VERSION ""

NS_ :

BS_:

BU_: PPIM HCP VDCM APM2 SGW IDCM EVCU2 BPCM

BO_ 1835 HVBATTERY_RM_CELLS1: 64 BPCM
 SG_ HVBatCellVoltage_Cell027 : 420|13@0+ (0.001,0) [0|5] "V"  SGW
 SG_ HVBatCellVoltage_Cell026 : 404|13@0+ (0.001,0) [0|5] "V"  SGW
 SG_ HVBatCellVoltage_Cell025 : 388|13@0+ (0.001,0) [0|5] "V"  SGW
 SG_ HVBatCellVoltage_Cell024 : 372|13@0+ (0.001,0) [0|5] "V"  SGW
 SG_ HVBatCellVoltage_Cell023 : 356|13@0+ (0.001,0) [0|5] "V"  SGW
 SG_ HVBatCellVoltage_Cell022 : 340|13@0+ (0.001,0) [0|5] "V"  SGW
 SG_ HVBatCellVoltage_Cell021 : 324|13@0+ (0.001,0) [0|5] "V"  SGW
 SG_ HVBatCellVoltage_Cell020 : 308|13@0+ (0.001,0) [0|5] "V"  SGW
 SG_ HVBatCellVoltage_Cell019 : 292|13@0+ (0.001,0) [0|5] "V"  SGW
 SG_ HVBatCellVoltage_Cell018 : 276|13@0+ (0.001,0) [0|5] "V"  SGW
 SG_ HVBatCellVoltage_Cell017 : 260|13@0+ (0.001,0) [0|5] "V"  SGW
 SG_ HVBatCellVoltage_Cell016 : 244|13@0+ (0.001,0) [0|5] "V"  SGW
 SG_ HVBatCellVoltage_Cell015 : 228|13@0+ (0.001,0) [0|5] "V"  SGW
 SG_ HVBatCellVoltage_Cell014 : 212|13@0+ (0.001,0) [0|5] "V"  SGW
 SG_ HVBatCellVoltage_Cell013 : 196|13@0+ (0.001,0) [0|5] "V"  SGW
 SG_ HVBatCellVoltage_Cell012 : 180|13@0+ (0.001,0) [0|5] "V"  SGW
 SG_ HVBatCellVoltage_Cell011 : 164|13@0+ (0.001,0) [0|5] "V"  SGW
 SG_ HVBatCellVoltage_Cell010 : 148|13@0+ (0.001,0) [0|5] "V"  SGW
 SG_ HVBatCellVoltage_Cell009 : 132|13@0+ (0.001,0) [0|5] "V"  SGW
 SG_ HVBatCellVoltage_Cell008 : 116|13@0+ (0.001,0) [0|5] "V"  SGW
 SG_ HVBatCellVoltage_Cell007 : 100|13@0+ (0.001,0) [0|5] "V"  SGW
 SG_ HVBatCellVoltage_Cell006 : 84|13@0+ (0.001,0) [0|5] "V"  SGW
 SG_ HVBatCellVoltage_Cell005 : 68|13@0+ (0.001,0) [0|5] "V"  SGW
 SG_ HVBatCellVoltage_Cell004 : 52|13@0+ (0.001,0) [0|5] "V"  SGW
 SG_ HVBatCellVoltage_Cell003 : 36|13@0+ (0.001,0) [0|5] "V"  SGW
 SG_ HVBatCellVoltage_Cell002 : 20|13@0+ (0.001,0) [0|5] "V"  SGW
 SG_ HVBatCellVoltage_Cell001 : 4|13@0+ (0.001,0) [0|5] "V"  SGW

BO_ 1035 ENGINE_HYBD_FD_3: 32 HCP
 SG_ RadFanReq : 158|7@0+ (1,0) [0|100] "%"  BPCM
 SG_ EngSpd : 7|16@0+ (0.125,0) [0|8160] "rpm"  BPCM
 SG_ EngCltTmpV : 69|1@0+ (1,0) [0|1] "" BPCM
 SG_ EngCltTmp : 167|8@0+ (1,-40) [-40|214] "°C"  BPCM

BO_ 750 BCM_FD_3: 32 EVCU2
 SG_ Battery_Volt_1 : 56|9@0+ (0.025,5) [5|17.75] "Volt"  PPIM,APM2,IDCM,BPCM

BO_ 1436 BCM_FD_27: 32 HCP
 SG_ Blower_Speed : 136|9@0+ (1,0) [0|350] "Hz"  BPCM

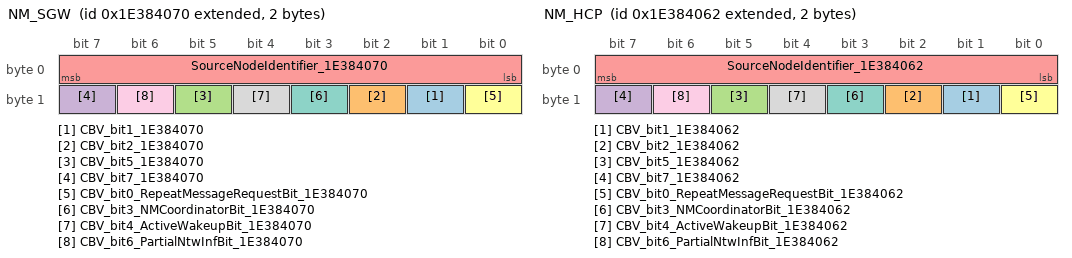
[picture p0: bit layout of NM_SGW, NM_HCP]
BO_ 2654486640 NM_SGW: 2 SGW
 SG_ CBV_bit1_1E384070 : 9|1@0+ (1,0) [0|1] "" EVCU2,APM2,IDCM,BPCM,HCP
 SG_ CBV_bit2_1E384070 : 10|1@0+ (1,0) [0|1] "" EVCU2,APM2,IDCM,BPCM,HCP
 SG_ CBV_bit5_1E384070 : 13|1@0+ (1,0) [0|1] "" EVCU2,APM2,IDCM,BPCM,HCP
 SG_ CBV_bit7_1E384070 : 15|1@0+ (1,0) [0|1] "" EVCU2,APM2,IDCM,BPCM,HCP
 SG_ SourceNodeIdentifier_1E384070 : 7|8@0+ (1,0) [0|255] "-"  EVCU2,APM2,IDCM,BPCM,HCP
 SG_ CBV_bit0_RepeatMessageRequestBit_1E384070 : 8|1@0+ (1,0) [0|1] "" EVCU2,APM2,IDCM,BPCM,HCP
 SG_ CBV_bit3_NMCoordinatorBit_1E384070 : 11|1@0+ (1,0) [0|1] "" EVCU2,APM2,IDCM,BPCM,HCP
 SG_ CBV_bit4_ActiveWakeupBit_1E384070 : 12|1@0+ (1,0) [0|1] "" EVCU2,APM2,IDCM,BPCM,HCP
 SG_ CBV_bit6_PartialNtwInfBit_1E384070 : 14|1@0+ (1,0) [0|1] "" EVCU2,APM2,IDCM,BPCM,HCP

BO_ 2654486626 NM_HCP: 2 HCP
 SG_ CBV_bit1_1E384062 : 9|1@0+ (1,0) [0|1] "" PPIM,EVCU2,IDCM,SGW,BPCM
 SG_ CBV_bit2_1E384062 : 10|1@0+ (1,0) [0|1] "" PPIM,EVCU2,IDCM,SGW,BPCM
 SG_ CBV_bit5_1E384062 : 13|1@0+ (1,0) [0|1] "" PPIM,EVCU2,IDCM,SGW,BPCM
 SG_ CBV_bit7_1E384062 : 15|1@0+ (1,0) [0|1] "" PPIM,EVCU2,IDCM,SGW,BPCM
 SG_ SourceNodeIdentifier_1E384062 : 7|8@0+ (1,0) [0|255] "-"  PPIM,EVCU2,IDCM,SGW,BPCM
 SG_ CBV_bit0_RepeatMessageRequestBit_1E384062 : 8|1@0+ (1,0) [0|1] "" PPIM,EVCU2,IDCM,SGW,BPCM
 SG_ CBV_bit3_NMCoordinatorBit_1E384062 : 11|1@0+ (1,0) [0|1] "" PPIM,EVCU2,IDCM,SGW,BPCM
 SG_ CBV_bit4_ActiveWakeupBit_1E384062 : 12|1@0+ (1,0) [0|1] "" PPIM,EVCU2,IDCM,SGW,BPCM
 SG_ CBV_bit6_PartialNtwInfBit_1E384062 : 14|1@0+ (1,0) [0|1] "" PPIM,EVCU2,IDCM,SGW,BPCM

BO_ 276 HYBRID_POWERTRAIN1: 64 EVCU2
 SG_ HEV_ESS_Mode : 271|4@0+ (1,0) [0|0] "-"  BPCM
 SG_ PropulsionSystemActive_114 : 408|1@0+ (1,0) [0|1] "-"  BPCM

BO_ 262 ENGINE_FD_2: 64 EVCU2
 SG_ PowertrainPrplsnActv : 181|1@0+ (1,0) [0|1] "" IDCM,BPCM
 SG_ EngineSpeed_W : 21|14@0+ (1,0) [0|16382] "1/min"  PPIM,IDCM,BPCM

BO_ 258 BRAKE_FD_2: 64 EVCU2
 SG_ VehicleSpeedVSOSig : 4|13@0+ (0.0625,0) [0|511.875] "Km/h"  PPIM,APM2,IDCM,BPCM

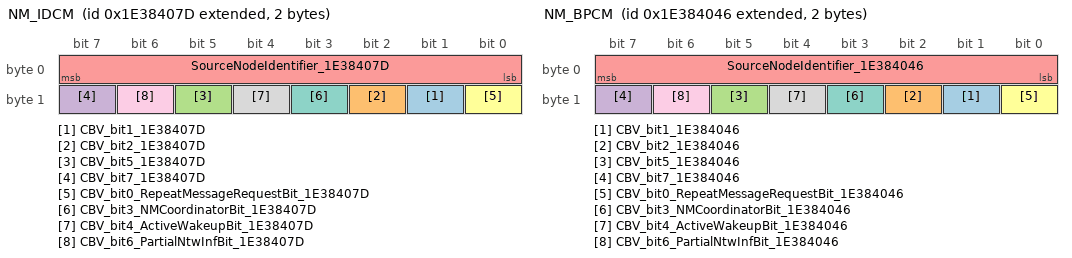
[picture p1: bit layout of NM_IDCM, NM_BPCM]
BO_ 2654486653 NM_IDCM: 2 IDCM
 SG_ CBV_bit1_1E38407D : 9|1@0+ (1,0) [0|1] "" PPIM,EVCU2,APM2,SGW,BPCM,HCP
 SG_ CBV_bit2_1E38407D : 10|1@0+ (1,0) [0|1] "" PPIM,EVCU2,APM2,SGW,BPCM,HCP
 SG_ CBV_bit5_1E38407D : 13|1@0+ (1,0) [0|1] "" PPIM,EVCU2,APM2,SGW,BPCM,HCP
 SG_ CBV_bit7_1E38407D : 15|1@0+ (1,0) [0|1] "" PPIM,EVCU2,APM2,SGW,BPCM,HCP
 SG_ SourceNodeIdentifier_1E38407D : 7|8@0+ (1,0) [0|255] "-"  PPIM,EVCU2,APM2,SGW,BPCM,HCP
 SG_ CBV_bit0_RepeatMessageRequestBit_1E38407D : 8|1@0+ (1,0) [0|1] "" PPIM,EVCU2,APM2,SGW,BPCM,HCP
 SG_ CBV_bit3_NMCoordinatorBit_1E38407D : 11|1@0+ (1,0) [0|1] "" PPIM,EVCU2,APM2,SGW,BPCM,HCP
 SG_ CBV_bit4_ActiveWakeupBit_1E38407D : 12|1@0+ (1,0) [0|1] "" PPIM,EVCU2,APM2,SGW,BPCM,HCP
 SG_ CBV_bit6_PartialNtwInfBit_1E38407D : 14|1@0+ (1,0) [0|1] "" PPIM,EVCU2,APM2,SGW,BPCM,HCP

BO_ 2654486598 NM_BPCM: 2 BPCM
 SG_ CBV_bit1_1E384046 : 9|1@0+ (1,0) [0|1] "" EVCU2,APM2,IDCM,SGW,HCP
 SG_ CBV_bit2_1E384046 : 10|1@0+ (1,0) [0|1] "" EVCU2,APM2,IDCM,SGW,HCP
 SG_ CBV_bit5_1E384046 : 13|1@0+ (1,0) [0|1] "" EVCU2,APM2,IDCM,SGW,HCP
 SG_ CBV_bit7_1E384046 : 15|1@0+ (1,0) [0|1] "" EVCU2,APM2,IDCM,SGW,HCP
 SG_ SourceNodeIdentifier_1E384046 : 7|8@0+ (1,0) [0|255] "-"  EVCU2,APM2,IDCM,SGW,HCP
 SG_ CBV_bit0_RepeatMessageRequestBit_1E384046 : 8|1@0+ (1,0) [0|1] "" EVCU2,APM2,IDCM,SGW,HCP
 SG_ CBV_bit3_NMCoordinatorBit_1E384046 : 11|1@0+ (1,0) [0|1] "" EVCU2,APM2,IDCM,SGW,HCP
 SG_ CBV_bit4_ActiveWakeupBit_1E384046 : 12|1@0+ (1,0) [0|1] "" EVCU2,APM2,IDCM,SGW,HCP
 SG_ CBV_bit6_PartialNtwInfBit_1E384046 : 14|1@0+ (1,0) [0|1] "" EVCU2,APM2,IDCM,SGW,HCP

BO_ 1579 HYBRID_CHARGING_STATUS: 32 EVCU2
 SG_ HVBatteryVoltage_MinCal : 32|9@0+ (1,0) [0|510] "V"  IDCM,BPCM
 SG_ HVBatteryVoltage_MaxCal : 16|9@0+ (1,0) [0|510] "V"  IDCM,BPCM
 SG_ HVBatteryCurrent_MaxCal : 63|8@0+ (0.25,-32) [-32|31.5] "Amp"  IDCM,BPCM
 SG_ ChargeSystemFaultReason : 55|8@0+ (1,0) [0|254] "-"  IDCM
 SG_ ACCurrent_MaxCal : 0|9@0+ (0.25,-31.5) [-31.5|50] "Amp"  IDCM,BPCM
 SG_ ChargingLevel : 4|4@0+ (1,0) [0|14] "-"  IDCM,SGW,BPCM
 SG_ OBCM_PLUG_STS : 23|2@0+ (1,0) [0|3] "" IDCM
 SG_ VDCM_UDCChrgr : 71|16@0+ (0.1,0) [0|6553.5] "V"  IDCM
 SG_ VDCM_IDCChrgr : 87|16@0+ (0.1,0) [0|6553.5] "A"  IDCM
 SG_ ChargeSystemSts : 7|3@0+ (1,0) [0|6] "-"  IDCM,BPCM
 SG_ ChargeSystemFault : 17|1@0+ (1,0) [0|1] "-"  IDCM
 SG_ CRC_HYBRID_CHARGING_STATUS : 191|8@0+ (1,0) [0|255] "-"  IDCM
 SG_ MessageCounter_HYBRID_CHARGING__62B : 179|4@0+ (1,0) [0|15] "-"  IDCM

BO_ 478 HYBRID_CHARGING_COMMAND: 32 EVCU2
 SG_ LVDC_VoltageSetpoint : 111|8@0+ (0.0625,0) [0|15.875] "V"  BPCM
 SG_ LVDC_SystemVoltageAct : 64|9@0+ (0.04,0) [0|20.04] "V"  BPCM
 SG_ LVDC_CurrentSetpoint : 32|9@0+ (1,-255) [-255|255] "Amp"  BPCM
 SG_ HVInverterVoltage_Rational : 16|9@0+ (1,0) [0|510] "V"  BPCM
 SG_ HVDC_VoltageSetpoint : 48|9@0+ (1,0) [0|510] "V"  BPCM
 SG_ HVDC_CurrentSetpoint : 103|8@0+ (1,-125) [-125|129] "Amp"  BPCM
 SG_ EchargeSOCRange_ePT : 118|7@0+ (1,0) [0|100] "%"  Vector__XXX
 SG_ CRC_HYBRID_CHARGING_COMMAND : 191|8@0+ (1,0) [0|255] "-"  IDCM,BPCM
 SG_ VoltageRequest : 4|13@0+ (0.1,0) [0|819.1] "Volts"  IDCM
 SG_ OBC_ModeRequest : 23|3@0+ (1,0) [0|6] "-"  IDCM
 SG_ OBC_ControlMethod : 38|2@0+ (1,0) [0|2] "-"  IDCM
 SG_ MainHV_ContactorCommand : 7|3@0+ (1,0) [0|7] "-"  BPCM
 SG_ J1772_CloseS2 : 51|1@0+ (1,0) [0|1] "-"  IDCM
 SG_ HVInverterVoltage_RationalV : 39|1@0+ (1,0) [0|1] "-"  BPCM
 SG_ HVBatCoolantLevelLow : 50|2@0+ (1,0) [0|2] "-"  BPCM
 SG_ DCDC_OperationModeEnable : 20|4@0+ (1,0) [0|14] "-"  BPCM
 SG_ ClearLegislatedDiagInfo : 52|1@0+ (1,0) [0|1] "-"  BPCM
 SG_ OBC_OperativeModeReq : 87|4@0+ (1,0) [0|14] "-"  IDCM
 SG_ HV_Volt_Min_Thrsh : 138|11@0+ (1,0) [0|2047] "V"  IDCM
 SG_ HV_Volt_Max_Thrsh : 133|11@0+ (1,0) [0|2047] "V"  IDCM
 SG_ DC_Curr_Max_Thrsh : 127|10@0+ (1,-511) [-511|512] "A"  IDCM
 SG_ ChargeEnable : 171|2@0+ (1,0) [0|2] "-"  IDCM
 SG_ AC_Curr_Min_Thrsh : 165|10@0+ (1,-511) [-511|512] "A"  IDCM
 SG_ AC_Curr_Max_Thrsh : 159|10@0+ (1,-511) [-511|512] "A"  IDCM
 SG_ CurrentRequest : 81|10@0+ (0.1,-32) [-32|70.3] "A"  IDCM
 SG_ VDCM_StsWldgReq : 83|1@0+ (1,0) [0|1] "-"  IDCM
 SG_ VDCM_SessnStopReq : 82|1@0+ (1,0) [0|1] "-"  IDCM
 SG_ VDCM_StsSWWldgReq : 55|2@0+ (1,0) [0|3] "-"  APM2
 SG_ MessageCounter_HYBRID_CHARGING__1DE : 179|4@0+ (1,0) [0|15] "-"  IDCM,BPCM
 SG_ MaxCurrentAllwd : 71|6@0+ (1,0) [0|63] "A"  IDCM

BO_ 1578 HV_CHARGER2: 32 IDCM
 SG_ OBC_IdleTimeSec : 71|16@0+ (3,0) [0|196602] "sec"  EVCU2
 SG_ OBC_IdleTimeMin : 87|16@0+ (1,0) [0|65534] "min"  EVCU2
 SG_ OBC_ChargeTimeSec : 39|16@0+ (3,0) [0|196602] "sec"  EVCU2
 SG_ OBC_ChargeTimeMin : 55|16@0+ (1,0) [0|65534] "min"  EVCU2
 SG_ Charging_WHr : 23|16@0+ (1,0) [0|65534] "WHr"  EVCU2
 SG_ OnboardChargerReady : 116|2@0+ (1,0) [0|2] "-"  EVCU2
 SG_ OnboardChargerMode : 114|4@0+ (1,0) [0|15] "-"  EVCU2
 SG_ OBC_WakeReason : 107|4@0+ (1,0) [0|7] "-"  EVCU2
 SG_ OBC_GenericFailSts : 125|1@0+ (1,0) [0|1] "-"  EVCU2
 SG_ OBC_FaultReason : 102|7@0+ (1,0) [0|126] "-"  EVCU2
 SG_ OBC_EVServiceLampOn : 124|1@0+ (1,0) [0|1] "-"  EVCU2
 SG_ OBC_EVServiceLampFlash : 123|1@0+ (1,0) [0|1] "-"  EVCU2
 SG_ OBC_CurrentFailureSts : 121|1@0+ (1,0) [0|1] "-"  EVCU2
 SG_ OBC_ChargingFaultSts : 110|3@0+ (1,0) [0|7] "-"  EVCU2
 SG_ OBC_ChargeFailure : 120|1@0+ (1,0) [0|1] "-"  EVCU2
 SG_ OBC_CaptureEnvironmentData : 119|1@0+ (1,0) [0|1] "-"  EVCU2
 SG_ ACplug_PwrMax : 7|16@0+ (1,-32767) [-32767|32767] "W"  EVCU2
 SG_ OBC_Prox : 159|8@0+ (0.05,0) [0|12.75] "V"  EVCU2
 SG_ OBC_Pilot : 151|8@0+ (0.05,0) [0|12.75] "V"  EVCU2
 SG_ OBCM_PrechargeSts : 167|2@0+ (1,0) [0|3] "-"  EVCU2
 SG_ ChrgFailSts : 165|3@0+ (1,0) [0|7] "" EVCU2
 SG_ CRC_HV_CHARGER2 : 191|8@0+ (1,0) [0|255] "-"  EVCU2
 SG_ MessageCounter_HV_CHARGER2 : 179|4@0+ (1,0) [0|15] "-"  EVCU2

BO_ 1372 DUALCHARGER_THERMAL: 32 IDCM
 SG_ OBC_Temp4 : 63|8@0+ (1,-40) [-40|214] "°C"  EVCU2
 SG_ OBC_Temp3 : 55|8@0+ (1,-40) [-40|214] "°C"  EVCU2
 SG_ OBC_Temp2 : 47|8@0+ (1,-40) [-40|214] "°C"  EVCU2
 SG_ OBC_Temp1 : 39|8@0+ (1,-40) [-40|214] "°C"  EVCU2

BO_ 2564682064 DIAGNOSTIC_ROE_IDCM: 8 IDCM
 SG_ N_PDU_18DDF150 : 7|64@0+ (1,0) [0|0] "" SGW

BO_ 2564682059 DIAGNOSTIC_ROE_HCP: 8 HCP
 SG_ N_PDU_18DDF14B : 7|64@0+ (1,0) [0|0] "" SGW

BO_ 2564682320 DIAGNOSTIC_ROE_FD_IDCM: 64 IDCM
 SG_ N_PDU_18DDF250 : 7|64@0+ (1,0) [0|0] "" SGW

BO_ 2564682315 DIAGNOSTIC_ROE_FD_HCP: 64 HCP
 SG_ N_PDU_18DDF24B : 7|64@0+ (1,0) [0|0] "" SGW

BO_ 2564682308 DIAGNOSTIC_ROE_FD_BPCM: 64 BPCM
 SG_ N_PDU_18DDF244 : 7|64@0+ (1,0) [0|0] "" SGW,HCP

BO_ 2564682052 DIAGNOSTIC_ROE_BPCM: 8 BPCM
 SG_ N_PDU_18DDF144 : 7|64@0+ (1,0) [0|0] "" SGW

BO_ 2564485712 DIAGNOSTIC_RESPONSE_FD_IDCM: 64 IDCM
 SG_ N_PDU_18DAF250 : 7|64@0+ (1,0) [0|0] "" SGW

BO_ 2564485707 DIAGNOSTIC_RESPONSE_FD_HCP: 64 HCP
 SG_ N_PDU_18DAF24B : 7|64@0+ (1,0) [0|0] "" SGW

BO_ 2564485700 DIAGNOSTIC_RESPONSE_FD_BPCM: 64 BPCM
 SG_ N_PDU_18DAF244 : 7|64@0+ (1,0) [0|0] "" SGW,HCP

BO_ 2564444402 DIAGNOSTIC_REQUEST_FD_IDCM: 64 SGW
 SG_ N_PDU_18DA50F2 : 7|64@0+ (1,0) [0|0] "" IDCM

BO_ 2564443122 DIAGNOSTIC_REQUEST_FD_HCP: 64 SGW
 SG_ N_PDU_18DA4BF2 : 7|64@0+ (1,0) [0|0] "" HCP

BO_ 2564441330 DIAGNOSTIC_REQUEST_FD_BPCM: 64 SGW
 SG_ N_PDU_18DA44F2 : 7|64@0+ (1,0) [0|0] "" BPCM

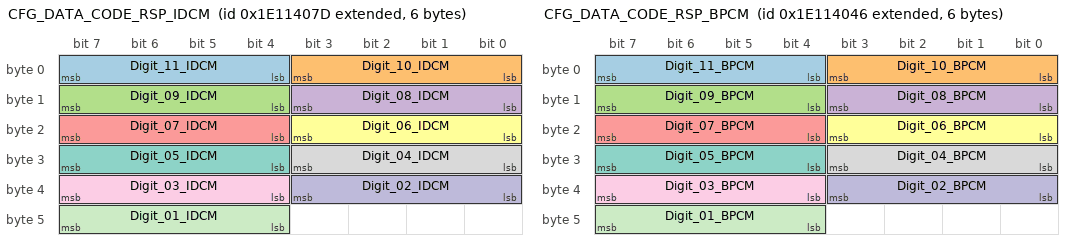
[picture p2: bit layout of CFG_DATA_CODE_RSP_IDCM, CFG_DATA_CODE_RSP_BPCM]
BO_ 2651930749 CFG_DATA_CODE_RSP_IDCM: 6 IDCM
 SG_ Digit_11_IDCM : 7|4@0+ (1,0) [0|15] "-"  EVCU2
 SG_ Digit_10_IDCM : 3|4@0+ (1,0) [0|15] "-"  EVCU2
 SG_ Digit_09_IDCM : 15|4@0+ (1,0) [0|15] "-"  EVCU2
 SG_ Digit_08_IDCM : 11|4@0+ (1,0) [0|15] "-"  EVCU2
 SG_ Digit_07_IDCM : 23|4@0+ (1,0) [0|15] "-"  EVCU2
 SG_ Digit_06_IDCM : 19|4@0+ (1,0) [0|15] "-"  EVCU2
 SG_ Digit_05_IDCM : 31|4@0+ (1,0) [0|15] "-"  EVCU2
 SG_ Digit_04_IDCM : 27|4@0+ (1,0) [0|15] "-"  EVCU2
 SG_ Digit_03_IDCM : 39|4@0+ (1,0) [0|15] "-"  EVCU2
 SG_ Digit_02_IDCM : 35|4@0+ (1,0) [0|15] "-"  EVCU2
 SG_ Digit_01_IDCM : 47|4@0+ (1,0) [0|15] "-"  EVCU2

BO_ 2651930694 CFG_DATA_CODE_RSP_BPCM: 6 BPCM
 SG_ Digit_11_BPCM : 7|4@0+ (1,0) [0|15] "-"  EVCU2,HCP
 SG_ Digit_10_BPCM : 3|4@0+ (1,0) [0|15] "-"  EVCU2,HCP
 SG_ Digit_09_BPCM : 15|4@0+ (1,0) [0|15] "-"  EVCU2,HCP
 SG_ Digit_08_BPCM : 11|4@0+ (1,0) [0|15] "-"  EVCU2,HCP
 SG_ Digit_07_BPCM : 23|4@0+ (1,0) [0|15] "-"  EVCU2,HCP
 SG_ Digit_06_BPCM : 19|4@0+ (1,0) [0|15] "-"  EVCU2,HCP
 SG_ Digit_05_BPCM : 31|4@0+ (1,0) [0|15] "-"  EVCU2,HCP
 SG_ Digit_04_BPCM : 27|4@0+ (1,0) [0|15] "-"  EVCU2,HCP
 SG_ Digit_03_BPCM : 39|4@0+ (1,0) [0|15] "-"  EVCU2,HCP
 SG_ Digit_02_BPCM : 35|4@0+ (1,0) [0|15] "-"  EVCU2,HCP
 SG_ Digit_01_BPCM : 47|4@0+ (1,0) [0|15] "-"  EVCU2,HCP

BO_ 2654339170 PDC_INFO_FD_HCP: 12 HCP
 SG_ GenericFailSts_FD03_HCP : 5|1@0+ (1,0) [0|1] "" SGW
 SG_ EOL_FD03_HCP : 7|1@0+ (1,0) [0|1] "-"  SGW
 SG_ CurrentFailSts_FD03_HCP : 6|1@0+ (1,0) [0|1] "" SGW
 SG_ WakeupSource_FD03_HCP : 23|8@0+ (1,0) [0|255] "" SGW
 SG_ PreviousCanNMState_FD03_HCP : 11|4@0+ (1,0) [0|15] "" SGW
 SG_ DES_FD03_HCP : 4|2@0+ (1,0) [0|3] "" SGW
 SG_ CurrentCanNMState_FD03_HCP : 15|4@0+ (1,0) [0|15] "" SGW
 SG_ StayActiveSource_FD03_HCP : 31|64@0+ (1,0) [0|18446744073709600000] "" SGW

BO_ 1845 HVBATTERY_RM_BATTERYID: 64 BPCM
 SG_ HVBatSerialLength : 199|8@0+ (1,0) [0|254] "" SGW
 SG_ HVBatSerialNumber : 7|192@0+ (1,0) [0|0] "" SGW

BO_ 1460 FOTA_MASTER: 32 SGW
 SG_ FOTA_Status : 7|4@0+ (1,0) [0|15] "" EVCU2,IDCM,BPCM
 SG_ MessageCounter_FOTA_MASTER : 179|4@0+ (1,0) [0|15] "-"  EVCU2
 SG_ CRC_FOTA_MASTER : 191|8@0+ (1,0) [0|255] "-"  EVCU2

BO_ 1374 HVBATTERY4: 48 BPCM
 SG_ HVBatPackVoltage_MaxAllowedV : 6|1@0+ (1,0) [0|0] "-"  HCP
 SG_ HVBatCellVoltage_MinAllowedV : 5|1@0+ (1,0) [0|0] "-"  HCP
 SG_ HVBatCellVoltage_MinAllowed : 19|12@0+ (0.001,1.5) [1.5|4.5] "Volts"  HCP
 SG_ HVBatCellVoltage_MaxAllowedV : 4|1@0+ (1,0) [0|0] "-"  HCP
 SG_ HVBatCellVoltage_MaxAllowed : 3|12@0+ (0.001,1.5) [1.5|4.5] "Volts"  HCP
 SG_ HVBatCellVoltage_LowThreshold : 84|13@0+ (0.001,0) [0|5] "Volts"  HCP
 SG_ HVBatCellVoltage_HighThreshold : 68|13@0+ (0.001,0) [0|5] "Volts"  HCP
 SG_ HVBatCapacity_AmpHrV : 22|1@0+ (1,0) [0|0] "-"  Vector__XXX
 SG_ HVBatCapacity_AmpHr : 114|11@0+ (0.1,0) [0|200] "Ah"  Vector__XXX
 SG_ MessageCounter_HVBATTERY4 : 307|4@0+ (1,0) [0|15] "-"  HCP
 SG_ CRC_HVBATTERY4 : 319|8@0+ (1,0) [0|255] "-"  HCP
 SG_ HVBatRemainingAhCapacity : 186|11@0+ (0.1,0) [0|200] "Ah"  HCP
 SG_ HVBatDischargeAmpHrs : 167|24@0+ (0.1,0) [0|300000] "Ah"  HCP
 SG_ HVBatChargeAmpHrs : 143|24@0+ (0.1,0) [0|300000] "Ah"  HCP
 SG_ BSGPackVoltage_MaxAllowed : 39|7@0+ (1,0) [20|70] "V"  HCP

BO_ 1038 HVBATTERY_STATUS: 32 BPCM
 SG_ Precharge_Closed : 121|1@0+ (1,0) [0|1] "" HCP
 SG_ Positive_Main_Closed : 122|1@0+ (1,0) [0|1] "" HCP
 SG_ Negative_Main_Closed : 123|1@0+ (1,0) [0|1] "" HCP
 SG_ HBCO_TempSensorRationality : 125|1@0+ (1,0) [0|1] "" HCP
 SG_ HBCO_Sensor_Fault : 126|1@0+ (1,0) [0|1] "" HCP
 SG_ HBCO_PackUndertemp : 105|1@0+ (1,0) [0|1] "" HCP
 SG_ HBCO_PackOvertemp : 106|1@0+ (1,0) [0|1] "" HCP
 SG_ HBCO_OverCurrent : 127|1@0+ (1,0) [0|1] "" HCP
 SG_ HBCO_Micro_Failure : 112|1@0+ (1,0) [0|1] "" HCP
 SG_ HBCO_Main_Fuse_Failure : 113|1@0+ (1,0) [0|1] "" HCP
 SG_ HBCO_Isolation_Fault : 114|1@0+ (1,0) [0|1] "" HCP
 SG_ HBCO_Internal_CommFault : 117|1@0+ (1,0) [0|1] "" HCP
 SG_ HBCO_Impact_Detected : 115|1@0+ (1,0) [0|1] "" HCP
 SG_ HBCO_HVIL_Failure : 116|1@0+ (1,0) [0|1] "" HCP
 SG_ HBCO_External_CommFault : 118|1@0+ (1,0) [0|1] "" HCP
 SG_ HBCO_CellUndervoltage : 119|1@0+ (1,0) [0|1] "" HCP
 SG_ HBCO_CellOvervoltage : 104|1@0+ (1,0) [0|1] "" HCP
 SG_ HBCO_12V_Low : 107|1@0+ (1,0) [0|1] "" HCP
 SG_ HBCO_12V_High : 108|1@0+ (1,0) [0|1] "" HCP
 SG_ HBCNC_TempSensorRationality : 110|1@0+ (1,0) [0|1] "" HCP
 SG_ HBCNC_SOH_Failure : 111|1@0+ (1,0) [0|1] "" HCP
 SG_ HBCNC_Sensor_Failure : 96|1@0+ (1,0) [0|1] "" HCP
 SG_ HBCNC_Precharge_Failure : 97|1@0+ (1,0) [0|1] "" HCP
 SG_ HBCNC_PackUndervoltage : 98|1@0+ (1,0) [0|1] "" HCP
 SG_ HBCNC_PackUndertemp : 93|1@0+ (1,0) [0|1] "" HCP
 SG_ HBCNC_PackOvervoltage : 99|1@0+ (1,0) [0|1] "" HCP
 SG_ HBCNC_PackOvertemp : 94|1@0+ (1,0) [0|1] "" HCP
 SG_ HBCNC_Micro_Failure : 100|1@0+ (1,0) [0|1] "" HCP
 SG_ HBCNC_Main_Fuse_Failure : 101|1@0+ (1,0) [0|1] "" HCP
 SG_ HBCNC_Isolation_Fault : 102|1@0+ (1,0) [0|1] "" HCP
 SG_ HBCNC_Internal_CommFault : 89|1@0+ (1,0) [0|1] "" HCP
 SG_ HBCNC_Impact_Detected : 103|1@0+ (1,0) [0|1] "" HCP
 SG_ HBCNC_External_CommFault : 90|1@0+ (1,0) [0|1] "" HCP
 SG_ HBCNC_EEPROM_Fault : 88|1@0+ (1,0) [0|1] "" HCP
 SG_ HBCNC_Contactors_Welded : 109|1@0+ (1,0) [0|1] "" HCP
 SG_ HBCNC_CellUndervoltage : 91|1@0+ (1,0) [0|1] "" HCP
 SG_ HBCNC_CellOvervoltage : 92|1@0+ (1,0) [0|1] "" HCP
 SG_ HBCNC_12V_Low : 95|1@0+ (1,0) [0|1] "" HCP
 SG_ HBCNC_12V_High : 38|1@0+ (1,0) [0|1] "" HCP
 SG_ BPCM_DTC_Status6 : 87|3@0+ (1,0) [0|6] "" HCP
 SG_ BPCM_DTC_Status5 : 79|3@0+ (1,0) [0|6] "" HCP
 SG_ BPCM_DTC_Status4 : 71|3@0+ (1,0) [0|6] "" HCP
 SG_ BPCM_DTC_Status3 : 63|3@0+ (1,0) [0|6] "" HCP
 SG_ BPCM_DTC_Status2 : 55|3@0+ (1,0) [0|6] "" HCP
 SG_ BPCM_DTC_Status1 : 47|3@0+ (1,0) [0|6] "" HCP
 SG_ BPCM_DTC_Index6 : 84|5@0+ (1,0) [0|31] "" HCP
 SG_ BPCM_DTC_Index5 : 76|5@0+ (1,0) [0|31] "" HCP
 SG_ BPCM_DTC_Index4 : 68|5@0+ (1,0) [0|31] "" HCP
 SG_ BPCM_DTC_Index3 : 60|5@0+ (1,0) [0|31] "" HCP
 SG_ BPCM_DTC_Index2 : 52|5@0+ (1,0) [0|31] "" HCP
 SG_ BPCM_DTC_Index1 : 44|5@0+ (1,0) [0|31] "" HCP
 SG_ BPCM_CalibrationVN : 31|8@0+ (1,0) [0|255] "" HCP
 SG_ BPCM_CalibrationID : 37|6@0+ (1,0) [0|62] "" HCP
 SG_ BPCM_Odometer : 7|24@0+ (0.1,0) [0|1677720] "km"  HCP

BO_ 2654339223 PDC_INFO_FD_APM2: 12 APM2
 SG_ WakeupSource_FD11_APM2 : 23|8@0+ (1,0) [0|255] "" EVCU2,SGW
 SG_ PreviousCanNMState_FD11_APM2 : 11|4@0+ (1,0) [0|15] "" EVCU2,SGW
 SG_ GenericFailSts_FD11_APM2 : 5|1@0+ (1,0) [0|1] "" EVCU2,SGW
 SG_ EOL_FD11_APM2 : 7|1@0+ (1,0) [0|1] "-"  EVCU2,SGW
 SG_ DES_FD11_APM2 : 4|2@0+ (1,0) [0|3] "" EVCU2,SGW
 SG_ CurrentFailSts_FD11_APM2 : 6|1@0+ (1,0) [0|1] "" EVCU2,SGW
 SG_ CurrentCanNMState_FD11_APM2 : 15|4@0+ (1,0) [0|15] "" EVCU2,SGW
 SG_ StayActiveSource_FD11_APM2 : 31|64@0+ (1,0) [0|18446744073709551615] "" EVCU2,SGW

BO_TX_BU_ 750 : EVCU2,HCP;
BO_TX_BU_ 276 : EVCU2,HCP;
BO_TX_BU_ 262 : EVCU2,HCP;
BO_TX_BU_ 258 : EVCU2,HCP;
BO_TX_BU_ 478 : EVCU2,HCP;
CM_ SG_ 2654339170 GenericFailSts_FD03_HCP "Indicates the presence/absent of at least one DTC in the System Memory";
CM_ SG_ 2654339170 EOL_FD03_HCP "Indicates if the ECU requires configuration data at the assembly plant End Of Line";
CM_ SG_ 2654339170 CurrentFailSts_FD03_HCP "Indicates the presence/absence of at least one DTC with DTCStatus = present in the System Memory";
CM_ SG_ 1835 HVBatCellVoltage_Cell027 "High voltage battery cell voltage for Cell 27";
CM_ SG_ 1835 HVBatCellVoltage_Cell026 "High voltage battery cell voltage for Cell 26";
CM_ SG_ 1835 HVBatCellVoltage_Cell025 "High voltage battery cell voltage for Cell 25";
CM_ SG_ 1835 HVBatCellVoltage_Cell024 "High voltage battery cell voltage for Cell 24";
CM_ SG_ 1835 HVBatCellVoltage_Cell023 "High voltage battery cell voltage for Cell 23";
CM_ SG_ 1835 HVBatCellVoltage_Cell022 "High voltage battery cell voltage for Cell 22";
CM_ SG_ 1835 HVBatCellVoltage_Cell021 "High voltage battery cell voltage for Cell 21";
CM_ SG_ 1835 HVBatCellVoltage_Cell020 "High voltage battery cell voltage for Cell 20";
CM_ SG_ 1835 HVBatCellVoltage_Cell019 "High voltage battery cell voltage for Cell 19";
CM_ SG_ 1835 HVBatCellVoltage_Cell018 "High voltage battery cell voltage for Cell 18";
CM_ SG_ 1835 HVBatCellVoltage_Cell017 "High voltage battery cell voltage for Cell 17";
CM_ SG_ 1835 HVBatCellVoltage_Cell016 "High voltage battery cell voltage for Cell 16";
CM_ SG_ 1835 HVBatCellVoltage_Cell015 "High voltage battery cell voltage for Cell 15";
CM_ SG_ 1835 HVBatCellVoltage_Cell014 "High voltage battery cell voltage for Cell 14";
CM_ SG_ 1835 HVBatCellVoltage_Cell013 "High voltage battery cell voltage for Cell 13";
CM_ SG_ 1835 HVBatCellVoltage_Cell012 "High voltage battery cell voltage for Cell 12";
CM_ SG_ 1835 HVBatCellVoltage_Cell011 "High voltage battery cell voltage for Cell 11";
CM_ SG_ 1835 HVBatCellVoltage_Cell010 "High voltage battery cell voltage for Cell 10";
CM_ SG_ 1835 HVBatCellVoltage_Cell009 "High voltage battery cell voltage for Cell 09";
CM_ SG_ 1835 HVBatCellVoltage_Cell008 "High voltage battery cell voltage for Cell 08";
CM_ SG_ 1835 HVBatCellVoltage_Cell007 "High voltage battery cell voltage for Cell 07";
CM_ SG_ 1835 HVBatCellVoltage_Cell006 "High voltage battery cell voltage for Cell 06";
CM_ SG_ 1835 HVBatCellVoltage_Cell005 "High voltage battery cell voltage for Cell 05";
CM_ SG_ 1835 HVBatCellVoltage_Cell004 "High voltage battery cell voltage for Cell 04";
CM_ SG_ 1835 HVBatCellVoltage_Cell003 "High voltage battery cell voltage for Cell 03";
CM_ SG_ 1835 HVBatCellVoltage_Cell002 "High voltage battery cell voltage for Cell 02";
CM_ SG_ 1835 HVBatCellVoltage_Cell001 "High voltage battery cell voltage for Cell 01";
CM_ SG_ 1035 RadFanReq "Radiator Fan request";
CM_ SG_ 1035 EngSpd "Engine speed";
CM_ SG_ 1035 EngCltTmpV "Engine Coolant Temperature Validity";
CM_ SG_ 1035 EngCltTmp "Engine Coolant Temp";
CM_ SG_ 750 Battery_Volt_1 "Battery Volt 1 signal";
CM_ SG_ 1436 Blower_Speed "Frequency Feedback received from the Blower";
CM_ SG_ 276 HEV_ESS_Mode "Engine start stop information:  engine start stop mode";
CM_ SG_ 262 PowertrainPrplsnActv "Powertrain Propulsion Status.";
CM_ SG_ 262 EngineSpeed_W "It gives information on C-CAN network about  engine speed";
CM_ SG_ 258 VehicleSpeedVSOSig "It is the average vehicle speed calculated.";
CM_ SG_ 1579 HVBatteryVoltage_MinCal "Minimum allowable HV battery voltage";
CM_ SG_ 1579 HVBatteryVoltage_MaxCal "Maximum allowable HV battery voltage";
CM_ SG_ 1579 HVBatteryCurrent_MaxCal "Maximum allowable HV battery current";
CM_ SG_ 1579 ChargeSystemFaultReason "Charge System Fault Reason";
CM_ SG_ 1579 ACCurrent_MaxCal "Maximum allowable AC current";
CM_ SG_ 478 LVDC_VoltageSetpoint "Low side voltage Setpoint";
CM_ SG_ 478 LVDC_SystemVoltageAct "System actual voltage";
CM_ SG_ 478 LVDC_CurrentSetpoint "Low side current Setpoint";
CM_ SG_ 478 HVInverterVoltage_Rational "??";
CM_ SG_ 478 HVDC_VoltageSetpoint "High side voltage set point";
CM_ SG_ 478 HVDC_CurrentSetpoint "High  side current Setpoint";
CM_ SG_ 478 EchargeSOCRange_ePT "Target SOC for ECharge";
CM_ SG_ 478 CRC_HYBRID_CHARGING_COMMAND "CRC according to SAE J1850 standard at each frame transmission.";
CM_ SG_ 1374 HVBatPackVoltage_MaxAllowedV "Maximum pack voltage allowed valid; Invalid = [1]";
CM_ SG_ 1374 HVBatCellVoltage_MinAllowedV "Minimum cell voltage allowed valid; Invalid = [1]";
CM_ SG_ 1374 HVBatCellVoltage_MinAllowed "Minimum cell voltage allowed";
CM_ SG_ 1374 HVBatCellVoltage_MaxAllowedV "Maximum cell voltage allowed valid; Invalid = [1]";
CM_ SG_ 1374 HVBatCellVoltage_MaxAllowed "Maximum cell voltage allowed";
CM_ SG_ 1374 HVBatCellVoltage_LowThreshold "Cell voltage low threshold";
CM_ SG_ 1374 HVBatCellVoltage_HighThreshold "Cell voltage high threshold";
CM_ SG_ 1374 HVBatCapacity_AmpHrV "Total HV battery amp hour capacity validity; Invalid = [1]";
CM_ SG_ 1374 HVBatCapacity_AmpHr "Total HV Battery Amp Hour Capacity";
CM_ SG_ 1578 OBC_IdleTimeSec "On board charger idle time";
CM_ SG_ 1578 OBC_IdleTimeMin "On board charger idle time - long";
CM_ SG_ 1578 OBC_ChargeTimeSec "On board charge time";
CM_ SG_ 1578 OBC_ChargeTimeMin "On board charge time - long";
CM_ SG_ 1578 Charging_WHr "Watt-hours of charge";
CM_ SG_ 1372 OBC_Temp4 "OBCM temperature sensor 3";
CM_ SG_ 1372 OBC_Temp3 "OBCM temperature sensor 4";
CM_ SG_ 1372 OBC_Temp2 "OBCM temperature sensor 2";
CM_ SG_ 1372 OBC_Temp1 "OBCM temperature sensor 1";
CM_ SG_ 1845 HVBatSerialLength "Length of the High Voltage Battery pack's serial number (number of ASCII characters)";
CM_ SG_ 1460 FOTA_Status "FOTA_Status";
CM_ SG_ 478 VoltageRequest "High Voltage Battery Voltage";
CM_ SG_ 1374 MessageCounter_HVBATTERY4 "This signal is a counter used for safety checks strategies. This counter is incremented of 1 (one) unit at each frame transmission.";
CM_ SG_ 1374 CRC_HVBATTERY4 "CRC according to SAE J1850 standard at each frame transmission.";
CM_ SG_ 276 PropulsionSystemActive_114 "Propulsion system active, [1] = active";
CM_ SG_ 2564682064 N_PDU_18DDF150 "This signal is used for diagnostic purposes";
CM_ SG_ 2564682059 N_PDU_18DDF14B "This signal is used for diagnostic purposes";
CM_ SG_ 2564682320 N_PDU_18DDF250 "This signal is used for diagnostic purposes";
CM_ SG_ 2564682315 N_PDU_18DDF24B "This signal is used for diagnostic purposes";
CM_ SG_ 2564682308 N_PDU_18DDF244 "This signal is used for diagnostic purposes";
CM_ SG_ 2564682052 N_PDU_18DDF144 "This signal is used for diagnostic purposes";
CM_ SG_ 2564485712 N_PDU_18DAF250 "This signal is used for diagnostic purposes";
CM_ SG_ 2564485707 N_PDU_18DAF24B "This signal is used for diagnostic purposes";
CM_ SG_ 2564485700 N_PDU_18DAF244 "This signal is used for diagnostic purposes";
CM_ SG_ 2564444402 N_PDU_18DA50F2 "This signal is used for diagnostic purposes";
CM_ SG_ 2564443122 N_PDU_18DA4BF2 "This signal is used for diagnostic purposes";
CM_ SG_ 2564441330 N_PDU_18DA44F2 "This signal is used for diagnostic purposes";
CM_ SG_ 2654339170 WakeupSource_FD03_HCP "Indicates the reason the ECU was most recently awakened";
CM_ SG_ 2654339170 PreviousCanNMState_FD03_HCP "Indicates the last CanNM state that the ECU existed in";
CM_ SG_ 2654339170 DES_FD03_HCP "Indicates whether the ECU?s CAN cell is in either ErrorActive, or ErrorPassive state OR has just now recovered from a BusOff condition";
CM_ SG_ 2654339170 CurrentCanNMState_FD03_HCP "Indicates that CanNM state the ECU is currently executing";
CM_ SG_ 1579 ChargingLevel "Charging level and type.";
CM_ SG_ 478 OBC_ModeRequest "Onboard charger mode request";
CM_ SG_ 478 OBC_ControlMethod "Onboard charger commanded control method";
CM_ SG_ 478 MainHV_ContactorCommand "High voltage battery contactor command";
CM_ SG_ 478 J1772_CloseS2 "J 1772 Close command";
CM_ SG_ 478 HVInverterVoltage_RationalV ".";
CM_ SG_ 478 HVBatCoolantLevelLow "Battery coolant level low";
CM_ SG_ 478 DCDC_OperationModeEnable "APM Operation Mode  Enable";
CM_ SG_ 478 ClearLegislatedDiagInfo "Clear Legislated Diagnostic Information";
CM_ SG_ 1374 HVBatRemainingAhCapacity "High voltage battery pack remaining amp hour capacity.";
CM_ SG_ 1374 HVBatDischargeAmpHrs "High voltage battery pack Amp Hours of discharge.";
CM_ SG_ 1374 HVBatChargeAmpHrs "High voltage battery pack Amp Hours of charge.";
CM_ SG_ 1374 BSGPackVoltage_MaxAllowed "Maximum pack voltage allowed";
CM_ SG_ 1038 Precharge_Closed "Precharge contactor is closed.";
CM_ SG_ 1038 Positive_Main_Closed "Positive main contactor is closed.";
CM_ SG_ 1038 Negative_Main_Closed "Negative main contactor is closed.";
CM_ SG_ 1038 HBCO_TempSensorRationality "Temperature sensor rationality.";
CM_ SG_ 1038 HBCO_Sensor_Fault "Sensor failure detected.";
CM_ SG_ 1038 HBCO_PackUndertemp "Battery undertemperature.";
CM_ SG_ 1038 HBCO_PackOvertemp "Battery overtemperature.";
CM_ SG_ 1038 HBCO_OverCurrent "Overcurrent condition detected.";
CM_ SG_ 1038 HBCO_Micro_Failure "Internal micro failures detected.";
CM_ SG_ 1038 HBCO_Main_Fuse_Failure "Main fuse (SD) is blown.";
CM_ SG_ 1038 HBCO_Isolation_Fault "Loss of isolation detected.";
CM_ SG_ 1038 HBCO_Internal_CommFault "Loss of Comm on the BPCM internal CAN bus.";
CM_ SG_ 1038 HBCO_Impact_Detected "Crash detection.";
CM_ SG_ 1038 HBCO_HVIL_Failure "HVIL Failure.";
CM_ SG_ 1038 HBCO_External_CommFault "Loss of Comm on the vehicle CAN bus.";
CM_ SG_ 1038 HBCO_CellUndervoltage "Cell voltage too low.";
CM_ SG_ 1038 HBCO_CellOvervoltage "Cell voltage too high.";
CM_ SG_ 1038 HBCO_12V_Low "12V too low.";
CM_ SG_ 1038 HBCO_12V_High "12V too high.";
CM_ SG_ 1038 HBCNC_TempSensorRationality "Temperature sensor rationality.";
CM_ SG_ 1038 HBCNC_SOH_Failure "State of Health failure.";
CM_ SG_ 1038 HBCNC_Sensor_Failure "Sensor failure detected.";
CM_ SG_ 1038 HBCNC_Precharge_Failure "Precharge failed.";
CM_ SG_ 1038 HBCNC_PackUndervoltage "Pack voltage too low.";
CM_ SG_ 1038 HBCNC_PackUndertemp "Battery undertemperature.";
CM_ SG_ 1038 HBCNC_PackOvervoltage "Pack voltage too high.";
CM_ SG_ 1038 HBCNC_PackOvertemp "Battery overtemperature.";
CM_ SG_ 1038 HBCNC_Micro_Failure "Internal micro failures detected.";
CM_ SG_ 1038 HBCNC_Main_Fuse_Failure "Main fuse (SD) is blown.";
CM_ SG_ 1038 HBCNC_Isolation_Fault "Loss of isolation detected.";
CM_ SG_ 1038 HBCNC_Internal_CommFault "Loss of Comm on the BPCM internal CAN bus.";
CM_ SG_ 1038 HBCNC_Impact_Detected "Crash detection.";
CM_ SG_ 1038 HBCNC_External_CommFault "Loss of Comm on the vehicle CAN bus.";
CM_ SG_ 1038 HBCNC_EEPROM_Fault "EEPROM fault or invalid signals detected.";
CM_ SG_ 1038 HBCNC_Contactors_Welded "Contactors welded.";
CM_ SG_ 1038 HBCNC_CellUndervoltage "Cell voltage too low.";
CM_ SG_ 1038 HBCNC_CellOvervoltage "Cell voltage too high.";
CM_ SG_ 1038 HBCNC_12V_Low "12V too low.";
CM_ SG_ 1038 HBCNC_12V_High "12V too high.";
CM_ SG_ 1038 BPCM_DTC_Status6 "Diagnostic Trouble Code status 6";
CM_ SG_ 1038 BPCM_DTC_Status5 "Diagnostic Trouble Code status 5";
CM_ SG_ 1038 BPCM_DTC_Status4 "Diagnostic Trouble Code status 4";
CM_ SG_ 1038 BPCM_DTC_Status3 "Diagnostic Trouble Code status 3";
CM_ SG_ 1038 BPCM_DTC_Status2 "Diagnostic Trouble Code status 2";
CM_ SG_ 1038 BPCM_DTC_Status1 "Diagnostic Trouble Code status 1";
CM_ SG_ 1038 BPCM_DTC_Index6 "Battery Pack DTC Index 6";
CM_ SG_ 1038 BPCM_DTC_Index5 "Battery Pack DTC Index 5";
CM_ SG_ 1038 BPCM_DTC_Index4 "Battery Pack DTC Index 4";
CM_ SG_ 1038 BPCM_DTC_Index3 "Battery Pack DTC Index 3";
CM_ SG_ 1038 BPCM_DTC_Index2 "Battery Pack DTC Index 2";
CM_ SG_ 1038 BPCM_DTC_Index1 "Battery Pack DTC Index 1";
CM_ SG_ 1038 BPCM_CalibrationVN "Battery Pack calibration verification number.";
CM_ SG_ 1038 BPCM_CalibrationID "Battery Pack calibration ID index.";
CM_ SG_ 2654339223 WakeupSource_FD11_APM2 "Indicates the reason the ECU was most recently awakened";
CM_ SG_ 2654339223 PreviousCanNMState_FD11_APM2 "Indicates the last CanNM state that the ECU existed in";
CM_ SG_ 2654339223 GenericFailSts_FD11_APM2 "Indicates the presence/absent of at least one DTC in the System Memory";
CM_ SG_ 2654339223 EOL_FD11_APM2 "Indicates if the ECU requires configuration data at the assembly plant End Of Line";
CM_ SG_ 2654339223 DES_FD11_APM2 "Indicates whether the ECU?s CAN cell is in either ErrorActive, or ErrorPassive state OR has just now recovered from a BusOff condition";
CM_ SG_ 2654339223 CurrentFailSts_FD11_APM2 "Indicates the presence/absence of at least one DTC with DTCStatus = present in the System Memory";
CM_ SG_ 2654339223 CurrentCanNMState_FD11_APM2 "Indicates that CanNM state the ECU is currently executing";
CM_ SG_ 1579 OBCM_PLUG_STS "Plug Status retrieved by the VDCM according to the proximity Sts and pilot Sts and current input available sent by the OBCM";
CM_ SG_ 478 OBC_OperativeModeReq "This signal indicates the Onboard charger mode request";
CM_ SG_ 478 HV_Volt_Min_Thrsh "This signal indicates the Commanded minimum Traction Battery Voltage to On Board Charger.";
CM_ SG_ 478 HV_Volt_Max_Thrsh "This signal indicates the Commanded maximum Traction Battery Voltage to On Board Charger.";
CM_ SG_ 478 DC_Curr_Max_Thrsh "Maximum Threshold for charging DC current.";
CM_ SG_ 478 ChargeEnable "Charge Enable";
CM_ SG_ 478 AC_Curr_Min_Thrsh "Commanded AC current min threshold to On Board Charge";
CM_ SG_ 478 AC_Curr_Max_Thrsh "Commanded AC current max threshold to On Board Charge";
CM_ SG_ 1578 OnboardChargerReady "OBCM Ready status";
CM_ SG_ 1578 OnboardChargerMode "OBCM operative mode";
CM_ SG_ 1578 OBC_WakeReason "OBCM wakeup status";
CM_ SG_ 1578 OBC_GenericFailSts ".";
CM_ SG_ 1578 OBC_FaultReason "OBCM Fault Reason";
CM_ SG_ 1578 OBC_EVServiceLampOn "Ev service On request from OBCM";
CM_ SG_ 1578 OBC_EVServiceLampFlash "Ev service LIGHT flash from OBCM";
CM_ SG_ 1578 OBC_CurrentFailureSts ".";
CM_ SG_ 1578 OBC_ChargingFaultSts "OBCM charging fault status";
CM_ SG_ 1578 OBC_ChargeFailure "0 = Open, 1 = Off/SNA";
CM_ SG_ 1578 OBC_CaptureEnvironmentData "Capture Environmental Data";
CM_ SG_ 1578 ACplug_PwrMax "Maximum  AC power limit";
CM_ SG_ 2654486640 SourceNodeIdentifier_1E384070 "Source Node Identifier";
CM_ SG_ 2654486653 SourceNodeIdentifier_1E38407D "Source Node Identifier";
CM_ SG_ 2654486626 SourceNodeIdentifier_1E384062 "Source Node Identifier";
CM_ SG_ 2654486598 SourceNodeIdentifier_1E384046 "Source Node Identifier";
CM_ SG_ 478 CurrentRequest "HCP current request to the on board charger";
CM_ SG_ 1038 BPCM_Odometer "Battery Pack odometer (kilometers driven).";
CM_ SG_ 1579 VDCM_UDCChrgr "For comm with charging station type B";
CM_ SG_ 1579 VDCM_IDCChrgr "For comm with charging station type B";
CM_ SG_ 1579 ChargeSystemSts "Charging System status";
CM_ SG_ 1579 ChargeSystemFault "Charging System Fault status";
CM_ SG_ 478 VDCM_StsWldgReq "This signal indicates the welding check request from VDCM";
CM_ SG_ 478 VDCM_SessnStopReq "This signal indicates the session stop request from VDCM";
CM_ SG_ 2654486640 CBV_bit0_RepeatMessageRequestBit_1E384070 "Repeat Message Request Bit";
CM_ SG_ 2654486640 CBV_bit3_NMCoordinatorBit_1E384070 "NM Coordinator Sleep Bit";
CM_ SG_ 2654486640 CBV_bit4_ActiveWakeupBit_1E384070 "Active Wakeup Bit";
CM_ SG_ 2654486640 CBV_bit6_PartialNtwInfBit_1E384070 "Partial Network Information Bit (PNI)";
CM_ SG_ 2654486653 CBV_bit0_RepeatMessageRequestBit_1E38407D "Repeat Message Request Bit";
CM_ SG_ 2654486653 CBV_bit3_NMCoordinatorBit_1E38407D "NM Coordinator Sleep Bit";
CM_ SG_ 2654486653 CBV_bit4_ActiveWakeupBit_1E38407D "Active Wakeup Bit";
CM_ SG_ 2654486653 CBV_bit6_PartialNtwInfBit_1E38407D "Partial Network Information Bit (PNI)";
CM_ SG_ 2654486626 CBV_bit0_RepeatMessageRequestBit_1E384062 "Repeat Message Request Bit";
CM_ SG_ 2654486626 CBV_bit3_NMCoordinatorBit_1E384062 "NM Coordinator Sleep Bit";
CM_ SG_ 2654486626 CBV_bit4_ActiveWakeupBit_1E384062 "Active Wakeup Bit";
CM_ SG_ 2654486626 CBV_bit6_PartialNtwInfBit_1E384062 "Partial Network Information Bit (PNI)";
CM_ SG_ 2654486598 CBV_bit0_RepeatMessageRequestBit_1E384046 "Repeat Message Request Bit";
CM_ SG_ 2654486598 CBV_bit3_NMCoordinatorBit_1E384046 "NM Coordinator Sleep Bit";
CM_ SG_ 2654486598 CBV_bit4_ActiveWakeupBit_1E384046 "Active Wakeup Bit";
CM_ SG_ 2654486598 CBV_bit6_PartialNtwInfBit_1E384046 "Partial Network Information Bit (PNI)";
CM_ SG_ 1579 CRC_HYBRID_CHARGING_STATUS "CRC according to SAE J1850 standard at each frame transmission.";
CM_ SG_ 478 VDCM_StsSWWldgReq "Software welding check request from VDCM";
CM_ SG_ 1578 OBCM_PrechargeSts "OBCM precharge status feedback";
CM_ SG_ 1578 ChrgFailSts "TxMessageResponse from EVSE.";
CM_ SG_ 1845 HVBatSerialNumber "High Voltage Battery pack serial number, ASCII 8-bit encoded.";
CM_ SG_ 2654339170 StayActiveSource_FD03_HCP "Indicates the source that requests the ECU to stay active";
CM_ SG_ 1579 MessageCounter_HYBRID_CHARGING__62B "This signal is a counter used for safety checks strategies. This counter is incremented of 1 (one) unit at each frame transmission.";
CM_ SG_ 478 MessageCounter_HYBRID_CHARGING__1DE "This signal is a counter used for safety checks strategies. This counter is incremented of 1 (one) unit at each frame transmission.";
CM_ SG_ 478 MaxCurrentAllwd "Charge Enable";
CM_ SG_ 1460 MessageCounter_FOTA_MASTER "This signal is a counter used for safety checks strategies. This counter is incremented of 1 (one) unit at each frame transmission.";
CM_ SG_ 1460 CRC_FOTA_MASTER "CRC according to SAE J1850 standard at each frame transmission.";
CM_ SG_ 1578 CRC_HV_CHARGER2 "CRC according to SAE J1850 standard at each frame transmission.";
CM_ SG_ 1578 MessageCounter_HV_CHARGER2 "This signal is a counter used for safety checks strategies. This counter is incremented of 1 (one) unit at each frame transmission.";
CM_ SG_ 2654339223 StayActiveSource_FD11_APM2 "Indicates the source that requests the ECU to stay active";
BA_DEF_ SG_ "GenSigTimeoutTime_HCP" INT 0 65535;
BA_DEF_ SG_ "GenSigTimeoutTime_PPIM" INT 0 65535;
BA_DEF_ SG_ "GenSigTimeoutTime_APM2" INT 0 65535;
BA_DEF_ SG_ "GenSigTimeoutTime_VDCM" INT 0 65535;
BA_DEF_ SG_ "GenSigStartValue" INT 0 2147483647;
BA_DEF_ SG_ "GenSigInactiveValue" INT 0 2147483647;
BA_DEF_ SG_ "GenSigSendType" ENUM "NotUsed","OnWrite","OnWriteWithRepetition","OnChange","OnChangeWithRepetition","IfActive","IfActiveWithRepetition","NoSigSendType";
BA_DEF_ SG_ "SystemSignalLongSymbol" STRING ;
BA_DEF_ SG_ "GenSigTimeoutTime_BPCM" INT 0 65535;
BA_DEF_ SG_ "GenSigTimeoutTime_EVCU2" INT 0 65535;
BA_DEF_ SG_ "GenSigTimeoutTime_IDCM" INT 0 65535;
BA_DEF_ SG_ "GenSigTimeoutTime_SGW" INT 0 65535;
BA_DEF_ BO_ "DiagRequest" ENUM "No","Yes";
BA_DEF_ BO_ "Type" ENUM "P","C","PE","COC","PE_Cntrl","E","E_Cntrl","OC","S","BAF","DC","EM","MM","ISO-TP","-";
BA_DEF_ BO_ "DiagResponse" ENUM "No","Yes";
BA_DEF_ BO_ "NmMessage" ENUM "No","Yes";
BA_DEF_ BO_ "GenMsgSendType" ENUM "Cyclic","NotUsed","NotUsed","NotUsed","NotUsed","NotUsed","NotUsed","NotUsed","NoMsgSendType";
BA_DEF_ BO_ "GenMsgNrOfRepetition" INT 0 255;
BA_DEF_ BO_ "GenMsgILSupport" ENUM "No","Yes";
BA_DEF_ BO_ "GenMsgStartDelayTime" INT 0 65535;
BA_DEF_ BO_ "GenMsgCycleTimeFast" INT 0 65535;
BA_DEF_ BO_ "GenMsgCycleTime" INT 0 65535;
BA_DEF_ BO_ "GenMsgDelayTime" INT 0 65535;
BA_DEF_ BO_ "NmAsrMessage" ENUM "No","Yes";
BA_DEF_ BO_ "DiagState" ENUM "No","Yes";
BA_DEF_ BO_ "DiagConnection" HEX 0 65535;
BA_DEF_ BO_ "CanTpFcFrameId" HEX 0 2147483647;
BA_DEF_ BO_ "VFrameFormat" ENUM "StandardCAN","ExtendedCAN","reserved","reserved","reserved","reserved","reserved","reserved","reserved","reserved","reserved","reserved","reserved","reserved","StandardCAN_FD","ExtendedCAN_FD";
BA_DEF_ BO_ "CANFD_BRS" ENUM "0","1";
BA_DEF_DEF_ "GenSigTimeoutTime_HCP" 2500;
BA_DEF_DEF_ "GenSigTimeoutTime_PPIM" 2500;
BA_DEF_DEF_ "GenSigTimeoutTime_APM2" 2500;
BA_DEF_DEF_ "GenSigTimeoutTime_VDCM" 2500;
BA_DEF_DEF_ "GenSigStartValue" 0;
BA_DEF_DEF_ "GenSigInactiveValue" 0;
BA_DEF_DEF_ "GenSigSendType" "NoSigSendType";
BA_DEF_DEF_ "SystemSignalLongSymbol" "";
BA_DEF_DEF_ "GenSigTimeoutTime_BPCM" 2500;
BA_DEF_DEF_ "GenSigTimeoutTime_EVCU2" 2500;
BA_DEF_DEF_ "GenSigTimeoutTime_IDCM" 2500;
BA_DEF_DEF_ "GenSigTimeoutTime_SGW" 2500;
BA_DEF_DEF_ "DiagRequest" "No";
BA_DEF_DEF_ "Type" "-";
BA_DEF_DEF_ "DiagResponse" "No";
BA_DEF_DEF_ "NmMessage" "No";
BA_DEF_DEF_ "GenMsgSendType" "NoMsgSendType";
BA_DEF_DEF_ "GenMsgNrOfRepetition" 0;
BA_DEF_DEF_ "GenMsgILSupport" "No";
BA_DEF_DEF_ "GenMsgStartDelayTime" 0;
BA_DEF_DEF_ "GenMsgCycleTimeFast" 0;
BA_DEF_DEF_ "GenMsgCycleTime" 0;
BA_DEF_DEF_ "GenMsgDelayTime" 0;
BA_DEF_DEF_ "NmAsrMessage" "No";
BA_DEF_DEF_ "DiagState" "No";
BA_DEF_DEF_ "DiagConnection" 0;
BA_DEF_DEF_ "CanTpFcFrameId" 2147483647;
BA_DEF_DEF_ "VFrameFormat" "StandardCAN_FD";
BA_DEF_DEF_ "CANFD_BRS" "0";
BA_ "Type" BO_ 1835 1;
BA_ "GenMsgSendType" BO_ 1835 0;
BA_ "GenMsgILSupport" BO_ 1835 1;
BA_ "GenMsgCycleTime" BO_ 1835 1000;
BA_ "CANFD_BRS" BO_ 1835 1;
BA_ "Type" BO_ 1035 1;
BA_ "GenMsgSendType" BO_ 1035 0;
BA_ "GenMsgILSupport" BO_ 1035 1;
BA_ "GenMsgCycleTime" BO_ 1035 100;
BA_ "CANFD_BRS" BO_ 1035 1;
BA_ "Type" BO_ 750 1;
BA_ "GenMsgSendType" BO_ 750 0;
BA_ "GenMsgILSupport" BO_ 750 1;
BA_ "GenMsgCycleTime" BO_ 750 50;
BA_ "CANFD_BRS" BO_ 750 1;
BA_ "Type" BO_ 1436 3;
BA_ "GenMsgSendType" BO_ 1436 0;
BA_ "GenMsgNrOfRepetition" BO_ 1436 2;
BA_ "GenMsgILSupport" BO_ 1436 1;
BA_ "GenMsgCycleTimeFast" BO_ 1436 20;
BA_ "GenMsgCycleTime" BO_ 1436 1000;
BA_ "GenMsgDelayTime" BO_ 1436 20;
BA_ "CANFD_BRS" BO_ 1436 1;
BA_ "Type" BO_ 2654486640 8;
BA_ "NmMessage" BO_ 2654486640 1;
BA_ "NmAsrMessage" BO_ 2654486640 1;
BA_ "VFrameFormat" BO_ 2654486640 15;
BA_ "CANFD_BRS" BO_ 2654486640 1;
BA_ "Type" BO_ 2654486626 8;
BA_ "NmMessage" BO_ 2654486626 1;
BA_ "NmAsrMessage" BO_ 2654486626 1;
BA_ "VFrameFormat" BO_ 2654486626 15;
BA_ "CANFD_BRS" BO_ 2654486626 1;
BA_ "Type" BO_ 276 1;
BA_ "GenMsgSendType" BO_ 276 0;
BA_ "GenMsgILSupport" BO_ 276 1;
BA_ "GenMsgCycleTime" BO_ 276 10;
BA_ "CANFD_BRS" BO_ 276 1;
BA_ "Type" BO_ 262 1;
BA_ "GenMsgSendType" BO_ 262 0;
BA_ "GenMsgILSupport" BO_ 262 1;
BA_ "GenMsgCycleTime" BO_ 262 10;
BA_ "CANFD_BRS" BO_ 262 1;
BA_ "Type" BO_ 258 1;
BA_ "GenMsgSendType" BO_ 258 0;
BA_ "GenMsgILSupport" BO_ 258 1;
BA_ "GenMsgCycleTime" BO_ 258 10;
BA_ "CANFD_BRS" BO_ 258 1;
BA_ "Type" BO_ 2654486653 8;
BA_ "NmMessage" BO_ 2654486653 1;
BA_ "NmAsrMessage" BO_ 2654486653 1;
BA_ "VFrameFormat" BO_ 2654486653 15;
BA_ "CANFD_BRS" BO_ 2654486653 1;
BA_ "Type" BO_ 2654486598 8;
BA_ "NmMessage" BO_ 2654486598 1;
BA_ "NmAsrMessage" BO_ 2654486598 1;
BA_ "VFrameFormat" BO_ 2654486598 15;
BA_ "CANFD_BRS" BO_ 2654486598 1;
BA_ "Type" BO_ 1579 1;
BA_ "GenMsgSendType" BO_ 1579 0;
BA_ "GenMsgILSupport" BO_ 1579 1;
BA_ "GenMsgCycleTime" BO_ 1579 500;
BA_ "CANFD_BRS" BO_ 1579 1;
BA_ "Type" BO_ 478 1;
BA_ "GenMsgSendType" BO_ 478 0;
BA_ "GenMsgILSupport" BO_ 478 1;
BA_ "GenMsgCycleTime" BO_ 478 20;
BA_ "CANFD_BRS" BO_ 478 1;
BA_ "Type" BO_ 1578 3;
BA_ "GenMsgSendType" BO_ 1578 0;
BA_ "GenMsgNrOfRepetition" BO_ 1578 3;
BA_ "GenMsgILSupport" BO_ 1578 1;
BA_ "GenMsgCycleTimeFast" BO_ 1578 10;
BA_ "GenMsgCycleTime" BO_ 1578 500;
BA_ "CANFD_BRS" BO_ 1578 1;
BA_ "Type" BO_ 1372 1;
BA_ "GenMsgSendType" BO_ 1372 0;
BA_ "GenMsgILSupport" BO_ 1372 1;
BA_ "GenMsgCycleTime" BO_ 1372 250;
BA_ "CANFD_BRS" BO_ 1372 1;
BA_ "Type" BO_ 2564682064 8;
BA_ "DiagResponse" BO_ 2564682064 1;
BA_ "DiagConnection" BO_ 2564682064 61776;
BA_ "VFrameFormat" BO_ 2564682064 1;
BA_ "Type" BO_ 2564682059 8;
BA_ "DiagResponse" BO_ 2564682059 1;
BA_ "DiagConnection" BO_ 2564682059 61771;
BA_ "VFrameFormat" BO_ 2564682059 1;
BA_ "Type" BO_ 2564682320 8;
BA_ "DiagResponse" BO_ 2564682320 1;
BA_ "DiagConnection" BO_ 2564682320 62032;
BA_ "VFrameFormat" BO_ 2564682320 15;
BA_ "CANFD_BRS" BO_ 2564682320 1;
BA_ "Type" BO_ 2564682315 8;
BA_ "DiagResponse" BO_ 2564682315 1;
BA_ "DiagConnection" BO_ 2564682315 62027;
BA_ "VFrameFormat" BO_ 2564682315 15;
BA_ "CANFD_BRS" BO_ 2564682315 1;
BA_ "Type" BO_ 2564682308 8;
BA_ "DiagResponse" BO_ 2564682308 1;
BA_ "DiagConnection" BO_ 2564682308 62020;
BA_ "VFrameFormat" BO_ 2564682308 15;
BA_ "CANFD_BRS" BO_ 2564682308 1;
BA_ "Type" BO_ 2564682052 8;
BA_ "DiagResponse" BO_ 2564682052 1;
BA_ "DiagConnection" BO_ 2564682052 61764;
BA_ "VFrameFormat" BO_ 2564682052 1;
BA_ "Type" BO_ 2564485712 8;
BA_ "DiagResponse" BO_ 2564485712 1;
BA_ "DiagConnection" BO_ 2564485712 62032;
BA_ "VFrameFormat" BO_ 2564485712 15;
BA_ "CANFD_BRS" BO_ 2564485712 1;
BA_ "Type" BO_ 2564485707 8;
BA_ "DiagResponse" BO_ 2564485707 1;
BA_ "DiagConnection" BO_ 2564485707 62027;
BA_ "VFrameFormat" BO_ 2564485707 15;
BA_ "CANFD_BRS" BO_ 2564485707 1;
BA_ "Type" BO_ 2564485700 8;
BA_ "DiagResponse" BO_ 2564485700 1;
BA_ "DiagConnection" BO_ 2564485700 62020;
BA_ "VFrameFormat" BO_ 2564485700 15;
BA_ "CANFD_BRS" BO_ 2564485700 1;
BA_ "DiagRequest" BO_ 2564444402 1;
BA_ "Type" BO_ 2564444402 8;
BA_ "DiagConnection" BO_ 2564444402 62032;
BA_ "VFrameFormat" BO_ 2564444402 15;
BA_ "CANFD_BRS" BO_ 2564444402 1;
BA_ "DiagRequest" BO_ 2564443122 1;
BA_ "Type" BO_ 2564443122 8;
BA_ "DiagConnection" BO_ 2564443122 62027;
BA_ "VFrameFormat" BO_ 2564443122 15;
BA_ "CANFD_BRS" BO_ 2564443122 1;
BA_ "DiagRequest" BO_ 2564441330 1;
BA_ "Type" BO_ 2564441330 8;
BA_ "DiagConnection" BO_ 2564441330 62020;
BA_ "VFrameFormat" BO_ 2564441330 15;
BA_ "CANFD_BRS" BO_ 2564441330 1;
BA_ "Type" BO_ 2651930749 11;
BA_ "GenMsgILSupport" BO_ 2651930749 1;
BA_ "VFrameFormat" BO_ 2651930749 15;
BA_ "CANFD_BRS" BO_ 2651930749 1;
BA_ "GenMsgILSupport" BO_ 2651930694 1;
BA_ "VFrameFormat" BO_ 2651930694 15;
BA_ "CANFD_BRS" BO_ 2651930694 1;
BA_ "Type" BO_ 2651930694 11;
BA_ "Type" BO_ 2654339170 1;
BA_ "GenMsgSendType" BO_ 2654339170 0;
BA_ "GenMsgILSupport" BO_ 2654339170 1;
BA_ "GenMsgCycleTime" BO_ 2654339170 1000;
BA_ "VFrameFormat" BO_ 2654339170 15;
BA_ "CANFD_BRS" BO_ 2654339170 1;
BA_ "Type" BO_ 1845 1;
BA_ "GenMsgSendType" BO_ 1845 0;
BA_ "GenMsgILSupport" BO_ 1845 1;
BA_ "GenMsgCycleTime" BO_ 1845 1000;
BA_ "CANFD_BRS" BO_ 1845 1;
BA_ "Type" BO_ 1460 3;
BA_ "GenMsgSendType" BO_ 1460 0;
BA_ "GenMsgILSupport" BO_ 1460 1;
BA_ "GenMsgCycleTime" BO_ 1460 1000;
BA_ "GenMsgDelayTime" BO_ 1460 20;
BA_ "CANFD_BRS" BO_ 1460 1;
BA_ "Type" BO_ 1374 1;
BA_ "GenMsgSendType" BO_ 1374 0;
BA_ "GenMsgILSupport" BO_ 1374 1;
BA_ "GenMsgCycleTime" BO_ 1374 250;
BA_ "CANFD_BRS" BO_ 1374 1;
BA_ "Type" BO_ 1038 1;
BA_ "GenMsgSendType" BO_ 1038 0;
BA_ "GenMsgILSupport" BO_ 1038 1;
BA_ "GenMsgCycleTime" BO_ 1038 100;
BA_ "CANFD_BRS" BO_ 1038 1;
BA_ "Type" BO_ 2654339223 1;
BA_ "GenMsgSendType" BO_ 2654339223 0;
BA_ "GenMsgILSupport" BO_ 2654339223 1;
BA_ "GenMsgCycleTime" BO_ 2654339223 1000;
BA_ "VFrameFormat" BO_ 2654339223 15;
BA_ "CANFD_BRS" BO_ 2654339223 1;
BA_ "GenSigTimeoutTime_PPIM" SG_ 1038 HBCNC_Main_Fuse_Failure 0;
BA_ "GenSigTimeoutTime_BPCM" SG_ 1038 HBCNC_Main_Fuse_Failure 0;
BA_ "GenSigTimeoutTime_EVCU2" SG_ 1038 HBCNC_Main_Fuse_Failure 0;
BA_ "GenSigTimeoutTime_IDCM" SG_ 1038 HBCNC_Main_Fuse_Failure 0;
BA_ "GenSigTimeoutTime_SGW" SG_ 1038 HBCNC_Main_Fuse_Failure 0;
BA_ "GenSigTimeoutTime_PPIM" SG_ 1038 HBCO_Internal_CommFault 0;
BA_ "GenSigTimeoutTime_BPCM" SG_ 1038 HBCO_Internal_CommFault 0;
BA_ "GenSigTimeoutTime_EVCU2" SG_ 1038 HBCO_Internal_CommFault 0;
BA_ "GenSigTimeoutTime_IDCM" SG_ 1038 HBCO_Internal_CommFault 0;
BA_ "GenSigTimeoutTime_SGW" SG_ 1038 HBCO_Internal_CommFault 0;
BA_ "GenSigTimeoutTime_PPIM" SG_ 1038 HBCO_Isolation_Fault 0;
BA_ "GenSigTimeoutTime_BPCM" SG_ 1038 HBCO_Isolation_Fault 0;
BA_ "GenSigTimeoutTime_EVCU2" SG_ 1038 HBCO_Isolation_Fault 0;
BA_ "GenSigTimeoutTime_IDCM" SG_ 1038 HBCO_Isolation_Fault 0;
BA_ "GenSigTimeoutTime_SGW" SG_ 1038 HBCO_Isolation_Fault 0;
BA_ "GenSigTimeoutTime_PPIM" SG_ 1038 HBCO_Main_Fuse_Failure 0;
BA_ "GenSigTimeoutTime_BPCM" SG_ 1038 HBCO_Main_Fuse_Failure 0;
BA_ "GenSigTimeoutTime_EVCU2" SG_ 1038 HBCO_Main_Fuse_Failure 0;
BA_ "GenSigTimeoutTime_IDCM" SG_ 1038 HBCO_Main_Fuse_Failure 0;
BA_ "GenSigTimeoutTime_SGW" SG_ 1038 HBCO_Main_Fuse_Failure 0;
BA_ "GenSigTimeoutTime_PPIM" SG_ 1038 HBCO_Micro_Failure 0;
BA_ "GenSigTimeoutTime_BPCM" SG_ 1038 HBCO_Micro_Failure 0;
BA_ "GenSigTimeoutTime_EVCU2" SG_ 1038 HBCO_Micro_Failure 0;
BA_ "GenSigTimeoutTime_IDCM" SG_ 1038 HBCO_Micro_Failure 0;
BA_ "GenSigTimeoutTime_SGW" SG_ 1038 HBCO_Micro_Failure 0;
BA_ "GenSigTimeoutTime_PPIM" SG_ 1038 HBCO_OverCurrent 0;
BA_ "GenSigTimeoutTime_BPCM" SG_ 1038 HBCO_OverCurrent 0;
BA_ "GenSigTimeoutTime_EVCU2" SG_ 1038 HBCO_OverCurrent 0;
BA_ "GenSigTimeoutTime_IDCM" SG_ 1038 HBCO_OverCurrent 0;
BA_ "GenSigTimeoutTime_SGW" SG_ 1038 HBCO_OverCurrent 0;
BA_ "GenSigTimeoutTime_PPIM" SG_ 1038 HBCO_PackOvertemp 0;
BA_ "GenSigTimeoutTime_BPCM" SG_ 1038 HBCO_PackOvertemp 0;
BA_ "GenSigTimeoutTime_EVCU2" SG_ 1038 HBCO_PackOvertemp 0;
BA_ "GenSigTimeoutTime_IDCM" SG_ 1038 HBCO_PackOvertemp 0;
BA_ "GenSigTimeoutTime_SGW" SG_ 1038 HBCO_PackOvertemp 0;
BA_ "GenSigTimeoutTime_PPIM" SG_ 1038 HBCO_PackUndertemp 0;
BA_ "GenSigTimeoutTime_BPCM" SG_ 1038 HBCO_PackUndertemp 0;
BA_ "GenSigTimeoutTime_EVCU2" SG_ 1038 HBCO_PackUndertemp 0;
BA_ "GenSigTimeoutTime_IDCM" SG_ 1038 HBCO_PackUndertemp 0;
BA_ "GenSigTimeoutTime_SGW" SG_ 1038 HBCO_PackUndertemp 0;
BA_ "GenSigTimeoutTime_PPIM" SG_ 1038 HBCNC_Micro_Failure 0;
BA_ "GenSigTimeoutTime_BPCM" SG_ 1038 HBCNC_Micro_Failure 0;
BA_ "GenSigTimeoutTime_EVCU2" SG_ 1038 HBCNC_Micro_Failure 0;
BA_ "GenSigTimeoutTime_IDCM" SG_ 1038 HBCNC_Micro_Failure 0;
BA_ "GenSigTimeoutTime_PPIM" SG_ 1038 HBCNC_Precharge_Failure 0;
BA_ "GenSigTimeoutTime_BPCM" SG_ 1038 HBCNC_Precharge_Failure 0;
BA_ "GenSigTimeoutTime_EVCU2" SG_ 1038 HBCNC_Precharge_Failure 0;
BA_ "GenSigTimeoutTime_IDCM" SG_ 1038 HBCNC_Precharge_Failure 0;
BA_ "GenSigTimeoutTime_SGW" SG_ 1038 HBCNC_Precharge_Failure 0;
BA_ "GenSigTimeoutTime_PPIM" SG_ 1038 HBCNC_Sensor_Failure 0;
BA_ "GenSigTimeoutTime_BPCM" SG_ 1038 HBCNC_Sensor_Failure 0;
BA_ "GenSigTimeoutTime_EVCU2" SG_ 1038 HBCNC_Sensor_Failure 0;
BA_ "GenSigTimeoutTime_IDCM" SG_ 1038 HBCNC_Sensor_Failure 0;
BA_ "GenSigTimeoutTime_SGW" SG_ 1038 HBCNC_Sensor_Failure 0;
BA_ "GenSigTimeoutTime_SGW" SG_ 1038 HBCNC_SOH_Failure 0;
BA_ "GenSigTimeoutTime_PPIM" SG_ 1038 HBCNC_SOH_Failure 0;
BA_ "GenSigTimeoutTime_BPCM" SG_ 1038 HBCNC_SOH_Failure 0;
BA_ "GenSigTimeoutTime_EVCU2" SG_ 1038 HBCNC_SOH_Failure 0;
BA_ "GenSigTimeoutTime_IDCM" SG_ 1038 HBCNC_SOH_Failure 0;
BA_ "GenSigTimeoutTime_PPIM" SG_ 1038 HBCNC_TempSensorRationality 0;
BA_ "GenSigTimeoutTime_BPCM" SG_ 1038 HBCNC_TempSensorRationality 0;
BA_ "GenSigTimeoutTime_EVCU2" SG_ 1038 HBCNC_TempSensorRationality 0;
BA_ "GenSigTimeoutTime_IDCM" SG_ 1038 HBCNC_TempSensorRationality 0;
BA_ "GenSigTimeoutTime_SGW" SG_ 1038 HBCNC_TempSensorRationality 0;
BA_ "GenSigTimeoutTime_PPIM" SG_ 1038 HBCO_12V_High 0;
BA_ "GenSigTimeoutTime_BPCM" SG_ 1038 HBCO_12V_High 0;
BA_ "GenSigTimeoutTime_EVCU2" SG_ 1038 HBCO_12V_High 0;
BA_ "GenSigTimeoutTime_IDCM" SG_ 1038 HBCO_12V_High 0;
BA_ "GenSigTimeoutTime_SGW" SG_ 1038 HBCO_12V_High 0;
BA_ "GenSigTimeoutTime_PPIM" SG_ 1038 HBCO_12V_Low 0;
BA_ "GenSigTimeoutTime_BPCM" SG_ 1038 HBCO_12V_Low 0;
BA_ "GenSigTimeoutTime_EVCU2" SG_ 1038 HBCO_12V_Low 0;
BA_ "GenSigTimeoutTime_IDCM" SG_ 1038 HBCO_12V_Low 0;
BA_ "GenSigTimeoutTime_SGW" SG_ 1038 HBCO_12V_Low 0;
BA_ "GenSigTimeoutTime_PPIM" SG_ 1038 HBCO_CellOvervoltage 0;
BA_ "GenSigTimeoutTime_BPCM" SG_ 1038 HBCO_CellOvervoltage 0;
BA_ "GenSigTimeoutTime_EVCU2" SG_ 1038 HBCO_CellOvervoltage 0;
BA_ "GenSigTimeoutTime_IDCM" SG_ 1038 HBCO_CellOvervoltage 0;
BA_ "GenSigTimeoutTime_SGW" SG_ 1038 HBCO_CellOvervoltage 0;
BA_ "GenSigTimeoutTime_PPIM" SG_ 1038 HBCO_CellUndervoltage 0;
BA_ "GenSigTimeoutTime_BPCM" SG_ 1038 HBCO_CellUndervoltage 0;
BA_ "GenSigTimeoutTime_EVCU2" SG_ 1038 HBCO_CellUndervoltage 0;
BA_ "GenSigTimeoutTime_IDCM" SG_ 1038 HBCO_CellUndervoltage 0;
BA_ "GenSigTimeoutTime_SGW" SG_ 1038 HBCO_CellUndervoltage 0;
BA_ "GenSigTimeoutTime_PPIM" SG_ 1038 HBCO_External_CommFault 0;
BA_ "GenSigTimeoutTime_BPCM" SG_ 1038 HBCO_External_CommFault 0;
BA_ "GenSigTimeoutTime_EVCU2" SG_ 1038 HBCO_External_CommFault 0;
BA_ "GenSigTimeoutTime_IDCM" SG_ 1038 HBCO_External_CommFault 0;
BA_ "GenSigTimeoutTime_SGW" SG_ 1038 HBCO_External_CommFault 0;
BA_ "GenSigTimeoutTime_PPIM" SG_ 1038 HBCO_HVIL_Failure 0;
BA_ "GenSigTimeoutTime_BPCM" SG_ 1038 HBCO_HVIL_Failure 0;
BA_ "GenSigTimeoutTime_EVCU2" SG_ 1038 HBCO_HVIL_Failure 0;
BA_ "GenSigTimeoutTime_IDCM" SG_ 1038 HBCO_HVIL_Failure 0;
BA_ "GenSigTimeoutTime_SGW" SG_ 1038 HBCO_HVIL_Failure 0;
BA_ "GenSigTimeoutTime_PPIM" SG_ 1038 HBCO_Impact_Detected 0;
BA_ "GenSigTimeoutTime_BPCM" SG_ 1038 HBCO_Impact_Detected 0;
BA_ "GenSigTimeoutTime_EVCU2" SG_ 1038 HBCO_Impact_Detected 0;
BA_ "GenSigTimeoutTime_IDCM" SG_ 1038 HBCO_Impact_Detected 0;
BA_ "GenSigTimeoutTime_SGW" SG_ 1038 HBCO_Impact_Detected 0;
BA_ "GenSigTimeoutTime_PPIM" SG_ 1038 HBCNC_PackUndervoltage 0;
BA_ "GenSigTimeoutTime_BPCM" SG_ 1038 HBCNC_PackUndervoltage 0;
BA_ "GenSigTimeoutTime_EVCU2" SG_ 1038 HBCNC_PackUndervoltage 0;
BA_ "GenSigTimeoutTime_IDCM" SG_ 1038 HBCNC_PackUndervoltage 0;
BA_ "GenSigTimeoutTime_SGW" SG_ 1038 HBCNC_PackUndervoltage 0;
BA_ "GenSigTimeoutTime_SGW" SG_ 1038 HBCNC_Micro_Failure 0;
BA_ "GenSigTimeoutTime_PPIM" SG_ 1038 HBCNC_PackOvertemp 0;
BA_ "GenSigTimeoutTime_BPCM" SG_ 1038 HBCNC_PackOvertemp 0;
BA_ "GenSigTimeoutTime_EVCU2" SG_ 1038 HBCNC_PackOvertemp 0;
BA_ "GenSigTimeoutTime_IDCM" SG_ 1038 HBCNC_PackOvertemp 0;
BA_ "GenSigTimeoutTime_SGW" SG_ 1038 HBCNC_PackOvertemp 0;
BA_ "GenSigTimeoutTime_PPIM" SG_ 1038 HBCNC_PackOvervoltage 0;
BA_ "GenSigTimeoutTime_BPCM" SG_ 1038 HBCNC_PackOvervoltage 0;
BA_ "GenSigTimeoutTime_EVCU2" SG_ 1038 HBCNC_PackOvervoltage 0;
BA_ "GenSigTimeoutTime_IDCM" SG_ 1038 HBCNC_PackOvervoltage 0;
BA_ "GenSigTimeoutTime_SGW" SG_ 1038 HBCNC_PackOvervoltage 0;
BA_ "GenSigTimeoutTime_PPIM" SG_ 1038 HBCNC_PackUndertemp 0;
BA_ "GenSigTimeoutTime_BPCM" SG_ 1038 HBCNC_PackUndertemp 0;
BA_ "GenSigTimeoutTime_EVCU2" SG_ 1038 HBCNC_PackUndertemp 0;
BA_ "GenSigTimeoutTime_IDCM" SG_ 1038 HBCNC_PackUndertemp 0;
BA_ "GenSigTimeoutTime_SGW" SG_ 1038 HBCNC_PackUndertemp 0;
BA_ "GenSigTimeoutTime_PPIM" SG_ 1038 HBCO_Sensor_Fault 0;
BA_ "GenSigTimeoutTime_BPCM" SG_ 1038 HBCO_Sensor_Fault 0;
BA_ "GenSigTimeoutTime_EVCU2" SG_ 1038 HBCO_Sensor_Fault 0;
BA_ "GenSigTimeoutTime_IDCM" SG_ 1038 HBCO_Sensor_Fault 0;
BA_ "GenSigTimeoutTime_SGW" SG_ 1038 HBCO_Sensor_Fault 0;
BA_ "GenSigTimeoutTime_PPIM" SG_ 1038 HBCO_TempSensorRationality 0;
BA_ "GenSigTimeoutTime_BPCM" SG_ 1038 HBCO_TempSensorRationality 0;
BA_ "GenSigTimeoutTime_EVCU2" SG_ 1038 HBCO_TempSensorRationality 0;
BA_ "GenSigTimeoutTime_IDCM" SG_ 1038 HBCO_TempSensorRationality 0;
BA_ "GenSigTimeoutTime_SGW" SG_ 1038 HBCO_TempSensorRationality 0;
BA_ "GenSigTimeoutTime_SGW" SG_ 1038 Negative_Main_Closed 0;
BA_ "GenSigTimeoutTime_PPIM" SG_ 1038 Negative_Main_Closed 0;
BA_ "GenSigTimeoutTime_BPCM" SG_ 1038 Negative_Main_Closed 0;
BA_ "GenSigTimeoutTime_EVCU2" SG_ 1038 Negative_Main_Closed 0;
BA_ "GenSigTimeoutTime_IDCM" SG_ 1038 Negative_Main_Closed 0;
BA_ "GenSigTimeoutTime_PPIM" SG_ 1038 Positive_Main_Closed 0;
BA_ "GenSigTimeoutTime_BPCM" SG_ 1038 Positive_Main_Closed 0;
BA_ "GenSigTimeoutTime_EVCU2" SG_ 1038 Positive_Main_Closed 0;
BA_ "GenSigTimeoutTime_IDCM" SG_ 1038 Positive_Main_Closed 0;
BA_ "GenSigTimeoutTime_SGW" SG_ 1038 Positive_Main_Closed 0;
BA_ "GenSigTimeoutTime_PPIM" SG_ 1038 Precharge_Closed 0;
BA_ "GenSigTimeoutTime_BPCM" SG_ 1038 Precharge_Closed 0;
BA_ "GenSigTimeoutTime_EVCU2" SG_ 1038 Precharge_Closed 0;
BA_ "GenSigTimeoutTime_IDCM" SG_ 1038 Precharge_Closed 0;
BA_ "GenSigTimeoutTime_SGW" SG_ 1038 Precharge_Closed 0;
BA_ "GenSigTimeoutTime_PPIM" SG_ 1374 CRC_HVBATTERY4 0;
BA_ "GenSigTimeoutTime_BPCM" SG_ 1374 CRC_HVBATTERY4 0;
BA_ "GenSigTimeoutTime_EVCU2" SG_ 1374 CRC_HVBATTERY4 0;
BA_ "GenSigTimeoutTime_IDCM" SG_ 1374 CRC_HVBATTERY4 0;
BA_ "GenSigTimeoutTime_SGW" SG_ 1374 CRC_HVBATTERY4 0;
BA_ "GenSigTimeoutTime_PPIM" SG_ 1374 MessageCounter_HVBATTERY4 0;
BA_ "GenSigTimeoutTime_BPCM" SG_ 1374 MessageCounter_HVBATTERY4 0;
BA_ "GenSigTimeoutTime_EVCU2" SG_ 1374 MessageCounter_HVBATTERY4 0;
BA_ "GenSigTimeoutTime_IDCM" SG_ 1374 MessageCounter_HVBATTERY4 0;
BA_ "GenSigTimeoutTime_SGW" SG_ 1374 MessageCounter_HVBATTERY4 0;
BA_ "GenSigTimeoutTime_PPIM" SG_ 1038 HBCNC_Isolation_Fault 0;
BA_ "GenSigTimeoutTime_BPCM" SG_ 1038 HBCNC_Isolation_Fault 0;
BA_ "GenSigTimeoutTime_EVCU2" SG_ 1038 HBCNC_Isolation_Fault 0;
BA_ "GenSigTimeoutTime_IDCM" SG_ 1038 HBCNC_Isolation_Fault 0;
BA_ "GenSigTimeoutTime_SGW" SG_ 1038 HBCNC_Isolation_Fault 0;
BA_ "GenSigTimeoutTime_PPIM" SG_ 1038 HBCNC_Impact_Detected 0;
BA_ "GenSigTimeoutTime_BPCM" SG_ 1038 HBCNC_Impact_Detected 0;
BA_ "GenSigTimeoutTime_EVCU2" SG_ 1038 HBCNC_Impact_Detected 0;
BA_ "GenSigTimeoutTime_IDCM" SG_ 1038 HBCNC_Impact_Detected 0;
BA_ "GenSigTimeoutTime_SGW" SG_ 1038 HBCNC_Impact_Detected 0;
BA_ "GenSigTimeoutTime_PPIM" SG_ 1038 HBCNC_Internal_CommFault 0;
BA_ "GenSigTimeoutTime_BPCM" SG_ 1038 HBCNC_Internal_CommFault 0;
BA_ "GenSigTimeoutTime_EVCU2" SG_ 1038 HBCNC_Internal_CommFault 0;
BA_ "GenSigTimeoutTime_IDCM" SG_ 1038 HBCNC_Internal_CommFault 0;
BA_ "GenSigTimeoutTime_SGW" SG_ 1038 HBCNC_Internal_CommFault 0;
BA_ "GenSigTimeoutTime_PPIM" SG_ 1038 HBCNC_CellUndervoltage 0;
BA_ "GenSigTimeoutTime_BPCM" SG_ 1038 HBCNC_CellUndervoltage 0;
BA_ "GenSigTimeoutTime_EVCU2" SG_ 1038 HBCNC_CellUndervoltage 0;
BA_ "GenSigTimeoutTime_IDCM" SG_ 1038 HBCNC_CellUndervoltage 0;
BA_ "GenSigTimeoutTime_SGW" SG_ 1038 HBCNC_CellUndervoltage 0;
BA_ "GenSigTimeoutTime_PPIM" SG_ 1038 HBCNC_Contactors_Welded 0;
BA_ "GenSigTimeoutTime_BPCM" SG_ 1038 HBCNC_Contactors_Welded 0;
BA_ "GenSigTimeoutTime_EVCU2" SG_ 1038 HBCNC_Contactors_Welded 0;
BA_ "GenSigTimeoutTime_IDCM" SG_ 1038 HBCNC_Contactors_Welded 0;
BA_ "GenSigTimeoutTime_SGW" SG_ 1038 HBCNC_Contactors_Welded 0;
BA_ "GenSigTimeoutTime_PPIM" SG_ 1038 HBCNC_EEPROM_Fault 0;
BA_ "GenSigTimeoutTime_BPCM" SG_ 1038 HBCNC_EEPROM_Fault 0;
BA_ "GenSigTimeoutTime_EVCU2" SG_ 1038 HBCNC_EEPROM_Fault 0;
BA_ "GenSigTimeoutTime_IDCM" SG_ 1038 HBCNC_EEPROM_Fault 0;
BA_ "GenSigTimeoutTime_SGW" SG_ 1038 HBCNC_EEPROM_Fault 0;
BA_ "GenSigTimeoutTime_PPIM" SG_ 1038 HBCNC_External_CommFault 0;
BA_ "GenSigTimeoutTime_BPCM" SG_ 1038 HBCNC_External_CommFault 0;
BA_ "GenSigTimeoutTime_EVCU2" SG_ 1038 HBCNC_External_CommFault 0;
BA_ "GenSigTimeoutTime_IDCM" SG_ 1038 HBCNC_External_CommFault 0;
BA_ "GenSigTimeoutTime_SGW" SG_ 1038 HBCNC_External_CommFault 0;
BA_ "GenSigTimeoutTime_PPIM" SG_ 1038 BPCM_DTC_Status2 0;
BA_ "GenSigTimeoutTime_BPCM" SG_ 1038 BPCM_DTC_Status2 0;
BA_ "GenSigTimeoutTime_EVCU2" SG_ 1038 BPCM_DTC_Status2 0;
BA_ "GenSigTimeoutTime_IDCM" SG_ 1038 BPCM_DTC_Status2 0;
BA_ "GenSigTimeoutTime_SGW" SG_ 1038 BPCM_DTC_Status2 0;
BA_ "GenSigTimeoutTime_PPIM" SG_ 1038 BPCM_DTC_Status3 0;
BA_ "GenSigTimeoutTime_BPCM" SG_ 1038 BPCM_DTC_Status3 0;
BA_ "GenSigTimeoutTime_EVCU2" SG_ 1038 BPCM_DTC_Status3 0;
BA_ "GenSigTimeoutTime_IDCM" SG_ 1038 BPCM_DTC_Status3 0;
BA_ "GenSigTimeoutTime_SGW" SG_ 1038 BPCM_DTC_Status3 0;
BA_ "GenSigTimeoutTime_PPIM" SG_ 1038 BPCM_DTC_Status4 0;
BA_ "GenSigTimeoutTime_BPCM" SG_ 1038 BPCM_DTC_Status4 0;
BA_ "GenSigTimeoutTime_EVCU2" SG_ 1038 BPCM_DTC_Status4 0;
BA_ "GenSigTimeoutTime_IDCM" SG_ 1038 BPCM_DTC_Status4 0;
BA_ "GenSigTimeoutTime_SGW" SG_ 1038 BPCM_DTC_Status4 0;
BA_ "GenSigTimeoutTime_PPIM" SG_ 1038 BPCM_DTC_Status5 0;
BA_ "GenSigTimeoutTime_BPCM" SG_ 1038 BPCM_DTC_Status5 0;
BA_ "GenSigTimeoutTime_EVCU2" SG_ 1038 BPCM_DTC_Status5 0;
BA_ "GenSigTimeoutTime_IDCM" SG_ 1038 BPCM_DTC_Status5 0;
BA_ "GenSigTimeoutTime_SGW" SG_ 1038 BPCM_DTC_Status5 0;
BA_ "GenSigTimeoutTime_PPIM" SG_ 1038 BPCM_DTC_Status6 0;
BA_ "GenSigTimeoutTime_BPCM" SG_ 1038 BPCM_DTC_Status6 0;
BA_ "GenSigTimeoutTime_EVCU2" SG_ 1038 BPCM_DTC_Status6 0;
BA_ "GenSigTimeoutTime_IDCM" SG_ 1038 BPCM_DTC_Status6 0;
BA_ "GenSigTimeoutTime_SGW" SG_ 1038 BPCM_DTC_Status6 0;
BA_ "GenSigTimeoutTime_PPIM" SG_ 1038 HBCNC_12V_High 0;
BA_ "GenSigTimeoutTime_BPCM" SG_ 1038 HBCNC_12V_High 0;
BA_ "GenSigTimeoutTime_EVCU2" SG_ 1038 HBCNC_12V_High 0;
BA_ "GenSigTimeoutTime_IDCM" SG_ 1038 HBCNC_12V_High 0;
BA_ "GenSigTimeoutTime_SGW" SG_ 1038 HBCNC_12V_High 0;
BA_ "GenSigTimeoutTime_PPIM" SG_ 1038 HBCNC_12V_Low 0;
BA_ "GenSigTimeoutTime_BPCM" SG_ 1038 HBCNC_12V_Low 0;
BA_ "GenSigTimeoutTime_EVCU2" SG_ 1038 HBCNC_12V_Low 0;
BA_ "GenSigTimeoutTime_IDCM" SG_ 1038 HBCNC_12V_Low 0;
BA_ "GenSigTimeoutTime_SGW" SG_ 1038 HBCNC_12V_Low 0;
BA_ "GenSigTimeoutTime_PPIM" SG_ 1038 HBCNC_CellOvervoltage 0;
BA_ "GenSigTimeoutTime_BPCM" SG_ 1038 HBCNC_CellOvervoltage 0;
BA_ "GenSigTimeoutTime_EVCU2" SG_ 1038 HBCNC_CellOvervoltage 0;
BA_ "GenSigTimeoutTime_IDCM" SG_ 1038 HBCNC_CellOvervoltage 0;
BA_ "GenSigTimeoutTime_SGW" SG_ 1038 HBCNC_CellOvervoltage 0;
BA_ "GenSigTimeoutTime_PPIM" SG_ 1038 BPCM_CalibrationID 0;
BA_ "GenSigStartValue" SG_ 1038 BPCM_CalibrationID 63;
BA_ "GenSigTimeoutTime_BPCM" SG_ 1038 BPCM_CalibrationID 0;
BA_ "GenSigTimeoutTime_EVCU2" SG_ 1038 BPCM_CalibrationID 0;
BA_ "GenSigTimeoutTime_IDCM" SG_ 1038 BPCM_CalibrationID 0;
BA_ "GenSigTimeoutTime_SGW" SG_ 1038 BPCM_CalibrationID 0;
BA_ "GenSigTimeoutTime_PPIM" SG_ 1038 BPCM_CalibrationVN 0;
BA_ "GenSigTimeoutTime_BPCM" SG_ 1038 BPCM_CalibrationVN 0;
BA_ "GenSigTimeoutTime_EVCU2" SG_ 1038 BPCM_CalibrationVN 0;
BA_ "GenSigTimeoutTime_IDCM" SG_ 1038 BPCM_CalibrationVN 0;
BA_ "GenSigTimeoutTime_SGW" SG_ 1038 BPCM_CalibrationVN 0;
BA_ "GenSigTimeoutTime_PPIM" SG_ 1038 BPCM_DTC_Index1 0;
BA_ "GenSigTimeoutTime_BPCM" SG_ 1038 BPCM_DTC_Index1 0;
BA_ "GenSigTimeoutTime_EVCU2" SG_ 1038 BPCM_DTC_Index1 0;
BA_ "GenSigTimeoutTime_IDCM" SG_ 1038 BPCM_DTC_Index1 0;
BA_ "GenSigTimeoutTime_SGW" SG_ 1038 BPCM_DTC_Index1 0;
BA_ "GenSigTimeoutTime_PPIM" SG_ 1038 BPCM_DTC_Index2 0;
BA_ "GenSigTimeoutTime_BPCM" SG_ 1038 BPCM_DTC_Index2 0;
BA_ "GenSigTimeoutTime_EVCU2" SG_ 1038 BPCM_DTC_Index2 0;
BA_ "GenSigTimeoutTime_IDCM" SG_ 1038 BPCM_DTC_Index2 0;
BA_ "GenSigTimeoutTime_SGW" SG_ 1038 BPCM_DTC_Index2 0;
BA_ "GenSigTimeoutTime_PPIM" SG_ 1038 BPCM_DTC_Index3 0;
BA_ "GenSigTimeoutTime_BPCM" SG_ 1038 BPCM_DTC_Index3 0;
BA_ "GenSigTimeoutTime_EVCU2" SG_ 1038 BPCM_DTC_Index3 0;
BA_ "GenSigTimeoutTime_IDCM" SG_ 1038 BPCM_DTC_Index3 0;
BA_ "GenSigTimeoutTime_SGW" SG_ 1038 BPCM_DTC_Index3 0;
BA_ "GenSigTimeoutTime_PPIM" SG_ 1038 BPCM_DTC_Index4 0;
BA_ "GenSigTimeoutTime_BPCM" SG_ 1038 BPCM_DTC_Index4 0;
BA_ "GenSigTimeoutTime_EVCU2" SG_ 1038 BPCM_DTC_Index4 0;
BA_ "GenSigTimeoutTime_IDCM" SG_ 1038 BPCM_DTC_Index4 0;
BA_ "GenSigTimeoutTime_SGW" SG_ 1038 BPCM_DTC_Index4 0;
BA_ "GenSigTimeoutTime_PPIM" SG_ 1038 BPCM_DTC_Index5 0;
BA_ "GenSigTimeoutTime_BPCM" SG_ 1038 BPCM_DTC_Index5 0;
BA_ "GenSigTimeoutTime_EVCU2" SG_ 1038 BPCM_DTC_Index5 0;
BA_ "GenSigTimeoutTime_IDCM" SG_ 1038 BPCM_DTC_Index5 0;
BA_ "GenSigTimeoutTime_SGW" SG_ 1038 BPCM_DTC_Index5 0;
BA_ "GenSigTimeoutTime_PPIM" SG_ 1038 BPCM_DTC_Index6 0;
BA_ "GenSigTimeoutTime_BPCM" SG_ 1038 BPCM_DTC_Index6 0;
BA_ "GenSigTimeoutTime_EVCU2" SG_ 1038 BPCM_DTC_Index6 0;
BA_ "GenSigTimeoutTime_IDCM" SG_ 1038 BPCM_DTC_Index6 0;
BA_ "GenSigTimeoutTime_SGW" SG_ 1038 BPCM_DTC_Index6 0;
BA_ "GenSigTimeoutTime_PPIM" SG_ 1038 BPCM_DTC_Status1 0;
BA_ "GenSigTimeoutTime_BPCM" SG_ 1038 BPCM_DTC_Status1 0;
BA_ "GenSigTimeoutTime_EVCU2" SG_ 1038 BPCM_DTC_Status1 0;
BA_ "GenSigTimeoutTime_IDCM" SG_ 1038 BPCM_DTC_Status1 0;
BA_ "GenSigTimeoutTime_SGW" SG_ 1038 BPCM_DTC_Status1 0;
BA_ "GenSigTimeoutTime_HCP" SG_ 1374 HVBatCapacity_AmpHr 0;
BA_ "GenSigTimeoutTime_PPIM" SG_ 1374 HVBatCapacity_AmpHr 0;
BA_ "GenSigTimeoutTime_BPCM" SG_ 1374 HVBatCapacity_AmpHr 0;
BA_ "GenSigTimeoutTime_EVCU2" SG_ 1374 HVBatCapacity_AmpHr 0;
BA_ "GenSigTimeoutTime_PPIM" SG_ 1038 BPCM_Odometer 0;
BA_ "GenSigTimeoutTime_BPCM" SG_ 1038 BPCM_Odometer 0;
BA_ "GenSigTimeoutTime_EVCU2" SG_ 1038 BPCM_Odometer 0;
BA_ "GenSigTimeoutTime_IDCM" SG_ 1038 BPCM_Odometer 0;
BA_ "GenSigTimeoutTime_SGW" SG_ 1038 BPCM_Odometer 0;
BA_ "GenSigTimeoutTime_HCP" SG_ 2654486626 CBV_bit2_1E384062 0;
BA_ "GenSigTimeoutTime_PPIM" SG_ 2654486626 CBV_bit2_1E384062 0;
BA_ "GenSigTimeoutTime_BPCM" SG_ 2654486626 CBV_bit2_1E384062 0;
BA_ "GenSigTimeoutTime_EVCU2" SG_ 2654486626 CBV_bit2_1E384062 0;
BA_ "GenSigTimeoutTime_IDCM" SG_ 2654486626 CBV_bit2_1E384062 0;
BA_ "GenSigTimeoutTime_SGW" SG_ 2654486626 CBV_bit2_1E384062 0;
BA_ "GenSigTimeoutTime_HCP" SG_ 2654486626 CBV_bit1_1E384062 0;
BA_ "GenSigTimeoutTime_PPIM" SG_ 2654486626 CBV_bit1_1E384062 0;
BA_ "GenSigTimeoutTime_BPCM" SG_ 2654486626 CBV_bit1_1E384062 0;
BA_ "GenSigTimeoutTime_EVCU2" SG_ 2654486626 CBV_bit1_1E384062 0;
BA_ "GenSigTimeoutTime_IDCM" SG_ 2654486626 CBV_bit1_1E384062 0;
BA_ "GenSigTimeoutTime_SGW" SG_ 2654486626 CBV_bit1_1E384062 0;
BA_ "GenSigTimeoutTime_HCP" SG_ 2654486626 SourceNodeIdentifier_1E384062 0;
BA_ "GenSigTimeoutTime_PPIM" SG_ 2654486626 SourceNodeIdentifier_1E384062 0;
BA_ "GenSigTimeoutTime_BPCM" SG_ 2654486626 SourceNodeIdentifier_1E384062 0;
BA_ "GenSigTimeoutTime_EVCU2" SG_ 2654486626 SourceNodeIdentifier_1E384062 0;
BA_ "GenSigTimeoutTime_IDCM" SG_ 2654486626 SourceNodeIdentifier_1E384062 0;
BA_ "GenSigTimeoutTime_SGW" SG_ 2654486626 SourceNodeIdentifier_1E384062 0;
BA_ "GenSigTimeoutTime_HCP" SG_ 2654486626 CBV_bit7_1E384062 0;
BA_ "GenSigTimeoutTime_PPIM" SG_ 2654486626 CBV_bit7_1E384062 0;
BA_ "GenSigTimeoutTime_BPCM" SG_ 2654486626 CBV_bit7_1E384062 0;
BA_ "GenSigTimeoutTime_EVCU2" SG_ 2654486626 CBV_bit7_1E384062 0;
BA_ "GenSigTimeoutTime_IDCM" SG_ 2654486626 CBV_bit7_1E384062 0;
BA_ "GenSigTimeoutTime_SGW" SG_ 2654486626 CBV_bit7_1E384062 0;
BA_ "GenSigTimeoutTime_HCP" SG_ 2654486626 CBV_bit5_1E384062 0;
BA_ "GenSigTimeoutTime_PPIM" SG_ 2654486626 CBV_bit5_1E384062 0;
BA_ "GenSigTimeoutTime_BPCM" SG_ 2654486626 CBV_bit5_1E384062 0;
BA_ "GenSigTimeoutTime_EVCU2" SG_ 2654486626 CBV_bit5_1E384062 0;
BA_ "GenSigTimeoutTime_IDCM" SG_ 2654486626 CBV_bit5_1E384062 0;
BA_ "GenSigTimeoutTime_SGW" SG_ 2654486626 CBV_bit5_1E384062 0;
BA_ "GenSigTimeoutTime_HCP" SG_ 2654486626 CBV_bit3_NMCoordinatorBit_1E384062 0;
BA_ "GenSigTimeoutTime_PPIM" SG_ 2654486626 CBV_bit3_NMCoordinatorBit_1E384062 0;
BA_ "GenSigTimeoutTime_BPCM" SG_ 2654486626 CBV_bit3_NMCoordinatorBit_1E384062 0;
BA_ "GenSigTimeoutTime_EVCU2" SG_ 2654486626 CBV_bit3_NMCoordinatorBit_1E384062 0;
BA_ "GenSigTimeoutTime_IDCM" SG_ 2654486626 CBV_bit3_NMCoordinatorBit_1E384062 0;
BA_ "GenSigTimeoutTime_SGW" SG_ 2654486626 CBV_bit3_NMCoordinatorBit_1E384062 0;
BA_ "GenSigTimeoutTime_HCP" SG_ 2654486626 CBV_bit0_RepeatMessageRequestBit_1E384062 0;
BA_ "GenSigTimeoutTime_PPIM" SG_ 2654486626 CBV_bit0_RepeatMessageRequestBit_1E384062 0;
BA_ "GenSigTimeoutTime_BPCM" SG_ 2654486626 CBV_bit0_RepeatMessageRequestBit_1E384062 0;
BA_ "GenSigTimeoutTime_EVCU2" SG_ 2654486626 CBV_bit0_RepeatMessageRequestBit_1E384062 0;
BA_ "GenSigTimeoutTime_IDCM" SG_ 2654486626 CBV_bit0_RepeatMessageRequestBit_1E384062 0;
BA_ "GenSigTimeoutTime_SGW" SG_ 2654486626 CBV_bit0_RepeatMessageRequestBit_1E384062 0;
BA_ "GenSigTimeoutTime_BPCM" SG_ 2654486626 CBV_bit6_PartialNtwInfBit_1E384062 0;
BA_ "GenSigTimeoutTime_EVCU2" SG_ 2654486626 CBV_bit6_PartialNtwInfBit_1E384062 0;
BA_ "GenSigTimeoutTime_IDCM" SG_ 2654486626 CBV_bit6_PartialNtwInfBit_1E384062 0;
BA_ "GenSigTimeoutTime_SGW" SG_ 2654486626 CBV_bit6_PartialNtwInfBit_1E384062 0;
BA_ "GenSigTimeoutTime_HCP" SG_ 2654486626 CBV_bit6_PartialNtwInfBit_1E384062 0;
BA_ "GenSigTimeoutTime_PPIM" SG_ 2654486626 CBV_bit6_PartialNtwInfBit_1E384062 0;
BA_ "GenSigTimeoutTime_HCP" SG_ 2654486626 CBV_bit4_ActiveWakeupBit_1E384062 0;
BA_ "GenSigTimeoutTime_PPIM" SG_ 2654486626 CBV_bit4_ActiveWakeupBit_1E384062 0;
BA_ "GenSigTimeoutTime_BPCM" SG_ 2654486626 CBV_bit4_ActiveWakeupBit_1E384062 0;
BA_ "GenSigTimeoutTime_EVCU2" SG_ 2654486626 CBV_bit4_ActiveWakeupBit_1E384062 0;
BA_ "GenSigTimeoutTime_IDCM" SG_ 2654486626 CBV_bit4_ActiveWakeupBit_1E384062 0;
BA_ "GenSigTimeoutTime_SGW" SG_ 2654486626 CBV_bit4_ActiveWakeupBit_1E384062 0;
BA_ "GenSigTimeoutTime_HCP" SG_ 2654339170 StayActiveSource_FD03_HCP 0;
BA_ "GenSigTimeoutTime_PPIM" SG_ 2654339170 StayActiveSource_FD03_HCP 0;
BA_ "GenSigTimeoutTime_BPCM" SG_ 2654339170 StayActiveSource_FD03_HCP 0;
BA_ "GenSigTimeoutTime_EVCU2" SG_ 2654339170 StayActiveSource_FD03_HCP 0;
BA_ "GenSigTimeoutTime_IDCM" SG_ 2654339170 StayActiveSource_FD03_HCP 0;
BA_ "GenSigTimeoutTime_IDCM" SG_ 1374 HVBatCapacity_AmpHr 0;
BA_ "GenSigTimeoutTime_SGW" SG_ 1374 HVBatCapacity_AmpHr 0;
BA_ "GenSigTimeoutTime_HCP" SG_ 1374 HVBatCapacity_AmpHrV 0;
BA_ "GenSigTimeoutTime_PPIM" SG_ 1374 HVBatCapacity_AmpHrV 0;
BA_ "GenSigTimeoutTime_BPCM" SG_ 1374 HVBatCapacity_AmpHrV 0;
BA_ "GenSigTimeoutTime_EVCU2" SG_ 1374 HVBatCapacity_AmpHrV 0;
BA_ "GenSigTimeoutTime_IDCM" SG_ 1374 HVBatCapacity_AmpHrV 0;
BA_ "GenSigTimeoutTime_SGW" SG_ 1374 HVBatCapacity_AmpHrV 0;
BA_ "GenSigTimeoutTime_PPIM" SG_ 1374 HVBatPackVoltage_MaxAllowedV 0;
BA_ "GenSigTimeoutTime_BPCM" SG_ 1374 HVBatPackVoltage_MaxAllowedV 0;
BA_ "GenSigTimeoutTime_EVCU2" SG_ 1374 HVBatPackVoltage_MaxAllowedV 0;
BA_ "GenSigTimeoutTime_IDCM" SG_ 1374 HVBatPackVoltage_MaxAllowedV 0;
BA_ "GenSigTimeoutTime_SGW" SG_ 1374 HVBatPackVoltage_MaxAllowedV 0;
BA_ "GenSigTimeoutTime_PPIM" SG_ 1374 HVBatCellVoltage_MinAllowed 0;
BA_ "GenSigTimeoutTime_BPCM" SG_ 1374 HVBatCellVoltage_MinAllowed 0;
BA_ "GenSigTimeoutTime_EVCU2" SG_ 1374 HVBatCellVoltage_MinAllowed 0;
BA_ "GenSigTimeoutTime_IDCM" SG_ 1374 HVBatCellVoltage_MinAllowed 0;
BA_ "GenSigTimeoutTime_SGW" SG_ 1374 HVBatCellVoltage_MinAllowed 0;
BA_ "GenSigTimeoutTime_PPIM" SG_ 1374 HVBatCellVoltage_MinAllowedV 0;
BA_ "GenSigTimeoutTime_BPCM" SG_ 1374 HVBatCellVoltage_MinAllowedV 0;
BA_ "GenSigTimeoutTime_EVCU2" SG_ 1374 HVBatCellVoltage_MinAllowedV 0;
BA_ "GenSigTimeoutTime_IDCM" SG_ 1374 HVBatCellVoltage_MinAllowedV 0;
BA_ "GenSigTimeoutTime_SGW" SG_ 1374 HVBatCellVoltage_MinAllowedV 0;
BA_ "GenSigTimeoutTime_PPIM" SG_ 1374 HVBatCellVoltage_HighThreshold 0;
BA_ "GenSigTimeoutTime_BPCM" SG_ 1374 HVBatCellVoltage_HighThreshold 0;
BA_ "GenSigTimeoutTime_EVCU2" SG_ 1374 HVBatCellVoltage_HighThreshold 0;
BA_ "GenSigTimeoutTime_IDCM" SG_ 1374 HVBatCellVoltage_HighThreshold 0;
BA_ "GenSigTimeoutTime_SGW" SG_ 1374 HVBatCellVoltage_HighThreshold 0;
BA_ "GenSigTimeoutTime_PPIM" SG_ 1374 HVBatCellVoltage_LowThreshold 0;
BA_ "GenSigTimeoutTime_BPCM" SG_ 1374 HVBatCellVoltage_LowThreshold 0;
BA_ "GenSigTimeoutTime_EVCU2" SG_ 1374 HVBatCellVoltage_LowThreshold 0;
BA_ "GenSigTimeoutTime_IDCM" SG_ 1374 HVBatCellVoltage_LowThreshold 0;
BA_ "GenSigTimeoutTime_SGW" SG_ 1374 HVBatCellVoltage_LowThreshold 0;
BA_ "GenSigTimeoutTime_PPIM" SG_ 1374 HVBatCellVoltage_MaxAllowed 0;
BA_ "GenSigTimeoutTime_BPCM" SG_ 1374 HVBatCellVoltage_MaxAllowed 0;
BA_ "GenSigTimeoutTime_EVCU2" SG_ 1374 HVBatCellVoltage_MaxAllowed 0;
BA_ "GenSigTimeoutTime_IDCM" SG_ 1374 HVBatCellVoltage_MaxAllowed 0;
BA_ "GenSigTimeoutTime_SGW" SG_ 1374 HVBatCellVoltage_MaxAllowed 0;
BA_ "GenSigTimeoutTime_PPIM" SG_ 1374 HVBatCellVoltage_MaxAllowedV 0;
BA_ "GenSigTimeoutTime_BPCM" SG_ 1374 HVBatCellVoltage_MaxAllowedV 0;
BA_ "GenSigTimeoutTime_EVCU2" SG_ 1374 HVBatCellVoltage_MaxAllowedV 0;
BA_ "GenSigTimeoutTime_IDCM" SG_ 1374 HVBatCellVoltage_MaxAllowedV 0;
BA_ "GenSigTimeoutTime_SGW" SG_ 1374 HVBatCellVoltage_MaxAllowedV 0;
BA_ "GenSigTimeoutTime_HCP" SG_ 1436 Blower_Speed 0;
BA_ "GenSigTimeoutTime_PPIM" SG_ 1436 Blower_Speed 0;
BA_ "GenSigSendType" SG_ 1436 Blower_Speed 3;
BA_ "GenSigTimeoutTime_EVCU2" SG_ 1436 Blower_Speed 0;
BA_ "GenSigTimeoutTime_IDCM" SG_ 1436 Blower_Speed 0;
BA_ "GenSigTimeoutTime_SGW" SG_ 1436 Blower_Speed 0;
BA_ "GenSigTimeoutTime_HCP" SG_ 1035 EngCltTmp 0;
BA_ "GenSigTimeoutTime_PPIM" SG_ 1035 EngCltTmp 0;
BA_ "GenSigStartValue" SG_ 1035 EngCltTmp 255;
BA_ "GenSigTimeoutTime_EVCU2" SG_ 1035 EngCltTmp 0;
BA_ "GenSigTimeoutTime_IDCM" SG_ 1035 EngCltTmp 0;
BA_ "GenSigTimeoutTime_SGW" SG_ 1035 EngCltTmp 0;
BA_ "GenSigTimeoutTime_HCP" SG_ 2654339170 EOL_FD03_HCP 0;
BA_ "GenSigTimeoutTime_PPIM" SG_ 2654339170 EOL_FD03_HCP 0;
BA_ "GenSigTimeoutTime_BPCM" SG_ 2654339170 EOL_FD03_HCP 0;
BA_ "GenSigTimeoutTime_EVCU2" SG_ 2654339170 EOL_FD03_HCP 0;
BA_ "GenSigTimeoutTime_IDCM" SG_ 2654339170 EOL_FD03_HCP 0;
BA_ "GenSigTimeoutTime_HCP" SG_ 2654339170 GenericFailSts_FD03_HCP 0;
BA_ "GenSigTimeoutTime_PPIM" SG_ 2654339170 GenericFailSts_FD03_HCP 0;
BA_ "GenSigTimeoutTime_BPCM" SG_ 2654339170 GenericFailSts_FD03_HCP 0;
BA_ "GenSigTimeoutTime_EVCU2" SG_ 2654339170 GenericFailSts_FD03_HCP 0;
BA_ "GenSigTimeoutTime_IDCM" SG_ 2654339170 GenericFailSts_FD03_HCP 0;
BA_ "GenSigTimeoutTime_HCP" SG_ 2654339170 CurrentFailSts_FD03_HCP 0;
BA_ "GenSigTimeoutTime_PPIM" SG_ 2654339170 CurrentFailSts_FD03_HCP 0;
BA_ "GenSigTimeoutTime_BPCM" SG_ 2654339170 CurrentFailSts_FD03_HCP 0;
BA_ "GenSigTimeoutTime_EVCU2" SG_ 2654339170 CurrentFailSts_FD03_HCP 0;
BA_ "GenSigTimeoutTime_IDCM" SG_ 2654339170 CurrentFailSts_FD03_HCP 0;
BA_ "GenSigTimeoutTime_HCP" SG_ 2564682059 N_PDU_18DDF14B 0;
BA_ "GenSigTimeoutTime_PPIM" SG_ 2564682059 N_PDU_18DDF14B 0;
BA_ "GenSigTimeoutTime_BPCM" SG_ 2564682059 N_PDU_18DDF14B 0;
BA_ "GenSigTimeoutTime_EVCU2" SG_ 2564682059 N_PDU_18DDF14B 0;
BA_ "GenSigTimeoutTime_IDCM" SG_ 2564682059 N_PDU_18DDF14B 0;
BA_ "GenSigTimeoutTime_SGW" SG_ 2564682059 N_PDU_18DDF14B 0;
BA_ "GenSigTimeoutTime_HCP" SG_ 2564682315 N_PDU_18DDF24B 0;
BA_ "GenSigTimeoutTime_PPIM" SG_ 2564682315 N_PDU_18DDF24B 0;
BA_ "GenSigTimeoutTime_BPCM" SG_ 2564682315 N_PDU_18DDF24B 0;
BA_ "GenSigTimeoutTime_EVCU2" SG_ 2564682315 N_PDU_18DDF24B 0;
BA_ "GenSigTimeoutTime_IDCM" SG_ 2564682315 N_PDU_18DDF24B 0;
BA_ "GenSigTimeoutTime_SGW" SG_ 2564682315 N_PDU_18DDF24B 0;
BA_ "GenSigTimeoutTime_HCP" SG_ 2564485707 N_PDU_18DAF24B 0;
BA_ "GenSigTimeoutTime_PPIM" SG_ 2564485707 N_PDU_18DAF24B 0;
BA_ "GenSigTimeoutTime_BPCM" SG_ 2564485707 N_PDU_18DAF24B 0;
BA_ "GenSigTimeoutTime_EVCU2" SG_ 2564485707 N_PDU_18DAF24B 0;
BA_ "GenSigTimeoutTime_IDCM" SG_ 2564485707 N_PDU_18DAF24B 0;
BA_ "GenSigTimeoutTime_SGW" SG_ 2564485707 N_PDU_18DAF24B 0;
BA_ "GenSigTimeoutTime_PPIM" SG_ 1374 BSGPackVoltage_MaxAllowed 0;
BA_ "GenSigStartValue" SG_ 1374 BSGPackVoltage_MaxAllowed 36;
BA_ "GenSigTimeoutTime_BPCM" SG_ 1374 BSGPackVoltage_MaxAllowed 0;
BA_ "GenSigTimeoutTime_EVCU2" SG_ 1374 BSGPackVoltage_MaxAllowed 0;
BA_ "GenSigTimeoutTime_IDCM" SG_ 1374 BSGPackVoltage_MaxAllowed 0;
BA_ "GenSigTimeoutTime_SGW" SG_ 1374 BSGPackVoltage_MaxAllowed 0;
BA_ "GenSigTimeoutTime_PPIM" SG_ 1374 HVBatChargeAmpHrs 0;
BA_ "GenSigTimeoutTime_BPCM" SG_ 1374 HVBatChargeAmpHrs 0;
BA_ "GenSigTimeoutTime_EVCU2" SG_ 1374 HVBatChargeAmpHrs 0;
BA_ "GenSigTimeoutTime_IDCM" SG_ 1374 HVBatChargeAmpHrs 0;
BA_ "GenSigTimeoutTime_SGW" SG_ 1374 HVBatChargeAmpHrs 0;
BA_ "GenSigTimeoutTime_HCP" SG_ 2564443122 N_PDU_18DA4BF2 0;
BA_ "GenSigTimeoutTime_PPIM" SG_ 2564443122 N_PDU_18DA4BF2 0;
BA_ "GenSigTimeoutTime_BPCM" SG_ 2564443122 N_PDU_18DA4BF2 0;
BA_ "GenSigTimeoutTime_EVCU2" SG_ 2564443122 N_PDU_18DA4BF2 0;
BA_ "GenSigTimeoutTime_IDCM" SG_ 2564443122 N_PDU_18DA4BF2 0;
BA_ "GenSigTimeoutTime_SGW" SG_ 2564443122 N_PDU_18DA4BF2 0;
BA_ "GenSigTimeoutTime_HCP" SG_ 2654339170 CurrentCanNMState_FD03_HCP 0;
BA_ "GenSigTimeoutTime_PPIM" SG_ 2654339170 CurrentCanNMState_FD03_HCP 0;
BA_ "GenSigTimeoutTime_VDCM" SG_ 2654339223 StayActiveSource_FD11_APM2 0;
BA_ "GenSigTimeoutTime_APM2" SG_ 2654339223 StayActiveSource_FD11_APM2 0;
BA_ "GenSigTimeoutTime_BPCM" SG_ 2654339223 StayActiveSource_FD11_APM2 0;
BA_ "GenSigTimeoutTime_IDCM" SG_ 2654339223 StayActiveSource_FD11_APM2 0;
BA_ "GenSigTimeoutTime_HCP" SG_ 1460 MessageCounter_FOTA_MASTER 0;
BA_ "GenSigTimeoutTime_PPIM" SG_ 1460 MessageCounter_FOTA_MASTER 0;
BA_ "GenSigTimeoutTime_BPCM" SG_ 1460 MessageCounter_FOTA_MASTER 0;
BA_ "GenSigTimeoutTime_IDCM" SG_ 1460 MessageCounter_FOTA_MASTER 0;
BA_ "GenSigTimeoutTime_SGW" SG_ 1460 MessageCounter_FOTA_MASTER 0;
BA_ "GenSigTimeoutTime_HCP" SG_ 1460 CRC_FOTA_MASTER 0;
BA_ "GenSigTimeoutTime_PPIM" SG_ 1460 CRC_FOTA_MASTER 0;
BA_ "GenSigTimeoutTime_BPCM" SG_ 1460 CRC_FOTA_MASTER 0;
BA_ "GenSigTimeoutTime_IDCM" SG_ 1460 CRC_FOTA_MASTER 0;
BA_ "GenSigTimeoutTime_SGW" SG_ 1460 CRC_FOTA_MASTER 0;
BA_ "GenSigTimeoutTime_HCP" SG_ 1578 MessageCounter_HV_CHARGER2 0;
BA_ "GenSigTimeoutTime_PPIM" SG_ 1578 MessageCounter_HV_CHARGER2 0;
BA_ "GenSigTimeoutTime_HCP" SG_ 1578 CRC_HV_CHARGER2 0;
BA_ "GenSigTimeoutTime_PPIM" SG_ 1578 CRC_HV_CHARGER2 0;
BA_ "GenSigTimeoutTime_BPCM" SG_ 1578 CRC_HV_CHARGER2 0;
BA_ "GenSigTimeoutTime_IDCM" SG_ 1578 CRC_HV_CHARGER2 0;
BA_ "GenSigTimeoutTime_SGW" SG_ 1578 CRC_HV_CHARGER2 0;
BA_ "GenSigTimeoutTime_BPCM" SG_ 1578 MessageCounter_HV_CHARGER2 0;
BA_ "GenSigTimeoutTime_IDCM" SG_ 1578 MessageCounter_HV_CHARGER2 0;
BA_ "GenSigTimeoutTime_SGW" SG_ 1578 MessageCounter_HV_CHARGER2 0;
BA_ "GenSigTimeoutTime_HCP" SG_ 478 MessageCounter_HYBRID_CHARGING__1DE 0;
BA_ "GenSigTimeoutTime_PPIM" SG_ 478 MessageCounter_HYBRID_CHARGING__1DE 0;
BA_ "GenSigTimeoutTime_APM2" SG_ 478 MessageCounter_HYBRID_CHARGING__1DE 0;
BA_ "GenSigTimeoutTime_VDCM" SG_ 478 MessageCounter_HYBRID_CHARGING__1DE 0;
BA_ "GenSigTimeoutTime_HCP" SG_ 478 MaxCurrentAllwd 0;
BA_ "GenSigTimeoutTime_PPIM" SG_ 478 MaxCurrentAllwd 0;
BA_ "GenSigTimeoutTime_APM2" SG_ 478 MaxCurrentAllwd 0;
BA_ "GenSigTimeoutTime_VDCM" SG_ 478 MaxCurrentAllwd 0;
BA_ "GenSigTimeoutTime_BPCM" SG_ 478 MaxCurrentAllwd 0;
BA_ "GenSigTimeoutTime_EVCU2" SG_ 478 MaxCurrentAllwd 0;
BA_ "GenSigTimeoutTime_SGW" SG_ 478 MaxCurrentAllwd 0;
BA_ "GenSigTimeoutTime_HCP" SG_ 1579 MessageCounter_HYBRID_CHARGING__62B 0;
BA_ "GenSigTimeoutTime_PPIM" SG_ 1579 MessageCounter_HYBRID_CHARGING__62B 0;
BA_ "GenSigTimeoutTime_APM2" SG_ 1579 MessageCounter_HYBRID_CHARGING__62B 0;
BA_ "GenSigTimeoutTime_VDCM" SG_ 1579 MessageCounter_HYBRID_CHARGING__62B 0;
BA_ "SystemSignalLongSymbol" SG_ 1579 MessageCounter_HYBRID_CHARGING__62B "MessageCounter_HYBRID_CHARGING_STATUS";
BA_ "GenSigTimeoutTime_BPCM" SG_ 1579 MessageCounter_HYBRID_CHARGING__62B 0;
BA_ "GenSigTimeoutTime_EVCU2" SG_ 1579 MessageCounter_HYBRID_CHARGING__62B 0;
BA_ "GenSigTimeoutTime_SGW" SG_ 1579 MessageCounter_HYBRID_CHARGING__62B 0;
BA_ "SystemSignalLongSymbol" SG_ 478 MessageCounter_HYBRID_CHARGING__1DE "MessageCounter_HYBRID_CHARGING_COMMAND";
BA_ "GenSigTimeoutTime_BPCM" SG_ 478 MessageCounter_HYBRID_CHARGING__1DE 0;
BA_ "GenSigTimeoutTime_EVCU2" SG_ 478 MessageCounter_HYBRID_CHARGING__1DE 0;
BA_ "GenSigTimeoutTime_SGW" SG_ 478 MessageCounter_HYBRID_CHARGING__1DE 0;
BA_ "GenSigTimeoutTime_BPCM" SG_ 2654339170 CurrentCanNMState_FD03_HCP 0;
BA_ "GenSigTimeoutTime_EVCU2" SG_ 2654339170 CurrentCanNMState_FD03_HCP 0;
BA_ "GenSigTimeoutTime_IDCM" SG_ 2654339170 CurrentCanNMState_FD03_HCP 0;
BA_ "GenSigTimeoutTime_HCP" SG_ 2654339170 WakeupSource_FD03_HCP 0;
BA_ "GenSigTimeoutTime_PPIM" SG_ 2654339170 WakeupSource_FD03_HCP 0;
BA_ "GenSigTimeoutTime_BPCM" SG_ 2654339170 WakeupSource_FD03_HCP 0;
BA_ "GenSigTimeoutTime_EVCU2" SG_ 2654339170 WakeupSource_FD03_HCP 0;
BA_ "GenSigTimeoutTime_IDCM" SG_ 2654339170 WakeupSource_FD03_HCP 0;
BA_ "GenSigTimeoutTime_HCP" SG_ 2654339170 DES_FD03_HCP 0;
BA_ "GenSigTimeoutTime_PPIM" SG_ 2654339170 DES_FD03_HCP 0;
BA_ "GenSigTimeoutTime_BPCM" SG_ 2654339170 DES_FD03_HCP 0;
BA_ "GenSigTimeoutTime_EVCU2" SG_ 2654339170 DES_FD03_HCP 0;
BA_ "GenSigTimeoutTime_IDCM" SG_ 2654339170 DES_FD03_HCP 0;
BA_ "GenSigTimeoutTime_HCP" SG_ 2654339170 PreviousCanNMState_FD03_HCP 0;
BA_ "GenSigTimeoutTime_PPIM" SG_ 2654339170 PreviousCanNMState_FD03_HCP 0;
BA_ "GenSigTimeoutTime_BPCM" SG_ 2654339170 PreviousCanNMState_FD03_HCP 0;
BA_ "GenSigTimeoutTime_EVCU2" SG_ 2654339170 PreviousCanNMState_FD03_HCP 0;
BA_ "GenSigTimeoutTime_IDCM" SG_ 2654339170 PreviousCanNMState_FD03_HCP 0;
BA_ "GenSigTimeoutTime_PPIM" SG_ 1374 HVBatDischargeAmpHrs 0;
BA_ "GenSigTimeoutTime_BPCM" SG_ 1374 HVBatDischargeAmpHrs 0;
BA_ "GenSigTimeoutTime_EVCU2" SG_ 1374 HVBatDischargeAmpHrs 0;
BA_ "GenSigTimeoutTime_IDCM" SG_ 1374 HVBatDischargeAmpHrs 0;
BA_ "GenSigTimeoutTime_SGW" SG_ 1374 HVBatDischargeAmpHrs 0;
BA_ "GenSigTimeoutTime_PPIM" SG_ 1374 HVBatRemainingAhCapacity 0;
BA_ "GenSigTimeoutTime_BPCM" SG_ 1374 HVBatRemainingAhCapacity 0;
BA_ "GenSigTimeoutTime_EVCU2" SG_ 1374 HVBatRemainingAhCapacity 0;
BA_ "GenSigTimeoutTime_IDCM" SG_ 1374 HVBatRemainingAhCapacity 0;
BA_ "GenSigTimeoutTime_SGW" SG_ 1374 HVBatRemainingAhCapacity 0;
BA_ "GenSigTimeoutTime_HCP" SG_ 1035 EngCltTmpV 0;
BA_ "GenSigTimeoutTime_PPIM" SG_ 1035 EngCltTmpV 0;
BA_ "GenSigTimeoutTime_EVCU2" SG_ 1035 EngCltTmpV 0;
BA_ "GenSigTimeoutTime_IDCM" SG_ 1035 EngCltTmpV 0;
BA_ "GenSigTimeoutTime_SGW" SG_ 1035 EngCltTmpV 0;
BA_ "GenSigTimeoutTime_HCP" SG_ 1035 EngSpd 0;
BA_ "GenSigTimeoutTime_PPIM" SG_ 1035 EngSpd 0;
BA_ "GenSigTimeoutTime_EVCU2" SG_ 1035 EngSpd 0;
BA_ "GenSigTimeoutTime_IDCM" SG_ 1035 EngSpd 0;
BA_ "GenSigTimeoutTime_SGW" SG_ 1035 EngSpd 0;
BA_ "GenSigTimeoutTime_HCP" SG_ 1035 RadFanReq 0;
BA_ "GenSigTimeoutTime_PPIM" SG_ 1035 RadFanReq 0;
BA_ "GenSigTimeoutTime_EVCU2" SG_ 1035 RadFanReq 0;
BA_ "GenSigTimeoutTime_IDCM" SG_ 1035 RadFanReq 0;
BA_ "GenSigTimeoutTime_SGW" SG_ 1035 RadFanReq 0;
BA_ "GenSigTimeoutTime_VDCM" SG_ 2654339223 WakeupSource_FD11_APM2 0;
BA_ "GenSigTimeoutTime_APM2" SG_ 2654339223 WakeupSource_FD11_APM2 0;
BA_ "GenSigTimeoutTime_BPCM" SG_ 2654339223 WakeupSource_FD11_APM2 0;
BA_ "GenSigTimeoutTime_IDCM" SG_ 2654339223 WakeupSource_FD11_APM2 0;
BA_ "GenSigTimeoutTime_VDCM" SG_ 2654339223 GenericFailSts_FD11_APM2 0;
BA_ "GenSigTimeoutTime_APM2" SG_ 2654339223 GenericFailSts_FD11_APM2 0;
BA_ "GenSigTimeoutTime_BPCM" SG_ 2654339223 GenericFailSts_FD11_APM2 0;
BA_ "GenSigTimeoutTime_IDCM" SG_ 2654339223 GenericFailSts_FD11_APM2 0;
BA_ "GenSigTimeoutTime_VDCM" SG_ 2654339223 PreviousCanNMState_FD11_APM2 0;
BA_ "GenSigTimeoutTime_APM2" SG_ 2654339223 PreviousCanNMState_FD11_APM2 0;
BA_ "GenSigTimeoutTime_BPCM" SG_ 2654339223 PreviousCanNMState_FD11_APM2 0;
BA_ "GenSigTimeoutTime_IDCM" SG_ 2654339223 PreviousCanNMState_FD11_APM2 0;
BA_ "GenSigTimeoutTime_VDCM" SG_ 2654339223 CurrentCanNMState_FD11_APM2 0;
BA_ "GenSigTimeoutTime_APM2" SG_ 2654339223 CurrentCanNMState_FD11_APM2 0;
BA_ "GenSigTimeoutTime_BPCM" SG_ 2654339223 CurrentCanNMState_FD11_APM2 0;
BA_ "GenSigTimeoutTime_IDCM" SG_ 2654339223 CurrentCanNMState_FD11_APM2 0;
BA_ "GenSigTimeoutTime_VDCM" SG_ 2654339223 CurrentFailSts_FD11_APM2 0;
BA_ "GenSigTimeoutTime_APM2" SG_ 2654339223 CurrentFailSts_FD11_APM2 0;
BA_ "GenSigTimeoutTime_BPCM" SG_ 2654339223 CurrentFailSts_FD11_APM2 0;
BA_ "GenSigTimeoutTime_IDCM" SG_ 2654339223 CurrentFailSts_FD11_APM2 0;
BA_ "GenSigTimeoutTime_VDCM" SG_ 2654339223 DES_FD11_APM2 0;
BA_ "GenSigTimeoutTime_APM2" SG_ 2654339223 DES_FD11_APM2 0;
BA_ "GenSigTimeoutTime_BPCM" SG_ 2654339223 DES_FD11_APM2 0;
BA_ "GenSigTimeoutTime_IDCM" SG_ 2654339223 DES_FD11_APM2 0;
BA_ "GenSigTimeoutTime_VDCM" SG_ 2654339223 EOL_FD11_APM2 0;
BA_ "GenSigTimeoutTime_APM2" SG_ 2654339223 EOL_FD11_APM2 0;
BA_ "GenSigTimeoutTime_BPCM" SG_ 2654339223 EOL_FD11_APM2 0;
BA_ "GenSigTimeoutTime_IDCM" SG_ 2654339223 EOL_FD11_APM2 0;
BA_ "GenSigTimeoutTime_VDCM" SG_ 1845 HVBatSerialLength 0;
BA_ "GenSigTimeoutTime_APM2" SG_ 1845 HVBatSerialLength 0;
BA_ "GenSigTimeoutTime_BPCM" SG_ 1845 HVBatSerialLength 0;
BA_ "GenSigTimeoutTime_EVCU2" SG_ 1845 HVBatSerialLength 0;
BA_ "GenSigTimeoutTime_IDCM" SG_ 1845 HVBatSerialLength 0;
BA_ "GenSigTimeoutTime_VDCM" SG_ 1835 HVBatCellVoltage_Cell001 0;
BA_ "GenSigTimeoutTime_VDCM" SG_ 1835 HVBatCellVoltage_Cell002 0;
BA_ "GenSigTimeoutTime_VDCM" SG_ 1835 HVBatCellVoltage_Cell003 0;
BA_ "GenSigTimeoutTime_VDCM" SG_ 1835 HVBatCellVoltage_Cell004 0;
BA_ "GenSigTimeoutTime_VDCM" SG_ 1835 HVBatCellVoltage_Cell005 0;
BA_ "GenSigTimeoutTime_VDCM" SG_ 1835 HVBatCellVoltage_Cell006 0;
BA_ "GenSigTimeoutTime_VDCM" SG_ 1835 HVBatCellVoltage_Cell007 0;
BA_ "GenSigTimeoutTime_VDCM" SG_ 1835 HVBatCellVoltage_Cell008 0;
BA_ "GenSigTimeoutTime_VDCM" SG_ 1835 HVBatCellVoltage_Cell009 0;
BA_ "GenSigTimeoutTime_VDCM" SG_ 1835 HVBatCellVoltage_Cell010 0;
BA_ "GenSigTimeoutTime_VDCM" SG_ 1835 HVBatCellVoltage_Cell011 0;
BA_ "GenSigTimeoutTime_VDCM" SG_ 1835 HVBatCellVoltage_Cell027 0;
BA_ "GenSigTimeoutTime_VDCM" SG_ 1835 HVBatCellVoltage_Cell026 0;
BA_ "GenSigTimeoutTime_VDCM" SG_ 1835 HVBatCellVoltage_Cell024 0;
BA_ "GenSigTimeoutTime_VDCM" SG_ 1835 HVBatCellVoltage_Cell025 0;
BA_ "GenSigTimeoutTime_APM2" SG_ 1835 HVBatCellVoltage_Cell020 0;
BA_ "GenSigTimeoutTime_BPCM" SG_ 1835 HVBatCellVoltage_Cell020 0;
BA_ "GenSigTimeoutTime_EVCU2" SG_ 1835 HVBatCellVoltage_Cell020 0;
BA_ "GenSigTimeoutTime_IDCM" SG_ 1835 HVBatCellVoltage_Cell020 0;
BA_ "GenSigTimeoutTime_VDCM" SG_ 1835 HVBatCellVoltage_Cell020 0;
BA_ "GenSigTimeoutTime_VDCM" SG_ 1835 HVBatCellVoltage_Cell021 0;
BA_ "GenSigTimeoutTime_VDCM" SG_ 1835 HVBatCellVoltage_Cell022 0;
BA_ "GenSigTimeoutTime_VDCM" SG_ 1835 HVBatCellVoltage_Cell023 0;
BA_ "GenSigTimeoutTime_VDCM" SG_ 1835 HVBatCellVoltage_Cell012 0;
BA_ "GenSigTimeoutTime_VDCM" SG_ 1835 HVBatCellVoltage_Cell013 0;
BA_ "GenSigTimeoutTime_VDCM" SG_ 1835 HVBatCellVoltage_Cell014 0;
BA_ "GenSigTimeoutTime_VDCM" SG_ 1835 HVBatCellVoltage_Cell015 0;
BA_ "GenSigTimeoutTime_APM2" SG_ 1835 HVBatCellVoltage_Cell016 0;
BA_ "GenSigTimeoutTime_BPCM" SG_ 1835 HVBatCellVoltage_Cell016 0;
BA_ "GenSigTimeoutTime_EVCU2" SG_ 1835 HVBatCellVoltage_Cell016 0;
BA_ "GenSigTimeoutTime_IDCM" SG_ 1835 HVBatCellVoltage_Cell016 0;
BA_ "GenSigTimeoutTime_VDCM" SG_ 1835 HVBatCellVoltage_Cell016 0;
BA_ "GenSigTimeoutTime_APM2" SG_ 1835 HVBatCellVoltage_Cell017 0;
BA_ "GenSigTimeoutTime_BPCM" SG_ 1835 HVBatCellVoltage_Cell017 0;
BA_ "GenSigTimeoutTime_EVCU2" SG_ 1835 HVBatCellVoltage_Cell017 0;
BA_ "GenSigTimeoutTime_IDCM" SG_ 1835 HVBatCellVoltage_Cell017 0;
BA_ "GenSigTimeoutTime_VDCM" SG_ 1835 HVBatCellVoltage_Cell017 0;
BA_ "GenSigTimeoutTime_APM2" SG_ 1835 HVBatCellVoltage_Cell018 0;
BA_ "GenSigTimeoutTime_BPCM" SG_ 1835 HVBatCellVoltage_Cell018 0;
BA_ "GenSigTimeoutTime_EVCU2" SG_ 1835 HVBatCellVoltage_Cell018 0;
BA_ "GenSigTimeoutTime_IDCM" SG_ 1835 HVBatCellVoltage_Cell018 0;
BA_ "GenSigTimeoutTime_VDCM" SG_ 1835 HVBatCellVoltage_Cell018 0;
BA_ "GenSigTimeoutTime_APM2" SG_ 1835 HVBatCellVoltage_Cell019 0;
BA_ "GenSigTimeoutTime_BPCM" SG_ 1835 HVBatCellVoltage_Cell019 0;
BA_ "GenSigTimeoutTime_EVCU2" SG_ 1835 HVBatCellVoltage_Cell019 0;
BA_ "GenSigTimeoutTime_IDCM" SG_ 1835 HVBatCellVoltage_Cell019 0;
BA_ "GenSigTimeoutTime_VDCM" SG_ 1835 HVBatCellVoltage_Cell019 0;
BA_ "GenSigTimeoutTime_VDCM" SG_ 1845 HVBatSerialNumber 0;
BA_ "GenSigTimeoutTime_APM2" SG_ 1845 HVBatSerialNumber 0;
BA_ "GenSigTimeoutTime_BPCM" SG_ 1845 HVBatSerialNumber 0;
BA_ "GenSigTimeoutTime_EVCU2" SG_ 1845 HVBatSerialNumber 0;
BA_ "GenSigTimeoutTime_IDCM" SG_ 1845 HVBatSerialNumber 0;
BA_ "GenSigTimeoutTime_APM2" SG_ 1835 HVBatCellVoltage_Cell015 0;
BA_ "GenSigTimeoutTime_BPCM" SG_ 1835 HVBatCellVoltage_Cell015 0;
BA_ "GenSigTimeoutTime_EVCU2" SG_ 1835 HVBatCellVoltage_Cell015 0;
BA_ "GenSigTimeoutTime_IDCM" SG_ 1835 HVBatCellVoltage_Cell015 0;
BA_ "GenSigTimeoutTime_APM2" SG_ 1835 HVBatCellVoltage_Cell014 0;
BA_ "GenSigTimeoutTime_BPCM" SG_ 1835 HVBatCellVoltage_Cell014 0;
BA_ "GenSigTimeoutTime_EVCU2" SG_ 1835 HVBatCellVoltage_Cell014 0;
BA_ "GenSigTimeoutTime_IDCM" SG_ 1835 HVBatCellVoltage_Cell014 0;
BA_ "GenSigTimeoutTime_APM2" SG_ 1835 HVBatCellVoltage_Cell013 0;
BA_ "GenSigTimeoutTime_BPCM" SG_ 1835 HVBatCellVoltage_Cell013 0;
BA_ "GenSigTimeoutTime_EVCU2" SG_ 1835 HVBatCellVoltage_Cell013 0;
BA_ "GenSigTimeoutTime_IDCM" SG_ 1835 HVBatCellVoltage_Cell013 0;
BA_ "GenSigTimeoutTime_APM2" SG_ 1835 HVBatCellVoltage_Cell012 0;
BA_ "GenSigTimeoutTime_BPCM" SG_ 1835 HVBatCellVoltage_Cell012 0;
BA_ "GenSigTimeoutTime_EVCU2" SG_ 1835 HVBatCellVoltage_Cell012 0;
BA_ "GenSigTimeoutTime_IDCM" SG_ 1835 HVBatCellVoltage_Cell012 0;
BA_ "GenSigTimeoutTime_APM2" SG_ 1835 HVBatCellVoltage_Cell023 0;
BA_ "GenSigTimeoutTime_BPCM" SG_ 1835 HVBatCellVoltage_Cell023 0;
BA_ "GenSigTimeoutTime_EVCU2" SG_ 1835 HVBatCellVoltage_Cell023 0;
BA_ "GenSigTimeoutTime_IDCM" SG_ 1835 HVBatCellVoltage_Cell023 0;
BA_ "GenSigTimeoutTime_APM2" SG_ 1835 HVBatCellVoltage_Cell022 0;
BA_ "GenSigTimeoutTime_BPCM" SG_ 1835 HVBatCellVoltage_Cell022 0;
BA_ "GenSigTimeoutTime_EVCU2" SG_ 1835 HVBatCellVoltage_Cell022 0;
BA_ "GenSigTimeoutTime_IDCM" SG_ 1835 HVBatCellVoltage_Cell022 0;
BA_ "GenSigTimeoutTime_APM2" SG_ 1835 HVBatCellVoltage_Cell021 0;
BA_ "GenSigTimeoutTime_BPCM" SG_ 1835 HVBatCellVoltage_Cell021 0;
BA_ "GenSigTimeoutTime_EVCU2" SG_ 1835 HVBatCellVoltage_Cell021 0;
BA_ "GenSigTimeoutTime_IDCM" SG_ 1835 HVBatCellVoltage_Cell021 0;
BA_ "GenSigTimeoutTime_APM2" SG_ 1835 HVBatCellVoltage_Cell025 0;
BA_ "GenSigTimeoutTime_BPCM" SG_ 1835 HVBatCellVoltage_Cell025 0;
BA_ "GenSigTimeoutTime_EVCU2" SG_ 1835 HVBatCellVoltage_Cell025 0;
BA_ "GenSigTimeoutTime_IDCM" SG_ 1835 HVBatCellVoltage_Cell025 0;
BA_ "GenSigTimeoutTime_APM2" SG_ 1835 HVBatCellVoltage_Cell024 0;
BA_ "GenSigTimeoutTime_BPCM" SG_ 1835 HVBatCellVoltage_Cell024 0;
BA_ "GenSigTimeoutTime_EVCU2" SG_ 1835 HVBatCellVoltage_Cell024 0;
BA_ "GenSigTimeoutTime_IDCM" SG_ 1835 HVBatCellVoltage_Cell024 0;
BA_ "GenSigTimeoutTime_APM2" SG_ 1835 HVBatCellVoltage_Cell026 0;
BA_ "GenSigTimeoutTime_BPCM" SG_ 1835 HVBatCellVoltage_Cell026 0;
BA_ "GenSigTimeoutTime_EVCU2" SG_ 1835 HVBatCellVoltage_Cell026 0;
BA_ "GenSigTimeoutTime_IDCM" SG_ 1835 HVBatCellVoltage_Cell026 0;
BA_ "GenSigTimeoutTime_APM2" SG_ 1835 HVBatCellVoltage_Cell027 0;
BA_ "GenSigTimeoutTime_BPCM" SG_ 1835 HVBatCellVoltage_Cell027 0;
BA_ "GenSigTimeoutTime_EVCU2" SG_ 1835 HVBatCellVoltage_Cell027 0;
BA_ "GenSigTimeoutTime_IDCM" SG_ 1835 HVBatCellVoltage_Cell027 0;
BA_ "GenSigTimeoutTime_APM2" SG_ 1835 HVBatCellVoltage_Cell011 0;
BA_ "GenSigTimeoutTime_BPCM" SG_ 1835 HVBatCellVoltage_Cell011 0;
BA_ "GenSigTimeoutTime_EVCU2" SG_ 1835 HVBatCellVoltage_Cell011 0;
BA_ "GenSigTimeoutTime_IDCM" SG_ 1835 HVBatCellVoltage_Cell011 0;
BA_ "GenSigTimeoutTime_APM2" SG_ 1835 HVBatCellVoltage_Cell010 0;
BA_ "GenSigTimeoutTime_BPCM" SG_ 1835 HVBatCellVoltage_Cell010 0;
BA_ "GenSigTimeoutTime_EVCU2" SG_ 1835 HVBatCellVoltage_Cell010 0;
BA_ "GenSigTimeoutTime_IDCM" SG_ 1835 HVBatCellVoltage_Cell010 0;
BA_ "GenSigTimeoutTime_APM2" SG_ 1835 HVBatCellVoltage_Cell009 0;
BA_ "GenSigTimeoutTime_BPCM" SG_ 1835 HVBatCellVoltage_Cell009 0;
BA_ "GenSigTimeoutTime_EVCU2" SG_ 1835 HVBatCellVoltage_Cell009 0;
BA_ "GenSigTimeoutTime_IDCM" SG_ 1835 HVBatCellVoltage_Cell009 0;
BA_ "GenSigTimeoutTime_APM2" SG_ 1835 HVBatCellVoltage_Cell008 0;
BA_ "GenSigTimeoutTime_BPCM" SG_ 1835 HVBatCellVoltage_Cell008 0;
BA_ "GenSigTimeoutTime_EVCU2" SG_ 1835 HVBatCellVoltage_Cell008 0;
BA_ "GenSigTimeoutTime_IDCM" SG_ 1835 HVBatCellVoltage_Cell008 0;
BA_ "GenSigTimeoutTime_APM2" SG_ 1835 HVBatCellVoltage_Cell007 0;
BA_ "GenSigTimeoutTime_BPCM" SG_ 1835 HVBatCellVoltage_Cell007 0;
BA_ "GenSigTimeoutTime_EVCU2" SG_ 1835 HVBatCellVoltage_Cell007 0;
BA_ "GenSigTimeoutTime_IDCM" SG_ 1835 HVBatCellVoltage_Cell007 0;
BA_ "GenSigTimeoutTime_APM2" SG_ 1835 HVBatCellVoltage_Cell006 0;
BA_ "GenSigTimeoutTime_BPCM" SG_ 1835 HVBatCellVoltage_Cell006 0;
BA_ "GenSigTimeoutTime_EVCU2" SG_ 1835 HVBatCellVoltage_Cell006 0;
BA_ "GenSigTimeoutTime_IDCM" SG_ 1835 HVBatCellVoltage_Cell006 0;
BA_ "GenSigTimeoutTime_APM2" SG_ 1835 HVBatCellVoltage_Cell005 0;
BA_ "GenSigTimeoutTime_BPCM" SG_ 1835 HVBatCellVoltage_Cell005 0;
BA_ "GenSigTimeoutTime_EVCU2" SG_ 1835 HVBatCellVoltage_Cell005 0;
BA_ "GenSigTimeoutTime_IDCM" SG_ 1835 HVBatCellVoltage_Cell005 0;
BA_ "GenSigTimeoutTime_APM2" SG_ 1835 HVBatCellVoltage_Cell004 0;
BA_ "GenSigTimeoutTime_BPCM" SG_ 1835 HVBatCellVoltage_Cell004 0;
BA_ "GenSigTimeoutTime_EVCU2" SG_ 1835 HVBatCellVoltage_Cell004 0;
BA_ "GenSigTimeoutTime_IDCM" SG_ 1835 HVBatCellVoltage_Cell004 0;
BA_ "GenSigTimeoutTime_APM2" SG_ 1835 HVBatCellVoltage_Cell003 0;
BA_ "GenSigTimeoutTime_BPCM" SG_ 1835 HVBatCellVoltage_Cell003 0;
BA_ "GenSigTimeoutTime_EVCU2" SG_ 1835 HVBatCellVoltage_Cell003 0;
BA_ "GenSigTimeoutTime_IDCM" SG_ 1835 HVBatCellVoltage_Cell003 0;
BA_ "GenSigTimeoutTime_APM2" SG_ 1835 HVBatCellVoltage_Cell002 0;
BA_ "GenSigTimeoutTime_BPCM" SG_ 1835 HVBatCellVoltage_Cell002 0;
BA_ "GenSigTimeoutTime_EVCU2" SG_ 1835 HVBatCellVoltage_Cell002 0;
BA_ "GenSigTimeoutTime_IDCM" SG_ 1835 HVBatCellVoltage_Cell002 0;
BA_ "GenSigTimeoutTime_APM2" SG_ 1835 HVBatCellVoltage_Cell001 0;
BA_ "GenSigTimeoutTime_BPCM" SG_ 1835 HVBatCellVoltage_Cell001 0;
BA_ "GenSigTimeoutTime_EVCU2" SG_ 1835 HVBatCellVoltage_Cell001 0;
BA_ "GenSigTimeoutTime_IDCM" SG_ 1835 HVBatCellVoltage_Cell001 0;
BA_ "GenSigTimeoutTime_HCP" SG_ 1460 FOTA_Status 0;
BA_ "GenSigTimeoutTime_PPIM" SG_ 1460 FOTA_Status 0;
BA_ "GenSigTimeoutTime_APM2" SG_ 1460 FOTA_Status 0;
BA_ "GenSigTimeoutTime_VDCM" SG_ 1460 FOTA_Status 0;
BA_ "GenSigTimeoutTime_BPCM" SG_ 1460 FOTA_Status 0;
BA_ "GenSigSendType" SG_ 1460 FOTA_Status 3;
BA_ "GenSigTimeoutTime_SGW" SG_ 1460 FOTA_Status 0;
BA_ "GenSigTimeoutTime_PPIM" SG_ 2651930694 Digit_01_BPCM 0;
BA_ "GenSigTimeoutTime_APM2" SG_ 2651930694 Digit_01_BPCM 0;
BA_ "GenSigTimeoutTime_VDCM" SG_ 2651930694 Digit_01_BPCM 0;
BA_ "GenSigSendType" SG_ 2651930694 Digit_01_BPCM 1;
BA_ "GenSigTimeoutTime_BPCM" SG_ 2651930694 Digit_01_BPCM 0;
BA_ "GenSigTimeoutTime_IDCM" SG_ 2651930694 Digit_01_BPCM 0;
BA_ "GenSigTimeoutTime_SGW" SG_ 2651930694 Digit_01_BPCM 0;
BA_ "GenSigTimeoutTime_PPIM" SG_ 2651930694 Digit_02_BPCM 0;
BA_ "GenSigTimeoutTime_APM2" SG_ 2651930694 Digit_02_BPCM 0;
BA_ "GenSigTimeoutTime_VDCM" SG_ 2651930694 Digit_02_BPCM 0;
BA_ "GenSigTimeoutTime_BPCM" SG_ 2651930694 Digit_02_BPCM 0;
BA_ "GenSigTimeoutTime_IDCM" SG_ 2651930694 Digit_02_BPCM 0;
BA_ "GenSigTimeoutTime_SGW" SG_ 2651930694 Digit_02_BPCM 0;
BA_ "GenSigTimeoutTime_PPIM" SG_ 2651930694 Digit_03_BPCM 0;
BA_ "GenSigTimeoutTime_APM2" SG_ 2651930694 Digit_03_BPCM 0;
BA_ "GenSigTimeoutTime_VDCM" SG_ 2651930694 Digit_03_BPCM 0;
BA_ "GenSigTimeoutTime_BPCM" SG_ 2651930694 Digit_03_BPCM 0;
BA_ "GenSigTimeoutTime_IDCM" SG_ 2651930694 Digit_03_BPCM 0;
BA_ "GenSigTimeoutTime_SGW" SG_ 2651930694 Digit_03_BPCM 0;
BA_ "GenSigTimeoutTime_PPIM" SG_ 2651930694 Digit_04_BPCM 0;
BA_ "GenSigTimeoutTime_APM2" SG_ 2651930694 Digit_04_BPCM 0;
BA_ "GenSigTimeoutTime_VDCM" SG_ 2651930694 Digit_04_BPCM 0;
BA_ "GenSigTimeoutTime_BPCM" SG_ 2651930694 Digit_04_BPCM 0;
BA_ "GenSigTimeoutTime_IDCM" SG_ 2651930694 Digit_04_BPCM 0;
BA_ "GenSigTimeoutTime_SGW" SG_ 2651930694 Digit_04_BPCM 0;
BA_ "GenSigTimeoutTime_PPIM" SG_ 2651930694 Digit_05_BPCM 0;
BA_ "GenSigTimeoutTime_APM2" SG_ 2651930694 Digit_05_BPCM 0;
BA_ "GenSigTimeoutTime_VDCM" SG_ 2651930694 Digit_05_BPCM 0;
BA_ "GenSigTimeoutTime_BPCM" SG_ 2651930694 Digit_05_BPCM 0;
BA_ "GenSigTimeoutTime_IDCM" SG_ 2651930694 Digit_05_BPCM 0;
BA_ "GenSigTimeoutTime_SGW" SG_ 2651930694 Digit_05_BPCM 0;
BA_ "GenSigTimeoutTime_PPIM" SG_ 2651930694 Digit_06_BPCM 0;
BA_ "GenSigTimeoutTime_APM2" SG_ 2651930694 Digit_06_BPCM 0;
BA_ "GenSigTimeoutTime_VDCM" SG_ 2651930694 Digit_06_BPCM 0;
BA_ "GenSigTimeoutTime_BPCM" SG_ 2651930694 Digit_06_BPCM 0;
BA_ "GenSigTimeoutTime_IDCM" SG_ 2651930694 Digit_06_BPCM 0;
BA_ "GenSigTimeoutTime_SGW" SG_ 2651930694 Digit_06_BPCM 0;
BA_ "GenSigTimeoutTime_PPIM" SG_ 2651930694 Digit_07_BPCM 0;
BA_ "GenSigTimeoutTime_APM2" SG_ 2651930694 Digit_07_BPCM 0;
BA_ "GenSigTimeoutTime_VDCM" SG_ 2651930694 Digit_07_BPCM 0;
BA_ "GenSigTimeoutTime_BPCM" SG_ 2651930694 Digit_07_BPCM 0;
BA_ "GenSigTimeoutTime_IDCM" SG_ 2651930694 Digit_07_BPCM 0;
BA_ "GenSigTimeoutTime_SGW" SG_ 2651930694 Digit_07_BPCM 0;
BA_ "GenSigTimeoutTime_PPIM" SG_ 2651930694 Digit_08_BPCM 0;
BA_ "GenSigTimeoutTime_APM2" SG_ 2651930694 Digit_08_BPCM 0;
BA_ "GenSigTimeoutTime_VDCM" SG_ 2651930694 Digit_08_BPCM 0;
BA_ "GenSigTimeoutTime_BPCM" SG_ 2651930694 Digit_08_BPCM 0;
BA_ "GenSigTimeoutTime_IDCM" SG_ 2651930694 Digit_08_BPCM 0;
BA_ "GenSigTimeoutTime_SGW" SG_ 2651930694 Digit_08_BPCM 0;
BA_ "GenSigTimeoutTime_PPIM" SG_ 2651930694 Digit_09_BPCM 0;
BA_ "GenSigTimeoutTime_APM2" SG_ 2651930694 Digit_09_BPCM 0;
BA_ "GenSigTimeoutTime_VDCM" SG_ 2651930694 Digit_09_BPCM 0;
BA_ "GenSigTimeoutTime_BPCM" SG_ 2651930694 Digit_09_BPCM 0;
BA_ "GenSigTimeoutTime_IDCM" SG_ 2651930694 Digit_09_BPCM 0;
BA_ "GenSigTimeoutTime_SGW" SG_ 2651930694 Digit_09_BPCM 0;
BA_ "GenSigTimeoutTime_PPIM" SG_ 2651930694 Digit_10_BPCM 0;
BA_ "GenSigTimeoutTime_APM2" SG_ 2651930694 Digit_10_BPCM 0;
BA_ "GenSigTimeoutTime_VDCM" SG_ 2651930694 Digit_10_BPCM 0;
BA_ "GenSigTimeoutTime_BPCM" SG_ 2651930694 Digit_10_BPCM 0;
BA_ "GenSigTimeoutTime_IDCM" SG_ 2651930694 Digit_10_BPCM 0;
BA_ "GenSigTimeoutTime_SGW" SG_ 2651930694 Digit_10_BPCM 0;
BA_ "GenSigTimeoutTime_PPIM" SG_ 2651930694 Digit_11_BPCM 0;
BA_ "GenSigTimeoutTime_APM2" SG_ 2651930694 Digit_11_BPCM 0;
BA_ "GenSigTimeoutTime_VDCM" SG_ 2651930694 Digit_11_BPCM 0;
BA_ "GenSigTimeoutTime_BPCM" SG_ 2651930694 Digit_11_BPCM 0;
BA_ "GenSigTimeoutTime_IDCM" SG_ 2651930694 Digit_11_BPCM 0;
BA_ "GenSigTimeoutTime_SGW" SG_ 2651930694 Digit_11_BPCM 0;
BA_ "GenSigSendType" SG_ 2651930749 Digit_01_IDCM 1;
BA_ "GenSigTimeoutTime_BPCM" SG_ 2651930749 Digit_01_IDCM 0;
BA_ "GenSigTimeoutTime_IDCM" SG_ 2651930749 Digit_01_IDCM 0;
BA_ "GenSigTimeoutTime_SGW" SG_ 2651930749 Digit_01_IDCM 0;
BA_ "GenSigTimeoutTime_HCP" SG_ 2651930749 Digit_01_IDCM 0;
BA_ "GenSigTimeoutTime_PPIM" SG_ 2651930749 Digit_01_IDCM 0;
BA_ "GenSigTimeoutTime_APM2" SG_ 2651930749 Digit_01_IDCM 0;
BA_ "GenSigTimeoutTime_VDCM" SG_ 2651930749 Digit_01_IDCM 0;
BA_ "GenSigTimeoutTime_BPCM" SG_ 2651930749 Digit_02_IDCM 0;
BA_ "GenSigTimeoutTime_IDCM" SG_ 2651930749 Digit_02_IDCM 0;
BA_ "GenSigTimeoutTime_SGW" SG_ 2651930749 Digit_02_IDCM 0;
BA_ "GenSigTimeoutTime_HCP" SG_ 2651930749 Digit_02_IDCM 0;
BA_ "GenSigTimeoutTime_PPIM" SG_ 2651930749 Digit_02_IDCM 0;
BA_ "GenSigTimeoutTime_APM2" SG_ 2651930749 Digit_02_IDCM 0;
BA_ "GenSigTimeoutTime_VDCM" SG_ 2651930749 Digit_02_IDCM 0;
BA_ "GenSigTimeoutTime_BPCM" SG_ 2651930749 Digit_03_IDCM 0;
BA_ "GenSigTimeoutTime_IDCM" SG_ 2651930749 Digit_03_IDCM 0;
BA_ "GenSigTimeoutTime_SGW" SG_ 2651930749 Digit_03_IDCM 0;
BA_ "GenSigTimeoutTime_HCP" SG_ 2651930749 Digit_03_IDCM 0;
BA_ "GenSigTimeoutTime_PPIM" SG_ 2651930749 Digit_03_IDCM 0;
BA_ "GenSigTimeoutTime_APM2" SG_ 2651930749 Digit_03_IDCM 0;
BA_ "GenSigTimeoutTime_VDCM" SG_ 2651930749 Digit_03_IDCM 0;
BA_ "GenSigTimeoutTime_BPCM" SG_ 2651930749 Digit_04_IDCM 0;
BA_ "GenSigTimeoutTime_IDCM" SG_ 2651930749 Digit_04_IDCM 0;
BA_ "GenSigTimeoutTime_SGW" SG_ 2651930749 Digit_04_IDCM 0;
BA_ "GenSigTimeoutTime_HCP" SG_ 2651930749 Digit_04_IDCM 0;
BA_ "GenSigTimeoutTime_PPIM" SG_ 2651930749 Digit_04_IDCM 0;
BA_ "GenSigTimeoutTime_APM2" SG_ 2651930749 Digit_04_IDCM 0;
BA_ "GenSigTimeoutTime_VDCM" SG_ 2651930749 Digit_04_IDCM 0;
BA_ "GenSigTimeoutTime_BPCM" SG_ 2651930749 Digit_05_IDCM 0;
BA_ "GenSigTimeoutTime_IDCM" SG_ 2651930749 Digit_05_IDCM 0;
BA_ "GenSigTimeoutTime_SGW" SG_ 2651930749 Digit_05_IDCM 0;
BA_ "GenSigTimeoutTime_HCP" SG_ 2651930749 Digit_05_IDCM 0;
BA_ "GenSigTimeoutTime_PPIM" SG_ 2651930749 Digit_05_IDCM 0;
BA_ "GenSigTimeoutTime_APM2" SG_ 2651930749 Digit_05_IDCM 0;
BA_ "GenSigTimeoutTime_VDCM" SG_ 2651930749 Digit_05_IDCM 0;
BA_ "GenSigTimeoutTime_BPCM" SG_ 2651930749 Digit_06_IDCM 0;
BA_ "GenSigTimeoutTime_HCP" SG_ 2651930749 Digit_06_IDCM 0;
BA_ "GenSigTimeoutTime_PPIM" SG_ 2651930749 Digit_06_IDCM 0;
BA_ "GenSigTimeoutTime_APM2" SG_ 2651930749 Digit_06_IDCM 0;
BA_ "GenSigTimeoutTime_VDCM" SG_ 2651930749 Digit_06_IDCM 0;
BA_ "GenSigTimeoutTime_HCP" SG_ 2651930749 Digit_07_IDCM 0;
BA_ "GenSigTimeoutTime_PPIM" SG_ 2651930749 Digit_07_IDCM 0;
BA_ "GenSigTimeoutTime_APM2" SG_ 2651930749 Digit_07_IDCM 0;
BA_ "GenSigTimeoutTime_VDCM" SG_ 2651930749 Digit_07_IDCM 0;
BA_ "GenSigTimeoutTime_HCP" SG_ 2651930749 Digit_08_IDCM 0;
BA_ "GenSigTimeoutTime_PPIM" SG_ 2651930749 Digit_08_IDCM 0;
BA_ "GenSigTimeoutTime_APM2" SG_ 2651930749 Digit_08_IDCM 0;
BA_ "GenSigTimeoutTime_VDCM" SG_ 2651930749 Digit_08_IDCM 0;
BA_ "GenSigTimeoutTime_HCP" SG_ 2651930749 Digit_09_IDCM 0;
BA_ "GenSigTimeoutTime_PPIM" SG_ 2651930749 Digit_09_IDCM 0;
BA_ "GenSigTimeoutTime_APM2" SG_ 2651930749 Digit_09_IDCM 0;
BA_ "GenSigTimeoutTime_VDCM" SG_ 2651930749 Digit_09_IDCM 0;
BA_ "GenSigTimeoutTime_APM2" SG_ 2651930749 Digit_10_IDCM 0;
BA_ "GenSigTimeoutTime_VDCM" SG_ 2651930749 Digit_10_IDCM 0;
BA_ "GenSigTimeoutTime_HCP" SG_ 2651930749 Digit_10_IDCM 0;
BA_ "GenSigTimeoutTime_PPIM" SG_ 2651930749 Digit_10_IDCM 0;
BA_ "GenSigTimeoutTime_HCP" SG_ 2651930749 Digit_11_IDCM 0;
BA_ "GenSigTimeoutTime_PPIM" SG_ 2651930749 Digit_11_IDCM 0;
BA_ "GenSigTimeoutTime_APM2" SG_ 2651930749 Digit_11_IDCM 0;
BA_ "GenSigTimeoutTime_VDCM" SG_ 2651930749 Digit_11_IDCM 0;
BA_ "GenSigTimeoutTime_HCP" SG_ 1578 ChrgFailSts 0;
BA_ "GenSigTimeoutTime_PPIM" SG_ 1578 ChrgFailSts 0;
BA_ "GenSigTimeoutTime_APM2" SG_ 1578 ChrgFailSts 0;
BA_ "GenSigTimeoutTime_VDCM" SG_ 1578 ChrgFailSts 0;
BA_ "GenSigTimeoutTime_BPCM" SG_ 1578 ChrgFailSts 0;
BA_ "GenSigTimeoutTime_IDCM" SG_ 1578 ChrgFailSts 0;
BA_ "GenSigTimeoutTime_SGW" SG_ 1578 ChrgFailSts 0;
BA_ "GenSigTimeoutTime_HCP" SG_ 1578 OBCM_PrechargeSts 0;
BA_ "GenSigTimeoutTime_PPIM" SG_ 1578 OBCM_PrechargeSts 0;
BA_ "GenSigTimeoutTime_APM2" SG_ 1578 OBCM_PrechargeSts 0;
BA_ "GenSigTimeoutTime_VDCM" SG_ 1578 OBCM_PrechargeSts 0;
BA_ "GenSigTimeoutTime_HCP" SG_ 1578 OBC_Pilot 0;
BA_ "GenSigTimeoutTime_PPIM" SG_ 1578 OBC_Pilot 0;
BA_ "GenSigTimeoutTime_APM2" SG_ 1578 OBC_Pilot 0;
BA_ "GenSigTimeoutTime_VDCM" SG_ 1578 OBC_Pilot 0;
BA_ "GenSigTimeoutTime_HCP" SG_ 1578 OBC_Prox 0;
BA_ "GenSigTimeoutTime_PPIM" SG_ 1578 OBC_Prox 0;
BA_ "GenSigTimeoutTime_APM2" SG_ 1578 OBC_Prox 0;
BA_ "GenSigTimeoutTime_VDCM" SG_ 1578 OBC_Prox 0;
BA_ "GenSigTimeoutTime_BPCM" SG_ 1578 OBC_WakeReason 0;
BA_ "GenSigTimeoutTime_IDCM" SG_ 1578 OBC_WakeReason 0;
BA_ "GenSigTimeoutTime_SGW" SG_ 1578 OBC_WakeReason 0;
BA_ "GenSigTimeoutTime_HCP" SG_ 1578 OBC_WakeReason 0;
BA_ "GenSigTimeoutTime_PPIM" SG_ 1578 OBC_WakeReason 0;
BA_ "GenSigTimeoutTime_APM2" SG_ 1578 OBC_WakeReason 0;
BA_ "GenSigTimeoutTime_VDCM" SG_ 1578 OBC_WakeReason 0;
BA_ "GenSigSendType" SG_ 1578 OnboardChargerMode 4;
BA_ "GenSigTimeoutTime_BPCM" SG_ 1578 OnboardChargerMode 0;
BA_ "GenSigTimeoutTime_IDCM" SG_ 1578 OnboardChargerMode 0;
BA_ "GenSigTimeoutTime_SGW" SG_ 1578 OnboardChargerMode 0;
BA_ "GenSigTimeoutTime_HCP" SG_ 1578 OnboardChargerMode 0;
BA_ "GenSigTimeoutTime_PPIM" SG_ 1578 OnboardChargerMode 0;
BA_ "GenSigTimeoutTime_APM2" SG_ 1578 OnboardChargerMode 0;
BA_ "GenSigTimeoutTime_VDCM" SG_ 1578 OnboardChargerMode 0;
BA_ "GenSigStartValue" SG_ 1578 OnboardChargerReady 1;
BA_ "GenSigTimeoutTime_BPCM" SG_ 1578 OnboardChargerReady 0;
BA_ "GenSigTimeoutTime_IDCM" SG_ 1578 OnboardChargerReady 0;
BA_ "GenSigTimeoutTime_SGW" SG_ 1578 OnboardChargerReady 0;
BA_ "GenSigTimeoutTime_HCP" SG_ 1578 OnboardChargerReady 0;
BA_ "GenSigTimeoutTime_PPIM" SG_ 1578 OnboardChargerReady 0;
BA_ "GenSigTimeoutTime_APM2" SG_ 1578 OnboardChargerReady 0;
BA_ "GenSigTimeoutTime_VDCM" SG_ 1578 OnboardChargerReady 0;
BA_ "GenSigTimeoutTime_HCP" SG_ 1578 OBC_CaptureEnvironmentData 0;
BA_ "GenSigTimeoutTime_PPIM" SG_ 1578 OBC_CaptureEnvironmentData 0;
BA_ "GenSigTimeoutTime_APM2" SG_ 1578 OBC_CaptureEnvironmentData 0;
BA_ "GenSigTimeoutTime_VDCM" SG_ 1578 OBC_CaptureEnvironmentData 0;
BA_ "GenSigTimeoutTime_HCP" SG_ 1578 OBC_ChargeFailure 0;
BA_ "GenSigTimeoutTime_PPIM" SG_ 1578 OBC_ChargeFailure 0;
BA_ "GenSigTimeoutTime_APM2" SG_ 1578 OBC_ChargeFailure 0;
BA_ "GenSigTimeoutTime_VDCM" SG_ 1578 OBC_ChargeFailure 0;
BA_ "GenSigTimeoutTime_HCP" SG_ 1578 OBC_ChargingFaultSts 0;
BA_ "GenSigTimeoutTime_PPIM" SG_ 1578 OBC_ChargingFaultSts 0;
BA_ "GenSigTimeoutTime_APM2" SG_ 1578 OBC_ChargingFaultSts 0;
BA_ "GenSigTimeoutTime_VDCM" SG_ 1578 OBC_ChargingFaultSts 0;
BA_ "GenSigTimeoutTime_HCP" SG_ 1578 OBC_CurrentFailureSts 0;
BA_ "GenSigTimeoutTime_PPIM" SG_ 1578 OBC_CurrentFailureSts 0;
BA_ "GenSigTimeoutTime_APM2" SG_ 1578 OBC_CurrentFailureSts 0;
BA_ "GenSigTimeoutTime_VDCM" SG_ 1578 OBC_CurrentFailureSts 0;
BA_ "GenSigTimeoutTime_HCP" SG_ 1578 OBC_EVServiceLampFlash 0;
BA_ "GenSigTimeoutTime_PPIM" SG_ 1578 OBC_EVServiceLampFlash 0;
BA_ "GenSigTimeoutTime_APM2" SG_ 1578 OBC_EVServiceLampFlash 0;
BA_ "GenSigTimeoutTime_VDCM" SG_ 1578 OBC_EVServiceLampFlash 0;
BA_ "GenSigTimeoutTime_BPCM" SG_ 1578 OBC_EVServiceLampOn 0;
BA_ "GenSigTimeoutTime_EVCU2" SG_ 1578 OBC_EVServiceLampOn 0;
BA_ "GenSigTimeoutTime_IDCM" SG_ 1578 OBC_EVServiceLampOn 0;
BA_ "GenSigTimeoutTime_SGW" SG_ 1578 OBC_EVServiceLampOn 0;
BA_ "GenSigTimeoutTime_HCP" SG_ 1578 OBC_EVServiceLampOn 0;
BA_ "GenSigTimeoutTime_PPIM" SG_ 1578 OBC_EVServiceLampOn 0;
BA_ "GenSigTimeoutTime_APM2" SG_ 1578 OBC_EVServiceLampOn 0;
BA_ "GenSigTimeoutTime_VDCM" SG_ 1578 OBC_EVServiceLampOn 0;
BA_ "GenSigTimeoutTime_BPCM" SG_ 1578 OBC_FaultReason 0;
BA_ "GenSigTimeoutTime_IDCM" SG_ 1578 OBC_FaultReason 0;
BA_ "GenSigTimeoutTime_SGW" SG_ 1578 OBC_FaultReason 0;
BA_ "GenSigTimeoutTime_HCP" SG_ 1578 OBC_FaultReason 0;
BA_ "GenSigTimeoutTime_PPIM" SG_ 1578 OBC_FaultReason 0;
BA_ "GenSigTimeoutTime_APM2" SG_ 1578 OBC_FaultReason 0;
BA_ "GenSigTimeoutTime_VDCM" SG_ 1578 OBC_FaultReason 0;
BA_ "GenSigTimeoutTime_BPCM" SG_ 1578 OBC_GenericFailSts 0;
BA_ "GenSigTimeoutTime_EVCU2" SG_ 1578 OBC_GenericFailSts 0;
BA_ "GenSigTimeoutTime_IDCM" SG_ 1578 OBC_GenericFailSts 0;
BA_ "GenSigTimeoutTime_SGW" SG_ 1578 OBC_GenericFailSts 0;
BA_ "GenSigTimeoutTime_HCP" SG_ 1578 OBC_GenericFailSts 0;
BA_ "GenSigTimeoutTime_PPIM" SG_ 1578 OBC_GenericFailSts 0;
BA_ "GenSigTimeoutTime_APM2" SG_ 1578 OBC_GenericFailSts 0;
BA_ "GenSigTimeoutTime_VDCM" SG_ 1578 OBC_GenericFailSts 0;
BA_ "GenSigTimeoutTime_BPCM" SG_ 1578 ACplug_PwrMax 0;
BA_ "GenSigTimeoutTime_HCP" SG_ 1578 ACplug_PwrMax 0;
BA_ "GenSigTimeoutTime_PPIM" SG_ 1578 ACplug_PwrMax 0;
BA_ "GenSigTimeoutTime_APM2" SG_ 1578 ACplug_PwrMax 0;
BA_ "GenSigTimeoutTime_VDCM" SG_ 1578 ACplug_PwrMax 0;
BA_ "GenSigTimeoutTime_BPCM" SG_ 2651930749 Digit_11_IDCM 0;
BA_ "GenSigTimeoutTime_IDCM" SG_ 2651930749 Digit_11_IDCM 0;
BA_ "GenSigTimeoutTime_SGW" SG_ 2651930749 Digit_11_IDCM 0;
BA_ "GenSigTimeoutTime_BPCM" SG_ 2651930749 Digit_10_IDCM 0;
BA_ "GenSigTimeoutTime_IDCM" SG_ 2651930749 Digit_10_IDCM 0;
BA_ "GenSigTimeoutTime_SGW" SG_ 2651930749 Digit_10_IDCM 0;
BA_ "GenSigTimeoutTime_BPCM" SG_ 2651930749 Digit_09_IDCM 0;
BA_ "GenSigTimeoutTime_IDCM" SG_ 2651930749 Digit_09_IDCM 0;
BA_ "GenSigTimeoutTime_SGW" SG_ 2651930749 Digit_09_IDCM 0;
BA_ "GenSigTimeoutTime_BPCM" SG_ 2651930749 Digit_08_IDCM 0;
BA_ "GenSigTimeoutTime_IDCM" SG_ 2651930749 Digit_08_IDCM 0;
BA_ "GenSigTimeoutTime_SGW" SG_ 2651930749 Digit_08_IDCM 0;
BA_ "GenSigTimeoutTime_HCP" SG_ 1372 OBC_Temp1 0;
BA_ "GenSigTimeoutTime_PPIM" SG_ 1372 OBC_Temp1 0;
BA_ "GenSigTimeoutTime_APM2" SG_ 1372 OBC_Temp1 0;
BA_ "GenSigTimeoutTime_VDCM" SG_ 1372 OBC_Temp1 0;
BA_ "GenSigTimeoutTime_BPCM" SG_ 1372 OBC_Temp1 0;
BA_ "GenSigTimeoutTime_IDCM" SG_ 1372 OBC_Temp1 0;
BA_ "GenSigTimeoutTime_SGW" SG_ 1372 OBC_Temp1 0;
BA_ "GenSigTimeoutTime_HCP" SG_ 1372 OBC_Temp2 0;
BA_ "GenSigTimeoutTime_PPIM" SG_ 1372 OBC_Temp2 0;
BA_ "GenSigTimeoutTime_APM2" SG_ 1372 OBC_Temp2 0;
BA_ "GenSigTimeoutTime_VDCM" SG_ 1372 OBC_Temp2 0;
BA_ "GenSigTimeoutTime_BPCM" SG_ 1372 OBC_Temp2 0;
BA_ "GenSigTimeoutTime_IDCM" SG_ 1372 OBC_Temp2 0;
BA_ "GenSigTimeoutTime_SGW" SG_ 1372 OBC_Temp2 0;
BA_ "GenSigTimeoutTime_HCP" SG_ 1372 OBC_Temp3 0;
BA_ "GenSigTimeoutTime_PPIM" SG_ 1372 OBC_Temp3 0;
BA_ "GenSigTimeoutTime_APM2" SG_ 1372 OBC_Temp3 0;
BA_ "GenSigTimeoutTime_VDCM" SG_ 1372 OBC_Temp3 0;
BA_ "GenSigTimeoutTime_BPCM" SG_ 1372 OBC_Temp3 0;
BA_ "GenSigTimeoutTime_IDCM" SG_ 1372 OBC_Temp3 0;
BA_ "GenSigTimeoutTime_SGW" SG_ 1372 OBC_Temp3 0;
BA_ "GenSigTimeoutTime_HCP" SG_ 1372 OBC_Temp4 0;
BA_ "GenSigTimeoutTime_PPIM" SG_ 1372 OBC_Temp4 0;
BA_ "GenSigTimeoutTime_APM2" SG_ 1372 OBC_Temp4 0;
BA_ "GenSigTimeoutTime_VDCM" SG_ 1372 OBC_Temp4 0;
BA_ "GenSigTimeoutTime_BPCM" SG_ 1372 OBC_Temp4 0;
BA_ "GenSigTimeoutTime_IDCM" SG_ 1372 OBC_Temp4 0;
BA_ "GenSigTimeoutTime_SGW" SG_ 1372 OBC_Temp4 0;
BA_ "GenSigTimeoutTime_BPCM" SG_ 2651930749 Digit_07_IDCM 0;
BA_ "GenSigTimeoutTime_IDCM" SG_ 2651930749 Digit_07_IDCM 0;
BA_ "GenSigTimeoutTime_SGW" SG_ 2651930749 Digit_07_IDCM 0;
BA_ "GenSigTimeoutTime_IDCM" SG_ 2651930749 Digit_06_IDCM 0;
BA_ "GenSigTimeoutTime_SGW" SG_ 2651930749 Digit_06_IDCM 0;
BA_ "GenSigTimeoutTime_HCP" SG_ 2564682064 N_PDU_18DDF150 0;
BA_ "GenSigTimeoutTime_PPIM" SG_ 2564682064 N_PDU_18DDF150 0;
BA_ "GenSigTimeoutTime_APM2" SG_ 2564682064 N_PDU_18DDF150 0;
BA_ "GenSigTimeoutTime_VDCM" SG_ 2564682064 N_PDU_18DDF150 0;
BA_ "GenSigTimeoutTime_BPCM" SG_ 2564682064 N_PDU_18DDF150 0;
BA_ "GenSigTimeoutTime_EVCU2" SG_ 2564682064 N_PDU_18DDF150 0;
BA_ "GenSigTimeoutTime_IDCM" SG_ 2564682064 N_PDU_18DDF150 0;
BA_ "GenSigTimeoutTime_SGW" SG_ 2564682064 N_PDU_18DDF150 0;
BA_ "GenSigTimeoutTime_HCP" SG_ 2564485712 N_PDU_18DAF250 0;
BA_ "GenSigTimeoutTime_PPIM" SG_ 2564485712 N_PDU_18DAF250 0;
BA_ "GenSigTimeoutTime_APM2" SG_ 2564485712 N_PDU_18DAF250 0;
BA_ "GenSigTimeoutTime_VDCM" SG_ 2564485712 N_PDU_18DAF250 0;
BA_ "GenSigTimeoutTime_BPCM" SG_ 2564485712 N_PDU_18DAF250 0;
BA_ "GenSigTimeoutTime_EVCU2" SG_ 2564485712 N_PDU_18DAF250 0;
BA_ "GenSigTimeoutTime_IDCM" SG_ 2564485712 N_PDU_18DAF250 0;
BA_ "GenSigTimeoutTime_SGW" SG_ 2564485712 N_PDU_18DAF250 0;
BA_ "GenSigTimeoutTime_HCP" SG_ 2564682320 N_PDU_18DDF250 0;
BA_ "GenSigTimeoutTime_PPIM" SG_ 2564682320 N_PDU_18DDF250 0;
BA_ "GenSigTimeoutTime_APM2" SG_ 2564682320 N_PDU_18DDF250 0;
BA_ "GenSigTimeoutTime_VDCM" SG_ 2564682320 N_PDU_18DDF250 0;
BA_ "GenSigTimeoutTime_BPCM" SG_ 2564682320 N_PDU_18DDF250 0;
BA_ "GenSigTimeoutTime_EVCU2" SG_ 2564682320 N_PDU_18DDF250 0;
BA_ "GenSigTimeoutTime_IDCM" SG_ 2564682320 N_PDU_18DDF250 0;
BA_ "GenSigTimeoutTime_SGW" SG_ 2564682320 N_PDU_18DDF250 0;
BA_ "GenSigTimeoutTime_HCP" SG_ 2564682052 N_PDU_18DDF144 0;
BA_ "GenSigTimeoutTime_PPIM" SG_ 2564682052 N_PDU_18DDF144 0;
BA_ "GenSigTimeoutTime_APM2" SG_ 2564682052 N_PDU_18DDF144 0;
BA_ "GenSigTimeoutTime_VDCM" SG_ 2564682052 N_PDU_18DDF144 0;
BA_ "GenSigTimeoutTime_BPCM" SG_ 2564682052 N_PDU_18DDF144 0;
BA_ "GenSigTimeoutTime_EVCU2" SG_ 2564682052 N_PDU_18DDF144 0;
BA_ "GenSigTimeoutTime_IDCM" SG_ 2564682052 N_PDU_18DDF144 0;
BA_ "GenSigTimeoutTime_SGW" SG_ 2564682052 N_PDU_18DDF144 0;
BA_ "GenSigTimeoutTime_HCP" SG_ 2564682308 N_PDU_18DDF244 0;
BA_ "GenSigTimeoutTime_PPIM" SG_ 2564682308 N_PDU_18DDF244 0;
BA_ "GenSigTimeoutTime_APM2" SG_ 2564682308 N_PDU_18DDF244 0;
BA_ "GenSigTimeoutTime_VDCM" SG_ 2564682308 N_PDU_18DDF244 0;
BA_ "GenSigTimeoutTime_BPCM" SG_ 2564682308 N_PDU_18DDF244 0;
BA_ "GenSigTimeoutTime_EVCU2" SG_ 2564682308 N_PDU_18DDF244 0;
BA_ "GenSigTimeoutTime_IDCM" SG_ 2564682308 N_PDU_18DDF244 0;
BA_ "GenSigTimeoutTime_SGW" SG_ 2564682308 N_PDU_18DDF244 0;
BA_ "GenSigTimeoutTime_HCP" SG_ 2564444402 N_PDU_18DA50F2 0;
BA_ "GenSigTimeoutTime_PPIM" SG_ 2564444402 N_PDU_18DA50F2 0;
BA_ "GenSigTimeoutTime_APM2" SG_ 2564444402 N_PDU_18DA50F2 0;
BA_ "GenSigTimeoutTime_VDCM" SG_ 2564444402 N_PDU_18DA50F2 0;
BA_ "GenSigTimeoutTime_BPCM" SG_ 2564444402 N_PDU_18DA50F2 0;
BA_ "GenSigTimeoutTime_EVCU2" SG_ 2564444402 N_PDU_18DA50F2 0;
BA_ "GenSigTimeoutTime_IDCM" SG_ 2564444402 N_PDU_18DA50F2 0;
BA_ "GenSigTimeoutTime_SGW" SG_ 2564444402 N_PDU_18DA50F2 0;
BA_ "GenSigTimeoutTime_HCP" SG_ 2564441330 N_PDU_18DA44F2 0;
BA_ "GenSigTimeoutTime_PPIM" SG_ 2564441330 N_PDU_18DA44F2 0;
BA_ "GenSigTimeoutTime_APM2" SG_ 2564441330 N_PDU_18DA44F2 0;
BA_ "GenSigTimeoutTime_VDCM" SG_ 2564441330 N_PDU_18DA44F2 0;
BA_ "GenSigTimeoutTime_BPCM" SG_ 2564441330 N_PDU_18DA44F2 0;
BA_ "GenSigTimeoutTime_EVCU2" SG_ 2564441330 N_PDU_18DA44F2 0;
BA_ "GenSigTimeoutTime_IDCM" SG_ 2564441330 N_PDU_18DA44F2 0;
BA_ "GenSigTimeoutTime_SGW" SG_ 2564441330 N_PDU_18DA44F2 0;
BA_ "GenSigTimeoutTime_HCP" SG_ 2564485700 N_PDU_18DAF244 0;
BA_ "GenSigTimeoutTime_PPIM" SG_ 2564485700 N_PDU_18DAF244 0;
BA_ "GenSigTimeoutTime_APM2" SG_ 2564485700 N_PDU_18DAF244 0;
BA_ "GenSigTimeoutTime_VDCM" SG_ 2564485700 N_PDU_18DAF244 0;
BA_ "GenSigTimeoutTime_BPCM" SG_ 2564485700 N_PDU_18DAF244 0;
BA_ "GenSigTimeoutTime_EVCU2" SG_ 2564485700 N_PDU_18DAF244 0;
BA_ "GenSigTimeoutTime_IDCM" SG_ 2564485700 N_PDU_18DAF244 0;
BA_ "GenSigTimeoutTime_SGW" SG_ 2564485700 N_PDU_18DAF244 0;
BA_ "GenSigTimeoutTime_HCP" SG_ 1578 Charging_WHr 0;
BA_ "GenSigTimeoutTime_PPIM" SG_ 1578 Charging_WHr 0;
BA_ "GenSigTimeoutTime_APM2" SG_ 1578 Charging_WHr 0;
BA_ "GenSigTimeoutTime_VDCM" SG_ 1578 Charging_WHr 0;
BA_ "GenSigTimeoutTime_HCP" SG_ 1578 OBC_ChargeTimeMin 0;
BA_ "GenSigTimeoutTime_PPIM" SG_ 1578 OBC_ChargeTimeMin 0;
BA_ "GenSigTimeoutTime_APM2" SG_ 1578 OBC_ChargeTimeMin 0;
BA_ "GenSigTimeoutTime_VDCM" SG_ 1578 OBC_ChargeTimeMin 0;
BA_ "GenSigTimeoutTime_HCP" SG_ 1578 OBC_ChargeTimeSec 0;
BA_ "GenSigTimeoutTime_PPIM" SG_ 1578 OBC_ChargeTimeSec 0;
BA_ "GenSigTimeoutTime_APM2" SG_ 1578 OBC_ChargeTimeSec 0;
BA_ "GenSigTimeoutTime_VDCM" SG_ 1578 OBC_ChargeTimeSec 0;
BA_ "GenSigTimeoutTime_HCP" SG_ 1578 OBC_IdleTimeMin 0;
BA_ "GenSigTimeoutTime_PPIM" SG_ 1578 OBC_IdleTimeMin 0;
BA_ "GenSigTimeoutTime_APM2" SG_ 1578 OBC_IdleTimeMin 0;
BA_ "GenSigTimeoutTime_VDCM" SG_ 1578 OBC_IdleTimeMin 0;
BA_ "GenSigTimeoutTime_HCP" SG_ 1578 OBC_IdleTimeSec 0;
BA_ "GenSigTimeoutTime_PPIM" SG_ 1578 OBC_IdleTimeSec 0;
BA_ "GenSigTimeoutTime_APM2" SG_ 1578 OBC_IdleTimeSec 0;
BA_ "GenSigTimeoutTime_VDCM" SG_ 1578 OBC_IdleTimeSec 0;
BA_ "GenSigTimeoutTime_BPCM" SG_ 1578 OBC_IdleTimeSec 0;
BA_ "GenSigTimeoutTime_EVCU2" SG_ 1578 OBC_IdleTimeSec 0;
BA_ "GenSigTimeoutTime_IDCM" SG_ 1578 OBC_IdleTimeSec 0;
BA_ "GenSigTimeoutTime_SGW" SG_ 1578 OBC_IdleTimeSec 0;
BA_ "GenSigTimeoutTime_BPCM" SG_ 1578 OBC_IdleTimeMin 0;
BA_ "GenSigTimeoutTime_EVCU2" SG_ 1578 OBC_IdleTimeMin 0;
BA_ "GenSigTimeoutTime_IDCM" SG_ 1578 OBC_IdleTimeMin 0;
BA_ "GenSigTimeoutTime_SGW" SG_ 1578 OBC_IdleTimeMin 0;
BA_ "GenSigTimeoutTime_BPCM" SG_ 1578 OBC_ChargeTimeSec 0;
BA_ "GenSigTimeoutTime_EVCU2" SG_ 1578 OBC_ChargeTimeSec 0;
BA_ "GenSigTimeoutTime_IDCM" SG_ 1578 OBC_ChargeTimeSec 0;
BA_ "GenSigTimeoutTime_SGW" SG_ 1578 OBC_ChargeTimeSec 0;
BA_ "GenSigTimeoutTime_BPCM" SG_ 1578 OBC_ChargeTimeMin 0;
BA_ "GenSigTimeoutTime_EVCU2" SG_ 1578 OBC_ChargeTimeMin 0;
BA_ "GenSigTimeoutTime_IDCM" SG_ 1578 OBC_ChargeTimeMin 0;
BA_ "GenSigTimeoutTime_SGW" SG_ 1578 OBC_ChargeTimeMin 0;
BA_ "GenSigTimeoutTime_BPCM" SG_ 1578 Charging_WHr 0;
BA_ "GenSigTimeoutTime_EVCU2" SG_ 1578 Charging_WHr 0;
BA_ "GenSigTimeoutTime_IDCM" SG_ 1578 Charging_WHr 0;
BA_ "GenSigTimeoutTime_SGW" SG_ 1578 Charging_WHr 0;
BA_ "GenSigTimeoutTime_HCP" SG_ 478 LVDC_VoltageSetpoint 0;
BA_ "GenSigTimeoutTime_PPIM" SG_ 478 LVDC_VoltageSetpoint 0;
BA_ "GenSigStartValue" SG_ 478 LVDC_VoltageSetpoint 221;
BA_ "GenSigTimeoutTime_EVCU2" SG_ 478 LVDC_VoltageSetpoint 0;
BA_ "GenSigTimeoutTime_IDCM" SG_ 478 LVDC_VoltageSetpoint 0;
BA_ "GenSigTimeoutTime_SGW" SG_ 478 LVDC_VoltageSetpoint 0;
BA_ "GenSigTimeoutTime_HCP" SG_ 478 CRC_HYBRID_CHARGING_COMMAND 0;
BA_ "GenSigTimeoutTime_PPIM" SG_ 478 CRC_HYBRID_CHARGING_COMMAND 0;
BA_ "GenSigTimeoutTime_APM2" SG_ 478 CRC_HYBRID_CHARGING_COMMAND 0;
BA_ "GenSigTimeoutTime_VDCM" SG_ 478 CRC_HYBRID_CHARGING_COMMAND 0;
BA_ "GenSigTimeoutTime_HCP" SG_ 478 EchargeSOCRange_ePT 0;
BA_ "GenSigTimeoutTime_PPIM" SG_ 478 EchargeSOCRange_ePT 0;
BA_ "GenSigTimeoutTime_HCP" SG_ 478 HVDC_CurrentSetpoint 0;
BA_ "GenSigTimeoutTime_PPIM" SG_ 478 HVDC_CurrentSetpoint 0;
BA_ "GenSigStartValue" SG_ 478 HVDC_CurrentSetpoint 229;
BA_ "GenSigTimeoutTime_EVCU2" SG_ 478 HVDC_CurrentSetpoint 0;
BA_ "GenSigTimeoutTime_IDCM" SG_ 478 HVDC_CurrentSetpoint 0;
BA_ "GenSigTimeoutTime_SGW" SG_ 478 HVDC_CurrentSetpoint 0;
BA_ "GenSigTimeoutTime_HCP" SG_ 478 HVDC_VoltageSetpoint 0;
BA_ "GenSigTimeoutTime_PPIM" SG_ 478 HVDC_VoltageSetpoint 0;
BA_ "GenSigTimeoutTime_EVCU2" SG_ 478 HVDC_VoltageSetpoint 0;
BA_ "GenSigTimeoutTime_IDCM" SG_ 478 HVDC_VoltageSetpoint 0;
BA_ "GenSigTimeoutTime_SGW" SG_ 478 HVDC_VoltageSetpoint 0;
BA_ "GenSigTimeoutTime_HCP" SG_ 478 HVInverterVoltage_Rational 0;
BA_ "GenSigTimeoutTime_PPIM" SG_ 478 HVInverterVoltage_Rational 0;
BA_ "GenSigTimeoutTime_EVCU2" SG_ 478 HVInverterVoltage_Rational 0;
BA_ "GenSigTimeoutTime_IDCM" SG_ 478 HVInverterVoltage_Rational 0;
BA_ "GenSigTimeoutTime_SGW" SG_ 478 HVInverterVoltage_Rational 0;
BA_ "GenSigTimeoutTime_HCP" SG_ 478 LVDC_CurrentSetpoint 0;
BA_ "GenSigTimeoutTime_PPIM" SG_ 478 LVDC_CurrentSetpoint 0;
BA_ "GenSigStartValue" SG_ 478 LVDC_CurrentSetpoint 255;
BA_ "GenSigTimeoutTime_EVCU2" SG_ 478 LVDC_CurrentSetpoint 0;
BA_ "GenSigTimeoutTime_IDCM" SG_ 478 LVDC_CurrentSetpoint 0;
BA_ "GenSigTimeoutTime_SGW" SG_ 478 LVDC_CurrentSetpoint 0;
BA_ "GenSigTimeoutTime_HCP" SG_ 478 LVDC_SystemVoltageAct 0;
BA_ "GenSigTimeoutTime_PPIM" SG_ 478 LVDC_SystemVoltageAct 0;
BA_ "GenSigTimeoutTime_EVCU2" SG_ 478 LVDC_SystemVoltageAct 0;
BA_ "GenSigTimeoutTime_IDCM" SG_ 478 LVDC_SystemVoltageAct 0;
BA_ "GenSigTimeoutTime_SGW" SG_ 478 LVDC_SystemVoltageAct 0;
BA_ "GenSigTimeoutTime_HCP" SG_ 478 MainHV_ContactorCommand 0;
BA_ "GenSigTimeoutTime_PPIM" SG_ 478 MainHV_ContactorCommand 0;
BA_ "GenSigTimeoutTime_EVCU2" SG_ 478 MainHV_ContactorCommand 0;
BA_ "GenSigTimeoutTime_IDCM" SG_ 478 MainHV_ContactorCommand 0;
BA_ "GenSigTimeoutTime_SGW" SG_ 478 MainHV_ContactorCommand 0;
BA_ "GenSigTimeoutTime_HCP" SG_ 478 OBC_ControlMethod 0;
BA_ "GenSigTimeoutTime_PPIM" SG_ 478 OBC_ControlMethod 0;
BA_ "GenSigTimeoutTime_APM2" SG_ 478 OBC_ControlMethod 0;
BA_ "GenSigTimeoutTime_VDCM" SG_ 478 OBC_ControlMethod 0;
BA_ "GenSigTimeoutTime_HCP" SG_ 478 OBC_ModeRequest 0;
BA_ "GenSigTimeoutTime_PPIM" SG_ 478 OBC_ModeRequest 0;
BA_ "GenSigTimeoutTime_HCP" SG_ 478 ClearLegislatedDiagInfo 0;
BA_ "GenSigTimeoutTime_PPIM" SG_ 478 ClearLegislatedDiagInfo 0;
BA_ "GenSigTimeoutTime_EVCU2" SG_ 478 ClearLegislatedDiagInfo 0;
BA_ "GenSigTimeoutTime_IDCM" SG_ 478 ClearLegislatedDiagInfo 0;
BA_ "GenSigTimeoutTime_SGW" SG_ 478 ClearLegislatedDiagInfo 0;
BA_ "GenSigTimeoutTime_HCP" SG_ 478 DCDC_OperationModeEnable 0;
BA_ "GenSigTimeoutTime_PPIM" SG_ 478 DCDC_OperationModeEnable 0;
BA_ "GenSigTimeoutTime_EVCU2" SG_ 478 DCDC_OperationModeEnable 0;
BA_ "GenSigTimeoutTime_IDCM" SG_ 478 DCDC_OperationModeEnable 0;
BA_ "GenSigTimeoutTime_SGW" SG_ 478 DCDC_OperationModeEnable 0;
BA_ "GenSigTimeoutTime_HCP" SG_ 478 HVInverterVoltage_RationalV 0;
BA_ "GenSigTimeoutTime_PPIM" SG_ 478 HVInverterVoltage_RationalV 0;
BA_ "GenSigTimeoutTime_EVCU2" SG_ 478 HVInverterVoltage_RationalV 0;
BA_ "GenSigTimeoutTime_IDCM" SG_ 478 HVInverterVoltage_RationalV 0;
BA_ "GenSigTimeoutTime_SGW" SG_ 478 HVInverterVoltage_RationalV 0;
BA_ "GenSigTimeoutTime_BPCM" SG_ 478 J1772_CloseS2 0;
BA_ "GenSigTimeoutTime_EVCU2" SG_ 478 J1772_CloseS2 0;
BA_ "GenSigTimeoutTime_SGW" SG_ 478 J1772_CloseS2 0;
BA_ "GenSigTimeoutTime_HCP" SG_ 478 J1772_CloseS2 0;
BA_ "GenSigTimeoutTime_PPIM" SG_ 478 J1772_CloseS2 0;
BA_ "GenSigTimeoutTime_APM2" SG_ 478 J1772_CloseS2 0;
BA_ "GenSigTimeoutTime_VDCM" SG_ 478 J1772_CloseS2 0;
BA_ "GenSigTimeoutTime_HCP" SG_ 478 VoltageRequest 0;
BA_ "GenSigTimeoutTime_PPIM" SG_ 478 VoltageRequest 0;
BA_ "GenSigTimeoutTime_APM2" SG_ 478 VoltageRequest 0;
BA_ "GenSigTimeoutTime_VDCM" SG_ 478 VoltageRequest 0;
BA_ "GenSigStartValue" SG_ 478 HVBatCoolantLevelLow 3;
BA_ "GenSigTimeoutTime_EVCU2" SG_ 478 HVBatCoolantLevelLow 0;
BA_ "GenSigTimeoutTime_IDCM" SG_ 478 HVBatCoolantLevelLow 0;
BA_ "GenSigTimeoutTime_SGW" SG_ 478 HVBatCoolantLevelLow 0;
BA_ "GenSigTimeoutTime_EVCU2" SG_ 1578 ACplug_PwrMax 0;
BA_ "GenSigTimeoutTime_IDCM" SG_ 1578 ACplug_PwrMax 0;
BA_ "GenSigTimeoutTime_SGW" SG_ 1578 ACplug_PwrMax 0;
BA_ "GenSigTimeoutTime_BPCM" SG_ 1578 OBC_EVServiceLampFlash 0;
BA_ "GenSigTimeoutTime_EVCU2" SG_ 1578 OBC_EVServiceLampFlash 0;
BA_ "GenSigTimeoutTime_IDCM" SG_ 1578 OBC_EVServiceLampFlash 0;
BA_ "GenSigTimeoutTime_SGW" SG_ 1578 OBC_EVServiceLampFlash 0;
BA_ "GenSigTimeoutTime_BPCM" SG_ 1578 OBC_CurrentFailureSts 0;
BA_ "GenSigTimeoutTime_EVCU2" SG_ 1578 OBC_CurrentFailureSts 0;
BA_ "GenSigTimeoutTime_IDCM" SG_ 1578 OBC_CurrentFailureSts 0;
BA_ "GenSigTimeoutTime_SGW" SG_ 1578 OBC_CurrentFailureSts 0;
BA_ "GenSigTimeoutTime_BPCM" SG_ 1578 OBC_ChargingFaultSts 0;
BA_ "GenSigTimeoutTime_EVCU2" SG_ 1578 OBC_ChargingFaultSts 0;
BA_ "GenSigTimeoutTime_IDCM" SG_ 1578 OBC_ChargingFaultSts 0;
BA_ "GenSigTimeoutTime_SGW" SG_ 1578 OBC_ChargingFaultSts 0;
BA_ "GenSigTimeoutTime_BPCM" SG_ 1578 OBC_ChargeFailure 0;
BA_ "GenSigTimeoutTime_EVCU2" SG_ 1578 OBC_ChargeFailure 0;
BA_ "GenSigTimeoutTime_IDCM" SG_ 1578 OBC_ChargeFailure 0;
BA_ "GenSigTimeoutTime_SGW" SG_ 1578 OBC_ChargeFailure 0;
BA_ "GenSigTimeoutTime_BPCM" SG_ 1578 OBC_CaptureEnvironmentData 0;
BA_ "GenSigTimeoutTime_EVCU2" SG_ 1578 OBC_CaptureEnvironmentData 0;
BA_ "GenSigTimeoutTime_IDCM" SG_ 1578 OBC_CaptureEnvironmentData 0;
BA_ "GenSigTimeoutTime_SGW" SG_ 1578 OBC_CaptureEnvironmentData 0;
BA_ "GenSigTimeoutTime_HCP" SG_ 478 AC_Curr_Max_Thrsh 0;
BA_ "GenSigTimeoutTime_PPIM" SG_ 478 AC_Curr_Max_Thrsh 0;
BA_ "GenSigTimeoutTime_APM2" SG_ 478 AC_Curr_Max_Thrsh 0;
BA_ "GenSigTimeoutTime_VDCM" SG_ 478 AC_Curr_Max_Thrsh 0;
BA_ "GenSigTimeoutTime_HCP" SG_ 478 AC_Curr_Min_Thrsh 0;
BA_ "GenSigTimeoutTime_PPIM" SG_ 478 AC_Curr_Min_Thrsh 0;
BA_ "GenSigTimeoutTime_APM2" SG_ 478 AC_Curr_Min_Thrsh 0;
BA_ "GenSigTimeoutTime_VDCM" SG_ 478 AC_Curr_Min_Thrsh 0;
BA_ "GenSigTimeoutTime_HCP" SG_ 478 ChargeEnable 0;
BA_ "GenSigTimeoutTime_PPIM" SG_ 478 ChargeEnable 0;
BA_ "GenSigTimeoutTime_APM2" SG_ 478 ChargeEnable 0;
BA_ "GenSigTimeoutTime_VDCM" SG_ 478 ChargeEnable 0;
BA_ "GenSigTimeoutTime_BPCM" SG_ 478 DC_Curr_Max_Thrsh 0;
BA_ "GenSigTimeoutTime_EVCU2" SG_ 478 DC_Curr_Max_Thrsh 0;
BA_ "GenSigTimeoutTime_SGW" SG_ 478 DC_Curr_Max_Thrsh 0;
BA_ "GenSigTimeoutTime_HCP" SG_ 478 DC_Curr_Max_Thrsh 0;
BA_ "GenSigTimeoutTime_PPIM" SG_ 478 DC_Curr_Max_Thrsh 0;
BA_ "GenSigTimeoutTime_APM2" SG_ 478 DC_Curr_Max_Thrsh 0;
BA_ "GenSigTimeoutTime_VDCM" SG_ 478 DC_Curr_Max_Thrsh 0;
BA_ "GenSigStartValue" SG_ 478 DC_Curr_Max_Thrsh 511;
BA_ "GenSigTimeoutTime_BPCM" SG_ 478 HV_Volt_Max_Thrsh 0;
BA_ "GenSigTimeoutTime_EVCU2" SG_ 478 HV_Volt_Max_Thrsh 0;
BA_ "GenSigTimeoutTime_SGW" SG_ 478 HV_Volt_Max_Thrsh 0;
BA_ "GenSigTimeoutTime_HCP" SG_ 478 HV_Volt_Max_Thrsh 0;
BA_ "GenSigTimeoutTime_PPIM" SG_ 478 HV_Volt_Max_Thrsh 0;
BA_ "GenSigTimeoutTime_APM2" SG_ 478 HV_Volt_Max_Thrsh 0;
BA_ "GenSigTimeoutTime_VDCM" SG_ 478 HV_Volt_Max_Thrsh 0;
BA_ "GenSigTimeoutTime_BPCM" SG_ 478 HV_Volt_Min_Thrsh 0;
BA_ "GenSigTimeoutTime_EVCU2" SG_ 478 HV_Volt_Min_Thrsh 0;
BA_ "GenSigTimeoutTime_SGW" SG_ 478 HV_Volt_Min_Thrsh 0;
BA_ "GenSigTimeoutTime_HCP" SG_ 478 HV_Volt_Min_Thrsh 0;
BA_ "GenSigTimeoutTime_PPIM" SG_ 478 HV_Volt_Min_Thrsh 0;
BA_ "GenSigTimeoutTime_APM2" SG_ 478 HV_Volt_Min_Thrsh 0;
BA_ "GenSigTimeoutTime_VDCM" SG_ 478 HV_Volt_Min_Thrsh 0;
BA_ "GenSigStartValue" SG_ 478 OBC_OperativeModeReq 15;
BA_ "GenSigTimeoutTime_BPCM" SG_ 478 OBC_OperativeModeReq 0;
BA_ "GenSigTimeoutTime_EVCU2" SG_ 478 OBC_OperativeModeReq 0;
BA_ "GenSigTimeoutTime_SGW" SG_ 478 OBC_OperativeModeReq 0;
BA_ "GenSigTimeoutTime_HCP" SG_ 478 OBC_OperativeModeReq 0;
BA_ "GenSigTimeoutTime_PPIM" SG_ 478 OBC_OperativeModeReq 0;
BA_ "GenSigTimeoutTime_APM2" SG_ 478 OBC_OperativeModeReq 0;
BA_ "GenSigTimeoutTime_VDCM" SG_ 478 OBC_OperativeModeReq 0;
BA_ "GenSigTimeoutTime_HCP" SG_ 478 CurrentRequest 0;
BA_ "GenSigTimeoutTime_PPIM" SG_ 478 CurrentRequest 0;
BA_ "GenSigTimeoutTime_APM2" SG_ 478 CurrentRequest 0;
BA_ "GenSigTimeoutTime_VDCM" SG_ 478 CurrentRequest 0;
BA_ "GenSigTimeoutTime_BPCM" SG_ 1578 OBC_Prox 0;
BA_ "GenSigTimeoutTime_IDCM" SG_ 1578 OBC_Prox 0;
BA_ "GenSigTimeoutTime_SGW" SG_ 1578 OBC_Prox 0;
BA_ "GenSigTimeoutTime_BPCM" SG_ 1578 OBC_Pilot 0;
BA_ "GenSigTimeoutTime_IDCM" SG_ 1578 OBC_Pilot 0;
BA_ "GenSigTimeoutTime_SGW" SG_ 1578 OBC_Pilot 0;
BA_ "GenSigTimeoutTime_BPCM" SG_ 478 VDCM_SessnStopReq 0;
BA_ "GenSigTimeoutTime_EVCU2" SG_ 478 VDCM_SessnStopReq 0;
BA_ "GenSigTimeoutTime_HCP" SG_ 478 VDCM_SessnStopReq 0;
BA_ "GenSigTimeoutTime_PPIM" SG_ 478 VDCM_SessnStopReq 0;
BA_ "GenSigTimeoutTime_APM2" SG_ 478 VDCM_SessnStopReq 0;
BA_ "GenSigTimeoutTime_VDCM" SG_ 478 VDCM_SessnStopReq 0;
BA_ "GenSigTimeoutTime_HCP" SG_ 478 VDCM_StsWldgReq 0;
BA_ "GenSigTimeoutTime_PPIM" SG_ 478 VDCM_StsWldgReq 0;
BA_ "GenSigTimeoutTime_APM2" SG_ 478 VDCM_StsWldgReq 0;
BA_ "GenSigTimeoutTime_VDCM" SG_ 478 VDCM_StsWldgReq 0;
BA_ "GenSigTimeoutTime_BPCM" SG_ 1578 OBCM_PrechargeSts 0;
BA_ "GenSigTimeoutTime_EVCU2" SG_ 1578 OBCM_PrechargeSts 0;
BA_ "GenSigTimeoutTime_IDCM" SG_ 1578 OBCM_PrechargeSts 0;
BA_ "GenSigTimeoutTime_SGW" SG_ 1578 OBCM_PrechargeSts 0;
BA_ "GenSigTimeoutTime_HCP" SG_ 478 VDCM_StsSWWldgReq 0;
BA_ "GenSigTimeoutTime_PPIM" SG_ 478 VDCM_StsSWWldgReq 0;
BA_ "GenSigTimeoutTime_VDCM" SG_ 478 VDCM_StsSWWldgReq 0;
BA_ "GenSigTimeoutTime_BPCM" SG_ 478 VDCM_StsSWWldgReq 0;
BA_ "GenSigTimeoutTime_EVCU2" SG_ 478 VDCM_StsSWWldgReq 0;
BA_ "GenSigTimeoutTime_IDCM" SG_ 478 VDCM_StsSWWldgReq 0;
BA_ "GenSigTimeoutTime_SGW" SG_ 478 VDCM_StsSWWldgReq 0;
BA_ "GenSigTimeoutTime_HCP" SG_ 1579 CRC_HYBRID_CHARGING_STATUS 0;
BA_ "GenSigTimeoutTime_PPIM" SG_ 1579 CRC_HYBRID_CHARGING_STATUS 0;
BA_ "GenSigTimeoutTime_APM2" SG_ 1579 CRC_HYBRID_CHARGING_STATUS 0;
BA_ "GenSigTimeoutTime_VDCM" SG_ 1579 CRC_HYBRID_CHARGING_STATUS 0;
BA_ "GenSigTimeoutTime_BPCM" SG_ 1579 CRC_HYBRID_CHARGING_STATUS 0;
BA_ "GenSigTimeoutTime_EVCU2" SG_ 1579 CRC_HYBRID_CHARGING_STATUS 0;
BA_ "GenSigTimeoutTime_SGW" SG_ 1579 CRC_HYBRID_CHARGING_STATUS 0;
BA_ "GenSigTimeoutTime_BPCM" SG_ 478 VDCM_StsWldgReq 0;
BA_ "GenSigTimeoutTime_EVCU2" SG_ 478 VDCM_StsWldgReq 0;
BA_ "GenSigTimeoutTime_SGW" SG_ 478 VDCM_StsWldgReq 0;
BA_ "GenSigTimeoutTime_SGW" SG_ 478 VDCM_SessnStopReq 0;
BA_ "GenSigTimeoutTime_BPCM" SG_ 2654486598 CBV_bit6_PartialNtwInfBit_1E384046 0;
BA_ "GenSigTimeoutTime_EVCU2" SG_ 2654486598 CBV_bit6_PartialNtwInfBit_1E384046 0;
BA_ "GenSigTimeoutTime_IDCM" SG_ 2654486598 CBV_bit6_PartialNtwInfBit_1E384046 0;
BA_ "GenSigTimeoutTime_SGW" SG_ 2654486598 CBV_bit6_PartialNtwInfBit_1E384046 0;
BA_ "GenSigTimeoutTime_HCP" SG_ 2654486598 CBV_bit6_PartialNtwInfBit_1E384046 0;
BA_ "GenSigTimeoutTime_PPIM" SG_ 2654486598 CBV_bit6_PartialNtwInfBit_1E384046 0;
BA_ "GenSigTimeoutTime_APM2" SG_ 2654486598 CBV_bit6_PartialNtwInfBit_1E384046 0;
BA_ "GenSigTimeoutTime_VDCM" SG_ 2654486598 CBV_bit6_PartialNtwInfBit_1E384046 0;
BA_ "GenSigTimeoutTime_BPCM" SG_ 2654486598 CBV_bit4_ActiveWakeupBit_1E384046 0;
BA_ "GenSigTimeoutTime_EVCU2" SG_ 2654486598 CBV_bit4_ActiveWakeupBit_1E384046 0;
BA_ "GenSigTimeoutTime_IDCM" SG_ 2654486598 CBV_bit4_ActiveWakeupBit_1E384046 0;
BA_ "GenSigTimeoutTime_SGW" SG_ 2654486598 CBV_bit4_ActiveWakeupBit_1E384046 0;
BA_ "GenSigTimeoutTime_HCP" SG_ 2654486598 CBV_bit4_ActiveWakeupBit_1E384046 0;
BA_ "GenSigTimeoutTime_PPIM" SG_ 2654486598 CBV_bit4_ActiveWakeupBit_1E384046 0;
BA_ "GenSigTimeoutTime_APM2" SG_ 2654486598 CBV_bit4_ActiveWakeupBit_1E384046 0;
BA_ "GenSigTimeoutTime_VDCM" SG_ 2654486598 CBV_bit4_ActiveWakeupBit_1E384046 0;
BA_ "GenSigTimeoutTime_BPCM" SG_ 2654486598 CBV_bit3_NMCoordinatorBit_1E384046 0;
BA_ "GenSigTimeoutTime_EVCU2" SG_ 2654486598 CBV_bit3_NMCoordinatorBit_1E384046 0;
BA_ "GenSigTimeoutTime_IDCM" SG_ 2654486598 CBV_bit3_NMCoordinatorBit_1E384046 0;
BA_ "GenSigTimeoutTime_SGW" SG_ 2654486598 CBV_bit3_NMCoordinatorBit_1E384046 0;
BA_ "GenSigTimeoutTime_HCP" SG_ 2654486598 CBV_bit3_NMCoordinatorBit_1E384046 0;
BA_ "GenSigTimeoutTime_PPIM" SG_ 2654486598 CBV_bit3_NMCoordinatorBit_1E384046 0;
BA_ "GenSigTimeoutTime_APM2" SG_ 2654486598 CBV_bit3_NMCoordinatorBit_1E384046 0;
BA_ "GenSigTimeoutTime_VDCM" SG_ 2654486598 CBV_bit3_NMCoordinatorBit_1E384046 0;
BA_ "GenSigTimeoutTime_HCP" SG_ 2654486598 CBV_bit0_RepeatMessageRequestBit_1E384046 0;
BA_ "GenSigTimeoutTime_PPIM" SG_ 2654486598 CBV_bit0_RepeatMessageRequestBit_1E384046 0;
BA_ "GenSigTimeoutTime_APM2" SG_ 2654486598 CBV_bit0_RepeatMessageRequestBit_1E384046 0;
BA_ "GenSigTimeoutTime_VDCM" SG_ 2654486598 CBV_bit0_RepeatMessageRequestBit_1E384046 0;
BA_ "GenSigTimeoutTime_BPCM" SG_ 2654486598 CBV_bit0_RepeatMessageRequestBit_1E384046 0;
BA_ "GenSigTimeoutTime_EVCU2" SG_ 2654486598 CBV_bit0_RepeatMessageRequestBit_1E384046 0;
BA_ "GenSigTimeoutTime_IDCM" SG_ 2654486598 CBV_bit0_RepeatMessageRequestBit_1E384046 0;
BA_ "GenSigTimeoutTime_SGW" SG_ 2654486598 CBV_bit0_RepeatMessageRequestBit_1E384046 0;
BA_ "GenSigTimeoutTime_BPCM" SG_ 478 CurrentRequest 0;
BA_ "GenSigTimeoutTime_EVCU2" SG_ 478 CurrentRequest 0;
BA_ "GenSigTimeoutTime_SGW" SG_ 478 CurrentRequest 0;
BA_ "GenSigTimeoutTime_HCP" SG_ 2654486598 SourceNodeIdentifier_1E384046 0;
BA_ "GenSigTimeoutTime_PPIM" SG_ 2654486598 SourceNodeIdentifier_1E384046 0;
BA_ "GenSigTimeoutTime_APM2" SG_ 2654486598 SourceNodeIdentifier_1E384046 0;
BA_ "GenSigTimeoutTime_VDCM" SG_ 2654486598 SourceNodeIdentifier_1E384046 0;
BA_ "GenSigTimeoutTime_HCP" SG_ 2654486598 CBV_bit7_1E384046 0;
BA_ "GenSigTimeoutTime_PPIM" SG_ 2654486598 CBV_bit7_1E384046 0;
BA_ "GenSigTimeoutTime_APM2" SG_ 2654486598 CBV_bit7_1E384046 0;
BA_ "GenSigTimeoutTime_VDCM" SG_ 2654486598 CBV_bit7_1E384046 0;
BA_ "GenSigTimeoutTime_BPCM" SG_ 2654486598 CBV_bit5_1E384046 0;
BA_ "GenSigTimeoutTime_EVCU2" SG_ 2654486598 CBV_bit5_1E384046 0;
BA_ "GenSigTimeoutTime_IDCM" SG_ 2654486598 CBV_bit5_1E384046 0;
BA_ "GenSigTimeoutTime_SGW" SG_ 2654486598 CBV_bit5_1E384046 0;
BA_ "GenSigTimeoutTime_HCP" SG_ 2654486598 CBV_bit5_1E384046 0;
BA_ "GenSigTimeoutTime_PPIM" SG_ 2654486598 CBV_bit5_1E384046 0;
BA_ "GenSigTimeoutTime_APM2" SG_ 2654486598 CBV_bit5_1E384046 0;
BA_ "GenSigTimeoutTime_VDCM" SG_ 2654486598 CBV_bit5_1E384046 0;
BA_ "GenSigTimeoutTime_BPCM" SG_ 2654486598 CBV_bit2_1E384046 0;
BA_ "GenSigTimeoutTime_EVCU2" SG_ 2654486598 CBV_bit2_1E384046 0;
BA_ "GenSigTimeoutTime_IDCM" SG_ 2654486598 CBV_bit2_1E384046 0;
BA_ "GenSigTimeoutTime_SGW" SG_ 2654486598 CBV_bit2_1E384046 0;
BA_ "GenSigTimeoutTime_HCP" SG_ 2654486598 CBV_bit2_1E384046 0;
BA_ "GenSigTimeoutTime_PPIM" SG_ 2654486598 CBV_bit2_1E384046 0;
BA_ "GenSigTimeoutTime_APM2" SG_ 2654486598 CBV_bit2_1E384046 0;
BA_ "GenSigTimeoutTime_VDCM" SG_ 2654486598 CBV_bit2_1E384046 0;
BA_ "GenSigTimeoutTime_SGW" SG_ 2654486598 CBV_bit1_1E384046 0;
BA_ "GenSigTimeoutTime_HCP" SG_ 2654486598 CBV_bit1_1E384046 0;
BA_ "GenSigTimeoutTime_PPIM" SG_ 2654486598 CBV_bit1_1E384046 0;
BA_ "GenSigTimeoutTime_APM2" SG_ 2654486598 CBV_bit1_1E384046 0;
BA_ "GenSigTimeoutTime_VDCM" SG_ 2654486598 CBV_bit1_1E384046 0;
BA_ "GenSigTimeoutTime_BPCM" SG_ 2654486598 CBV_bit1_1E384046 0;
BA_ "GenSigTimeoutTime_EVCU2" SG_ 2654486598 CBV_bit1_1E384046 0;
BA_ "GenSigTimeoutTime_IDCM" SG_ 2654486598 CBV_bit1_1E384046 0;
BA_ "GenSigTimeoutTime_HCP" SG_ 1579 ChargeSystemFault 0;
BA_ "GenSigTimeoutTime_PPIM" SG_ 1579 ChargeSystemFault 0;
BA_ "GenSigTimeoutTime_APM2" SG_ 1579 ChargeSystemFault 0;
BA_ "GenSigTimeoutTime_VDCM" SG_ 1579 ChargeSystemFault 0;
BA_ "GenSigTimeoutTime_BPCM" SG_ 1579 ChargeSystemFault 0;
BA_ "GenSigTimeoutTime_EVCU2" SG_ 1579 ChargeSystemFault 0;
BA_ "GenSigTimeoutTime_SGW" SG_ 1579 ChargeSystemFault 0;
BA_ "GenSigTimeoutTime_HCP" SG_ 1579 ChargeSystemSts 0;
BA_ "GenSigTimeoutTime_PPIM" SG_ 1579 ChargeSystemSts 0;
BA_ "GenSigTimeoutTime_APM2" SG_ 1579 ChargeSystemSts 0;
BA_ "GenSigTimeoutTime_VDCM" SG_ 1579 ChargeSystemSts 0;
BA_ "GenSigTimeoutTime_EVCU2" SG_ 1579 ChargeSystemSts 0;
BA_ "GenSigTimeoutTime_SGW" SG_ 1579 ChargeSystemSts 0;
BA_ "GenSigTimeoutTime_HCP" SG_ 1579 VDCM_IDCChrgr 0;
BA_ "GenSigTimeoutTime_PPIM" SG_ 1579 VDCM_IDCChrgr 0;
BA_ "GenSigTimeoutTime_APM2" SG_ 1579 VDCM_IDCChrgr 0;
BA_ "GenSigTimeoutTime_VDCM" SG_ 1579 VDCM_IDCChrgr 0;
BA_ "GenSigTimeoutTime_BPCM" SG_ 1579 VDCM_IDCChrgr 0;
BA_ "GenSigTimeoutTime_EVCU2" SG_ 1579 VDCM_IDCChrgr 0;
BA_ "GenSigTimeoutTime_SGW" SG_ 1579 VDCM_IDCChrgr 0;
BA_ "GenSigTimeoutTime_HCP" SG_ 1579 VDCM_UDCChrgr 0;
BA_ "GenSigTimeoutTime_PPIM" SG_ 1579 VDCM_UDCChrgr 0;
BA_ "GenSigTimeoutTime_APM2" SG_ 1579 VDCM_UDCChrgr 0;
BA_ "GenSigTimeoutTime_VDCM" SG_ 1579 VDCM_UDCChrgr 0;
BA_ "GenSigTimeoutTime_BPCM" SG_ 1579 VDCM_UDCChrgr 0;
BA_ "GenSigTimeoutTime_EVCU2" SG_ 1579 VDCM_UDCChrgr 0;
BA_ "GenSigTimeoutTime_SGW" SG_ 1579 VDCM_UDCChrgr 0;
BA_ "GenSigTimeoutTime_HCP" SG_ 1579 OBCM_PLUG_STS 0;
BA_ "GenSigTimeoutTime_PPIM" SG_ 1579 OBCM_PLUG_STS 0;
BA_ "GenSigTimeoutTime_APM2" SG_ 1579 OBCM_PLUG_STS 0;
BA_ "GenSigTimeoutTime_VDCM" SG_ 1579 OBCM_PLUG_STS 0;
BA_ "GenSigTimeoutTime_BPCM" SG_ 1579 OBCM_PLUG_STS 0;
BA_ "GenSigTimeoutTime_EVCU2" SG_ 1579 OBCM_PLUG_STS 0;
BA_ "GenSigTimeoutTime_SGW" SG_ 1579 OBCM_PLUG_STS 0;
BA_ "GenSigTimeoutTime_BPCM" SG_ 478 ChargeEnable 0;
BA_ "GenSigTimeoutTime_EVCU2" SG_ 478 ChargeEnable 0;
BA_ "GenSigTimeoutTime_SGW" SG_ 478 ChargeEnable 0;
BA_ "GenSigTimeoutTime_BPCM" SG_ 478 AC_Curr_Min_Thrsh 0;
BA_ "GenSigTimeoutTime_EVCU2" SG_ 478 AC_Curr_Min_Thrsh 0;
BA_ "GenSigTimeoutTime_SGW" SG_ 478 AC_Curr_Min_Thrsh 0;
BA_ "GenSigTimeoutTime_BPCM" SG_ 478 AC_Curr_Max_Thrsh 0;
BA_ "GenSigTimeoutTime_EVCU2" SG_ 478 AC_Curr_Max_Thrsh 0;
BA_ "GenSigTimeoutTime_SGW" SG_ 478 AC_Curr_Max_Thrsh 0;
BA_ "GenSigTimeoutTime_BPCM" SG_ 478 VoltageRequest 0;
BA_ "GenSigTimeoutTime_EVCU2" SG_ 478 VoltageRequest 0;
BA_ "GenSigTimeoutTime_SGW" SG_ 478 VoltageRequest 0;
BA_ "GenSigStartValue" SG_ 478 OBC_ModeRequest 7;
BA_ "GenSigTimeoutTime_BPCM" SG_ 478 OBC_ModeRequest 0;
BA_ "GenSigTimeoutTime_EVCU2" SG_ 478 OBC_ModeRequest 0;
BA_ "GenSigTimeoutTime_SGW" SG_ 478 OBC_ModeRequest 0;
BA_ "GenSigTimeoutTime_HCP" SG_ 1579 ChargingLevel 0;
BA_ "GenSigTimeoutTime_PPIM" SG_ 1579 ChargingLevel 0;
BA_ "GenSigTimeoutTime_APM2" SG_ 1579 ChargingLevel 0;
BA_ "GenSigTimeoutTime_VDCM" SG_ 1579 ChargingLevel 0;
BA_ "GenSigTimeoutTime_EVCU2" SG_ 1579 ChargingLevel 0;
BA_ "GenSigTimeoutTime_SGW" SG_ 1579 ChargingLevel 0;
BA_ "GenSigTimeoutTime_BPCM" SG_ 478 OBC_ControlMethod 0;
BA_ "GenSigTimeoutTime_EVCU2" SG_ 478 OBC_ControlMethod 0;
BA_ "GenSigTimeoutTime_SGW" SG_ 478 OBC_ControlMethod 0;
BA_ "GenSigTimeoutTime_BPCM" SG_ 478 EchargeSOCRange_ePT 0;
BA_ "GenSigTimeoutTime_EVCU2" SG_ 478 EchargeSOCRange_ePT 0;
BA_ "GenSigTimeoutTime_IDCM" SG_ 478 EchargeSOCRange_ePT 0;
BA_ "GenSigTimeoutTime_SGW" SG_ 478 EchargeSOCRange_ePT 0;
BA_ "GenSigTimeoutTime_BPCM" SG_ 478 CRC_HYBRID_CHARGING_COMMAND 0;
BA_ "GenSigTimeoutTime_EVCU2" SG_ 478 CRC_HYBRID_CHARGING_COMMAND 0;
BA_ "GenSigTimeoutTime_SGW" SG_ 478 CRC_HYBRID_CHARGING_COMMAND 0;
BA_ "GenSigTimeoutTime_HCP" SG_ 1579 ACCurrent_MaxCal 0;
BA_ "GenSigTimeoutTime_PPIM" SG_ 1579 ACCurrent_MaxCal 0;
BA_ "GenSigTimeoutTime_APM2" SG_ 1579 ACCurrent_MaxCal 0;
BA_ "GenSigTimeoutTime_VDCM" SG_ 1579 ACCurrent_MaxCal 0;
BA_ "GenSigTimeoutTime_EVCU2" SG_ 1579 ACCurrent_MaxCal 0;
BA_ "GenSigTimeoutTime_SGW" SG_ 1579 ACCurrent_MaxCal 0;
BA_ "GenSigTimeoutTime_HCP" SG_ 1579 ChargeSystemFaultReason 0;
BA_ "GenSigTimeoutTime_PPIM" SG_ 1579 ChargeSystemFaultReason 0;
BA_ "GenSigTimeoutTime_APM2" SG_ 1579 ChargeSystemFaultReason 0;
BA_ "GenSigTimeoutTime_VDCM" SG_ 1579 ChargeSystemFaultReason 0;
BA_ "GenSigTimeoutTime_BPCM" SG_ 1579 ChargeSystemFaultReason 0;
BA_ "GenSigTimeoutTime_EVCU2" SG_ 1579 ChargeSystemFaultReason 0;
BA_ "GenSigTimeoutTime_SGW" SG_ 1579 ChargeSystemFaultReason 0;
BA_ "GenSigTimeoutTime_HCP" SG_ 1579 HVBatteryCurrent_MaxCal 0;
BA_ "GenSigTimeoutTime_PPIM" SG_ 1579 HVBatteryCurrent_MaxCal 0;
BA_ "GenSigTimeoutTime_APM2" SG_ 1579 HVBatteryCurrent_MaxCal 0;
BA_ "GenSigTimeoutTime_VDCM" SG_ 1579 HVBatteryCurrent_MaxCal 0;
BA_ "GenSigTimeoutTime_EVCU2" SG_ 1579 HVBatteryCurrent_MaxCal 0;
BA_ "GenSigTimeoutTime_SGW" SG_ 1579 HVBatteryCurrent_MaxCal 0;
BA_ "GenSigTimeoutTime_HCP" SG_ 1579 HVBatteryVoltage_MaxCal 0;
BA_ "GenSigTimeoutTime_PPIM" SG_ 1579 HVBatteryVoltage_MaxCal 0;
BA_ "GenSigTimeoutTime_APM2" SG_ 1579 HVBatteryVoltage_MaxCal 0;
BA_ "GenSigTimeoutTime_VDCM" SG_ 1579 HVBatteryVoltage_MaxCal 0;
BA_ "GenSigTimeoutTime_EVCU2" SG_ 1579 HVBatteryVoltage_MaxCal 0;
BA_ "GenSigTimeoutTime_SGW" SG_ 1579 HVBatteryVoltage_MaxCal 0;
BA_ "GenSigTimeoutTime_HCP" SG_ 1579 HVBatteryVoltage_MinCal 0;
BA_ "GenSigTimeoutTime_PPIM" SG_ 1579 HVBatteryVoltage_MinCal 0;
BA_ "GenSigTimeoutTime_APM2" SG_ 1579 HVBatteryVoltage_MinCal 0;
BA_ "GenSigTimeoutTime_VDCM" SG_ 1579 HVBatteryVoltage_MinCal 0;
BA_ "GenSigTimeoutTime_EVCU2" SG_ 1579 HVBatteryVoltage_MinCal 0;
BA_ "GenSigTimeoutTime_SGW" SG_ 1579 HVBatteryVoltage_MinCal 0;
BA_ "GenSigTimeoutTime_HCP" SG_ 262 EngineSpeed_W 0;
BA_ "GenSigTimeoutTime_EVCU2" SG_ 262 EngineSpeed_W 0;
BA_ "GenSigTimeoutTime_SGW" SG_ 262 EngineSpeed_W 0;
BA_ "GenSigTimeoutTime_EVCU2" SG_ 262 PowertrainPrplsnActv 0;
BA_ "GenSigTimeoutTime_SGW" SG_ 262 PowertrainPrplsnActv 0;
BA_ "GenSigTimeoutTime_HCP" SG_ 276 HEV_ESS_Mode 0;
BA_ "GenSigTimeoutTime_PPIM" SG_ 276 HEV_ESS_Mode 0;
BA_ "GenSigTimeoutTime_EVCU2" SG_ 276 HEV_ESS_Mode 0;
BA_ "GenSigTimeoutTime_IDCM" SG_ 276 HEV_ESS_Mode 0;
BA_ "GenSigTimeoutTime_SGW" SG_ 276 HEV_ESS_Mode 0;
BA_ "GenSigTimeoutTime_HCP" SG_ 258 VehicleSpeedVSOSig 0;
BA_ "GenSigTimeoutTime_APM2" SG_ 258 VehicleSpeedVSOSig 0;
BA_ "GenSigTimeoutTime_VDCM" SG_ 258 VehicleSpeedVSOSig 0;
BA_ "GenSigTimeoutTime_EVCU2" SG_ 258 VehicleSpeedVSOSig 0;
BA_ "GenSigTimeoutTime_SGW" SG_ 258 VehicleSpeedVSOSig 0;
BA_ "GenSigTimeoutTime_HCP" SG_ 750 Battery_Volt_1 0;
BA_ "GenSigTimeoutTime_APM2" SG_ 750 Battery_Volt_1 0;
BA_ "GenSigTimeoutTime_VDCM" SG_ 750 Battery_Volt_1 0;
BA_ "GenSigTimeoutTime_EVCU2" SG_ 750 Battery_Volt_1 0;
BA_ "GenSigTimeoutTime_SGW" SG_ 750 Battery_Volt_1 0;
BA_ "GenSigTimeoutTime_HCP" SG_ 276 PropulsionSystemActive_114 0;
BA_ "GenSigTimeoutTime_PPIM" SG_ 276 PropulsionSystemActive_114 0;
BA_ "GenSigTimeoutTime_EVCU2" SG_ 276 PropulsionSystemActive_114 0;
BA_ "GenSigTimeoutTime_IDCM" SG_ 276 PropulsionSystemActive_114 0;
BA_ "GenSigTimeoutTime_SGW" SG_ 276 PropulsionSystemActive_114 0;
BA_ "GenSigTimeoutTime_HCP" SG_ 2654486653 SourceNodeIdentifier_1E38407D 0;
BA_ "GenSigTimeoutTime_PPIM" SG_ 2654486653 SourceNodeIdentifier_1E38407D 0;
BA_ "GenSigTimeoutTime_APM2" SG_ 2654486653 SourceNodeIdentifier_1E38407D 0;
BA_ "GenSigTimeoutTime_VDCM" SG_ 2654486653 SourceNodeIdentifier_1E38407D 0;
BA_ "GenSigTimeoutTime_BPCM" SG_ 2654486653 SourceNodeIdentifier_1E38407D 0;
BA_ "GenSigTimeoutTime_EVCU2" SG_ 2654486653 SourceNodeIdentifier_1E38407D 0;
BA_ "GenSigTimeoutTime_IDCM" SG_ 2654486653 SourceNodeIdentifier_1E38407D 0;
BA_ "GenSigTimeoutTime_SGW" SG_ 2654486653 SourceNodeIdentifier_1E38407D 0;
BA_ "GenSigTimeoutTime_HCP" SG_ 2654486653 CBV_bit7_1E38407D 0;
BA_ "GenSigTimeoutTime_PPIM" SG_ 2654486653 CBV_bit7_1E38407D 0;
BA_ "GenSigTimeoutTime_APM2" SG_ 2654486653 CBV_bit7_1E38407D 0;
BA_ "GenSigTimeoutTime_VDCM" SG_ 2654486653 CBV_bit7_1E38407D 0;
BA_ "GenSigTimeoutTime_BPCM" SG_ 2654486653 CBV_bit7_1E38407D 0;
BA_ "GenSigTimeoutTime_EVCU2" SG_ 2654486653 CBV_bit7_1E38407D 0;
BA_ "GenSigTimeoutTime_IDCM" SG_ 2654486653 CBV_bit7_1E38407D 0;
BA_ "GenSigTimeoutTime_SGW" SG_ 2654486653 CBV_bit7_1E38407D 0;
BA_ "GenSigTimeoutTime_HCP" SG_ 2654486653 CBV_bit5_1E38407D 0;
BA_ "GenSigTimeoutTime_PPIM" SG_ 2654486653 CBV_bit5_1E38407D 0;
BA_ "GenSigTimeoutTime_APM2" SG_ 2654486653 CBV_bit5_1E38407D 0;
BA_ "GenSigTimeoutTime_VDCM" SG_ 2654486653 CBV_bit5_1E38407D 0;
BA_ "GenSigTimeoutTime_BPCM" SG_ 2654486653 CBV_bit5_1E38407D 0;
BA_ "GenSigTimeoutTime_EVCU2" SG_ 2654486653 CBV_bit5_1E38407D 0;
BA_ "GenSigTimeoutTime_IDCM" SG_ 2654486653 CBV_bit5_1E38407D 0;
BA_ "GenSigTimeoutTime_SGW" SG_ 2654486653 CBV_bit5_1E38407D 0;
BA_ "GenSigTimeoutTime_HCP" SG_ 2654486653 CBV_bit2_1E38407D 0;
BA_ "GenSigTimeoutTime_PPIM" SG_ 2654486653 CBV_bit2_1E38407D 0;
BA_ "GenSigTimeoutTime_APM2" SG_ 2654486653 CBV_bit2_1E38407D 0;
BA_ "GenSigTimeoutTime_VDCM" SG_ 2654486653 CBV_bit2_1E38407D 0;
BA_ "GenSigTimeoutTime_BPCM" SG_ 2654486653 CBV_bit2_1E38407D 0;
BA_ "GenSigTimeoutTime_EVCU2" SG_ 2654486653 CBV_bit2_1E38407D 0;
BA_ "GenSigTimeoutTime_IDCM" SG_ 2654486653 CBV_bit2_1E38407D 0;
BA_ "GenSigTimeoutTime_SGW" SG_ 2654486653 CBV_bit2_1E38407D 0;
BA_ "GenSigTimeoutTime_HCP" SG_ 2654486653 CBV_bit1_1E38407D 0;
BA_ "GenSigTimeoutTime_PPIM" SG_ 2654486653 CBV_bit1_1E38407D 0;
BA_ "GenSigTimeoutTime_APM2" SG_ 2654486653 CBV_bit1_1E38407D 0;
BA_ "GenSigTimeoutTime_VDCM" SG_ 2654486653 CBV_bit1_1E38407D 0;
BA_ "GenSigTimeoutTime_BPCM" SG_ 2654486653 CBV_bit1_1E38407D 0;
BA_ "GenSigTimeoutTime_EVCU2" SG_ 2654486653 CBV_bit1_1E38407D 0;
BA_ "GenSigTimeoutTime_IDCM" SG_ 2654486653 CBV_bit1_1E38407D 0;
BA_ "GenSigTimeoutTime_SGW" SG_ 2654486653 CBV_bit1_1E38407D 0;
BA_ "GenSigTimeoutTime_HCP" SG_ 2654486640 SourceNodeIdentifier_1E384070 0;
BA_ "GenSigTimeoutTime_PPIM" SG_ 2654486640 SourceNodeIdentifier_1E384070 0;
BA_ "GenSigTimeoutTime_APM2" SG_ 2654486640 SourceNodeIdentifier_1E384070 0;
BA_ "GenSigTimeoutTime_VDCM" SG_ 2654486640 SourceNodeIdentifier_1E384070 0;
BA_ "GenSigTimeoutTime_BPCM" SG_ 2654486640 SourceNodeIdentifier_1E384070 0;
BA_ "GenSigTimeoutTime_EVCU2" SG_ 2654486640 SourceNodeIdentifier_1E384070 0;
BA_ "GenSigTimeoutTime_IDCM" SG_ 2654486640 SourceNodeIdentifier_1E384070 0;
BA_ "GenSigTimeoutTime_SGW" SG_ 2654486640 SourceNodeIdentifier_1E384070 0;
BA_ "GenSigTimeoutTime_HCP" SG_ 2654486640 CBV_bit7_1E384070 0;
BA_ "GenSigTimeoutTime_PPIM" SG_ 2654486640 CBV_bit7_1E384070 0;
BA_ "GenSigTimeoutTime_APM2" SG_ 2654486640 CBV_bit7_1E384070 0;
BA_ "GenSigTimeoutTime_VDCM" SG_ 2654486640 CBV_bit7_1E384070 0;
BA_ "GenSigTimeoutTime_BPCM" SG_ 2654486640 CBV_bit7_1E384070 0;
BA_ "GenSigTimeoutTime_EVCU2" SG_ 2654486640 CBV_bit7_1E384070 0;
BA_ "GenSigTimeoutTime_IDCM" SG_ 2654486640 CBV_bit7_1E384070 0;
BA_ "GenSigTimeoutTime_SGW" SG_ 2654486640 CBV_bit7_1E384070 0;
BA_ "GenSigTimeoutTime_HCP" SG_ 2654486640 CBV_bit5_1E384070 0;
BA_ "GenSigTimeoutTime_PPIM" SG_ 2654486640 CBV_bit5_1E384070 0;
BA_ "GenSigTimeoutTime_APM2" SG_ 2654486640 CBV_bit5_1E384070 0;
BA_ "GenSigTimeoutTime_VDCM" SG_ 2654486640 CBV_bit5_1E384070 0;
BA_ "GenSigTimeoutTime_BPCM" SG_ 2654486640 CBV_bit5_1E384070 0;
BA_ "GenSigTimeoutTime_EVCU2" SG_ 2654486640 CBV_bit5_1E384070 0;
BA_ "GenSigTimeoutTime_IDCM" SG_ 2654486640 CBV_bit5_1E384070 0;
BA_ "GenSigTimeoutTime_SGW" SG_ 2654486640 CBV_bit5_1E384070 0;
BA_ "GenSigTimeoutTime_HCP" SG_ 2654486640 CBV_bit2_1E384070 0;
BA_ "GenSigTimeoutTime_PPIM" SG_ 2654486640 CBV_bit2_1E384070 0;
BA_ "GenSigTimeoutTime_APM2" SG_ 2654486640 CBV_bit2_1E384070 0;
BA_ "GenSigTimeoutTime_VDCM" SG_ 2654486640 CBV_bit2_1E384070 0;
BA_ "GenSigTimeoutTime_BPCM" SG_ 2654486640 CBV_bit2_1E384070 0;
BA_ "GenSigTimeoutTime_EVCU2" SG_ 2654486640 CBV_bit2_1E384070 0;
BA_ "GenSigTimeoutTime_IDCM" SG_ 2654486640 CBV_bit2_1E384070 0;
BA_ "GenSigTimeoutTime_SGW" SG_ 2654486640 CBV_bit2_1E384070 0;
BA_ "GenSigTimeoutTime_HCP" SG_ 2654486640 CBV_bit1_1E384070 0;
BA_ "GenSigTimeoutTime_PPIM" SG_ 2654486640 CBV_bit1_1E384070 0;
BA_ "GenSigTimeoutTime_APM2" SG_ 2654486640 CBV_bit1_1E384070 0;
BA_ "GenSigTimeoutTime_VDCM" SG_ 2654486640 CBV_bit1_1E384070 0;
BA_ "GenSigTimeoutTime_BPCM" SG_ 2654486640 CBV_bit1_1E384070 0;
BA_ "GenSigTimeoutTime_EVCU2" SG_ 2654486640 CBV_bit1_1E384070 0;
BA_ "GenSigTimeoutTime_IDCM" SG_ 2654486640 CBV_bit1_1E384070 0;
BA_ "GenSigTimeoutTime_SGW" SG_ 2654486640 CBV_bit1_1E384070 0;
BA_ "GenSigTimeoutTime_BPCM" SG_ 2654486598 CBV_bit7_1E384046 0;
BA_ "GenSigTimeoutTime_EVCU2" SG_ 2654486598 CBV_bit7_1E384046 0;
BA_ "GenSigTimeoutTime_IDCM" SG_ 2654486598 CBV_bit7_1E384046 0;
BA_ "GenSigTimeoutTime_SGW" SG_ 2654486598 CBV_bit7_1E384046 0;
BA_ "GenSigTimeoutTime_BPCM" SG_ 2654486598 SourceNodeIdentifier_1E384046 0;
BA_ "GenSigTimeoutTime_EVCU2" SG_ 2654486598 SourceNodeIdentifier_1E384046 0;
BA_ "GenSigTimeoutTime_IDCM" SG_ 2654486598 SourceNodeIdentifier_1E384046 0;
BA_ "GenSigTimeoutTime_SGW" SG_ 2654486598 SourceNodeIdentifier_1E384046 0;
BA_ "GenSigTimeoutTime_HCP" SG_ 2654486653 CBV_bit6_PartialNtwInfBit_1E38407D 0;
BA_ "GenSigTimeoutTime_PPIM" SG_ 2654486653 CBV_bit6_PartialNtwInfBit_1E38407D 0;
BA_ "GenSigTimeoutTime_APM2" SG_ 2654486653 CBV_bit6_PartialNtwInfBit_1E38407D 0;
BA_ "GenSigTimeoutTime_VDCM" SG_ 2654486653 CBV_bit6_PartialNtwInfBit_1E38407D 0;
BA_ "GenSigTimeoutTime_BPCM" SG_ 2654486653 CBV_bit6_PartialNtwInfBit_1E38407D 0;
BA_ "GenSigTimeoutTime_EVCU2" SG_ 2654486653 CBV_bit6_PartialNtwInfBit_1E38407D 0;
BA_ "GenSigTimeoutTime_IDCM" SG_ 2654486653 CBV_bit6_PartialNtwInfBit_1E38407D 0;
BA_ "GenSigTimeoutTime_SGW" SG_ 2654486653 CBV_bit6_PartialNtwInfBit_1E38407D 0;
BA_ "GenSigTimeoutTime_HCP" SG_ 2654486653 CBV_bit4_ActiveWakeupBit_1E38407D 0;
BA_ "GenSigTimeoutTime_PPIM" SG_ 2654486653 CBV_bit4_ActiveWakeupBit_1E38407D 0;
BA_ "GenSigTimeoutTime_APM2" SG_ 2654486653 CBV_bit4_ActiveWakeupBit_1E38407D 0;
BA_ "GenSigTimeoutTime_VDCM" SG_ 2654486653 CBV_bit4_ActiveWakeupBit_1E38407D 0;
BA_ "GenSigTimeoutTime_BPCM" SG_ 2654486653 CBV_bit4_ActiveWakeupBit_1E38407D 0;
BA_ "GenSigTimeoutTime_EVCU2" SG_ 2654486653 CBV_bit4_ActiveWakeupBit_1E38407D 0;
BA_ "GenSigTimeoutTime_IDCM" SG_ 2654486653 CBV_bit4_ActiveWakeupBit_1E38407D 0;
BA_ "GenSigTimeoutTime_SGW" SG_ 2654486653 CBV_bit4_ActiveWakeupBit_1E38407D 0;
BA_ "GenSigTimeoutTime_HCP" SG_ 2654486640 CBV_bit3_NMCoordinatorBit_1E384070 0;
BA_ "GenSigTimeoutTime_PPIM" SG_ 2654486640 CBV_bit3_NMCoordinatorBit_1E384070 0;
BA_ "GenSigTimeoutTime_APM2" SG_ 2654486640 CBV_bit3_NMCoordinatorBit_1E384070 0;
BA_ "GenSigTimeoutTime_VDCM" SG_ 2654486640 CBV_bit3_NMCoordinatorBit_1E384070 0;
BA_ "GenSigTimeoutTime_BPCM" SG_ 2654486640 CBV_bit3_NMCoordinatorBit_1E384070 0;
BA_ "GenSigTimeoutTime_EVCU2" SG_ 2654486640 CBV_bit3_NMCoordinatorBit_1E384070 0;
BA_ "GenSigTimeoutTime_IDCM" SG_ 2654486640 CBV_bit3_NMCoordinatorBit_1E384070 0;
BA_ "GenSigTimeoutTime_SGW" SG_ 2654486640 CBV_bit3_NMCoordinatorBit_1E384070 0;
BA_ "GenSigTimeoutTime_HCP" SG_ 2654486640 CBV_bit0_RepeatMessageRequestBit_1E384070 0;
BA_ "GenSigTimeoutTime_PPIM" SG_ 2654486640 CBV_bit0_RepeatMessageRequestBit_1E384070 0;
BA_ "GenSigTimeoutTime_APM2" SG_ 2654486640 CBV_bit0_RepeatMessageRequestBit_1E384070 0;
BA_ "GenSigTimeoutTime_VDCM" SG_ 2654486640 CBV_bit0_RepeatMessageRequestBit_1E384070 0;
BA_ "GenSigTimeoutTime_BPCM" SG_ 2654486640 CBV_bit0_RepeatMessageRequestBit_1E384070 0;
BA_ "GenSigTimeoutTime_EVCU2" SG_ 2654486640 CBV_bit0_RepeatMessageRequestBit_1E384070 0;
BA_ "GenSigTimeoutTime_IDCM" SG_ 2654486640 CBV_bit0_RepeatMessageRequestBit_1E384070 0;
BA_ "GenSigTimeoutTime_SGW" SG_ 2654486640 CBV_bit0_RepeatMessageRequestBit_1E384070 0;
BA_ "GenSigTimeoutTime_HCP" SG_ 2654486653 CBV_bit3_NMCoordinatorBit_1E38407D 0;
BA_ "GenSigTimeoutTime_PPIM" SG_ 2654486653 CBV_bit3_NMCoordinatorBit_1E38407D 0;
BA_ "GenSigTimeoutTime_APM2" SG_ 2654486653 CBV_bit3_NMCoordinatorBit_1E38407D 0;
BA_ "GenSigTimeoutTime_VDCM" SG_ 2654486653 CBV_bit3_NMCoordinatorBit_1E38407D 0;
BA_ "GenSigTimeoutTime_BPCM" SG_ 2654486653 CBV_bit3_NMCoordinatorBit_1E38407D 0;
BA_ "GenSigTimeoutTime_EVCU2" SG_ 2654486653 CBV_bit3_NMCoordinatorBit_1E38407D 0;
BA_ "GenSigTimeoutTime_IDCM" SG_ 2654486653 CBV_bit3_NMCoordinatorBit_1E38407D 0;
BA_ "GenSigTimeoutTime_SGW" SG_ 2654486653 CBV_bit3_NMCoordinatorBit_1E38407D 0;
BA_ "GenSigTimeoutTime_HCP" SG_ 2654486653 CBV_bit0_RepeatMessageRequestBit_1E38407D 0;
BA_ "GenSigTimeoutTime_PPIM" SG_ 2654486653 CBV_bit0_RepeatMessageRequestBit_1E38407D 0;
BA_ "GenSigTimeoutTime_APM2" SG_ 2654486653 CBV_bit0_RepeatMessageRequestBit_1E38407D 0;
BA_ "GenSigTimeoutTime_VDCM" SG_ 2654486653 CBV_bit0_RepeatMessageRequestBit_1E38407D 0;
BA_ "GenSigTimeoutTime_BPCM" SG_ 2654486653 CBV_bit0_RepeatMessageRequestBit_1E38407D 0;
BA_ "GenSigTimeoutTime_EVCU2" SG_ 2654486653 CBV_bit0_RepeatMessageRequestBit_1E38407D 0;
BA_ "GenSigTimeoutTime_IDCM" SG_ 2654486653 CBV_bit0_RepeatMessageRequestBit_1E38407D 0;
BA_ "GenSigTimeoutTime_SGW" SG_ 2654486653 CBV_bit0_RepeatMessageRequestBit_1E38407D 0;
BA_ "GenSigTimeoutTime_HCP" SG_ 2654486640 CBV_bit6_PartialNtwInfBit_1E384070 0;
BA_ "GenSigTimeoutTime_PPIM" SG_ 2654486640 CBV_bit6_PartialNtwInfBit_1E384070 0;
BA_ "GenSigTimeoutTime_APM2" SG_ 2654486640 CBV_bit6_PartialNtwInfBit_1E384070 0;
BA_ "GenSigTimeoutTime_VDCM" SG_ 2654486640 CBV_bit6_PartialNtwInfBit_1E384070 0;
BA_ "GenSigTimeoutTime_BPCM" SG_ 2654486640 CBV_bit6_PartialNtwInfBit_1E384070 0;
BA_ "GenSigTimeoutTime_EVCU2" SG_ 2654486640 CBV_bit6_PartialNtwInfBit_1E384070 0;
BA_ "GenSigTimeoutTime_IDCM" SG_ 2654486640 CBV_bit6_PartialNtwInfBit_1E384070 0;
BA_ "GenSigTimeoutTime_SGW" SG_ 2654486640 CBV_bit6_PartialNtwInfBit_1E384070 0;
BA_ "GenSigTimeoutTime_HCP" SG_ 2654486640 CBV_bit4_ActiveWakeupBit_1E384070 0;
BA_ "GenSigTimeoutTime_PPIM" SG_ 2654486640 CBV_bit4_ActiveWakeupBit_1E384070 0;
BA_ "GenSigTimeoutTime_APM2" SG_ 2654486640 CBV_bit4_ActiveWakeupBit_1E384070 0;
BA_ "GenSigTimeoutTime_VDCM" SG_ 2654486640 CBV_bit4_ActiveWakeupBit_1E384070 0;
BA_ "GenSigTimeoutTime_BPCM" SG_ 2654486640 CBV_bit4_ActiveWakeupBit_1E384070 0;
BA_ "GenSigTimeoutTime_EVCU2" SG_ 2654486640 CBV_bit4_ActiveWakeupBit_1E384070 0;
BA_ "GenSigTimeoutTime_IDCM" SG_ 2654486640 CBV_bit4_ActiveWakeupBit_1E384070 0;
BA_ "GenSigTimeoutTime_SGW" SG_ 2654486640 CBV_bit4_ActiveWakeupBit_1E384070 0;
VAL_ 2654339170 GenericFailSts_FD03_HCP 0 "No_Fail_Present" 1 "Fail_Present";
VAL_ 2654339170 EOL_FD03_HCP 0 "No_EOL_Programming" 1 "EOL_Programming";
VAL_ 2654339170 CurrentFailSts_FD03_HCP 0 "No_Fail_Present" 1 "Fail_Present";
VAL_ 1835 HVBatCellVoltage_Cell027 8191 "SNA";
VAL_ 1835 HVBatCellVoltage_Cell026 8191 "SNA";
VAL_ 1835 HVBatCellVoltage_Cell025 8191 "SNA";
VAL_ 1835 HVBatCellVoltage_Cell024 8191 "SNA";
VAL_ 1835 HVBatCellVoltage_Cell023 8191 "SNA";
VAL_ 1835 HVBatCellVoltage_Cell022 8191 "SNA";
VAL_ 1835 HVBatCellVoltage_Cell021 8191 "SNA";
VAL_ 1835 HVBatCellVoltage_Cell020 8191 "SNA";
VAL_ 1835 HVBatCellVoltage_Cell019 8191 "SNA";
VAL_ 1835 HVBatCellVoltage_Cell018 8191 "SNA";
VAL_ 1835 HVBatCellVoltage_Cell017 8191 "SNA";
VAL_ 1835 HVBatCellVoltage_Cell016 8191 "SNA";
VAL_ 1835 HVBatCellVoltage_Cell015 8191 "SNA";
VAL_ 1835 HVBatCellVoltage_Cell014 8191 "SNA";
VAL_ 1835 HVBatCellVoltage_Cell013 8191 "SNA";
VAL_ 1835 HVBatCellVoltage_Cell012 8191 "SNA";
VAL_ 1835 HVBatCellVoltage_Cell011 8191 "SNA";
VAL_ 1835 HVBatCellVoltage_Cell010 8191 "SNA";
VAL_ 1835 HVBatCellVoltage_Cell009 8191 "SNA";
VAL_ 1835 HVBatCellVoltage_Cell008 8191 "SNA";
VAL_ 1835 HVBatCellVoltage_Cell007 8191 "SNA";
VAL_ 1835 HVBatCellVoltage_Cell006 8191 "SNA";
VAL_ 1835 HVBatCellVoltage_Cell005 8191 "SNA";
VAL_ 1835 HVBatCellVoltage_Cell004 8191 "SNA";
VAL_ 1835 HVBatCellVoltage_Cell003 8191 "SNA";
VAL_ 1835 HVBatCellVoltage_Cell002 8191 "SNA";
VAL_ 1835 HVBatCellVoltage_Cell001 8191 "SNA";
VAL_ 1035 RadFanReq 127 "SNA";
VAL_ 1035 EngCltTmpV 0 "False" 1 "True";
VAL_ 1035 EngCltTmp 255 "SNA";
VAL_ 750 Battery_Volt_1 511 "SNA";
VAL_ 1436 Blower_Speed 511 "SNA";
VAL_ 276 HEV_ESS_Mode 0 "EngOff" 1 "IS" 2 "STPA" 3 "EFA" 4 "ETS" 5 "PT" 6 "DFA" 7 "SPPA" 8 "SF" 9 "CT" 15 "SNA";
VAL_ 262 PowertrainPrplsnActv 0 "Off" 1 "Active";
VAL_ 262 EngineSpeed_W 16383 "SNA";
VAL_ 258 VehicleSpeedVSOSig 8191 "SNA";
VAL_ 1579 HVBatteryVoltage_MinCal 511 "SNA";
VAL_ 1579 HVBatteryVoltage_MaxCal 511 "SNA";
VAL_ 1579 HVBatteryCurrent_MaxCal 255 "SNA";
VAL_ 1579 ChargeSystemFaultReason 0 "No_Failure" 1 "Failure1" 2 "Failure2" 3 "Failure3" 4 "Failure4" 5 "Failure5" 6 "Failure6" 7 "Failure7" 8 "Failure8" 9 "Failure9" 10 "Failure10" 11 "Failure11" 12 "Failure12" 13 "Failure13" 14 "Failure14" 15 "Failure15" 16 "Failure16" 17 "Failure17" 18 "Failure18" 19 "Failure19" 20 "Failure20" 21 "Failure21" 22 "Failure22" 23 "Failure23" 24 "Failure24" 25 "Failure25" 26 "Failure26" 27 "Failure27" 28 "Failure28" 29 "Failure29" 30 "Failure30" 31 "Failure31" 32 "Failure32" 33 "Failure33" 34 "Failure34" 35 "Failure35" 36 "Failure36" 37 "Failure37" 38 "Failure38" 39 "Failure39" 40 "Failure40" 41 "Failure41" 42 "Failure42" 43 "Failure43" 44 "Failure44" 45 "Failure45" 46 "Failure46" 47 "Failure47" 48 "Failure48" 49 "Failure49" 50 "Failure50" 51 "Failure51" 52 "Failure52" 53 "Failure53" 54 "Failure54" 55 "Failure55" 56 "Failure56" 57 "Failure57" 58 "Failure58" 59 "Failure59" 60 "Failure60" 61 "Failure61" 62 "Failure62" 63 "Failure63" 64 "Failure64" 65 "Failure65" 66 "Failure66" 67 "Failure67" 68 "Failure68" 69 "Failure69" 70 "Failure70" 71 "Failure71" 72 "Failure72" 73 "Failure73" 74 "Failure74" 75 "Failure75" 76 "Failure76" 77 "Failure77" 78 "Failure78" 79 "Failure79" 80 "Failure80" 81 "Failure81" 82 "Failure82" 83 "Failure83" 84 "Failure84" 85 "Failure85" 86 "Failure86" 87 "Failure87" 88 "Failure88" 89 "Failure89" 90 "Failure90" 91 "Failure91" 92 "Failure92" 93 "Failure93" 94 "Failure94" 95 "Failure95" 96 "Failure96" 97 "Failure97" 98 "Failure98" 99 "Failure99" 100 "Failure100" 101 "Failure101" 102 "Failure102" 103 "Failure103" 104 "Failure104" 105 "Failure105" 106 "Failure106" 107 "Failure107" 108 "Failure108" 109 "Failure109" 110 "Failure110" 111 "Failure111" 112 "Failure112" 113 "Failure113" 114 "Failure114" 115 "Failure115" 116 "Failure116" 117 "Failure117" 118 "Failure118" 119 "Failure119" 120 "Failure120" 121 "Failure121" 122 "Failure122" 123 "Failure123" 124 "Failure124" 125 "Failure125" 126 "Failure126" 127 "Failure127" 128 "Failure128" 129 "Failure129" 130 "Failure130" 131 "Failure131" 132 "Failure132" 133 "Failure133" 134 "Failure134" 135 "Failure135" 136 "Failure136" 137 "Failure137" 138 "Failure138" 139 "Failure139" 140 "Failure140" 141 "Failure141" 142 "Failure142" 143 "Failure143" 144 "Failure144" 145 "Failure145" 146 "Failure146" 147 "Failure147" 148 "Failure148" 149 "Failure149" 150 "Failure150" 151 "Failure151" 152 "Failure152" 153 "Failure153" 154 "Failure154" 155 "Failure155" 156 "Failure156" 157 "Failure157" 158 "Failure158" 159 "Failure159" 160 "Failure160" 161 "Failure161" 162 "Failure162" 163 "Failure163" 164 "Failure164" 165 "Failure165" 166 "Failure166" 167 "Failure167" 168 "Failure168" 169 "Failure169" 170 "Failure170" 171 "Failure171" 172 "Failure172" 173 "Failure173" 174 "Failure174" 175 "Failure175" 176 "Failure176" 177 "Failure177" 178 "Failure178" 179 "Failure179" 180 "Failure180" 181 "Failure181" 182 "Failure182" 183 "Failure183" 184 "Failure184" 185 "Failure185" 186 "Failure186" 187 "Failure187" 188 "Failure188" 189 "Failure189" 190 "Failure190" 191 "Failure191" 192 "Failure192" 193 "Failure193" 194 "Failure194" 195 "Failure195" 196 "Failure196" 197 "Failure197" 198 "Failure198" 199 "Failure199" 200 "Failure200" 201 "Failure201" 202 "Failure202" 203 "Failure203" 204 "Failure204" 205 "Failure205" 206 "Failure206" 207 "Failure207" 208 "Failure208" 209 "Failure209" 210 "Failure210" 211 "Failure211" 212 "Failure212" 213 "Failure213" 214 "Failure214" 215 "Failure215" 216 "Failure216" 217 "Failure217" 218 "Failure218" 219 "Failure219" 220 "Failure220" 221 "Failure221" 222 "Failure222" 223 "Failure223" 224 "Failure224" 225 "Failure225" 226 "Failure226" 227 "Failure227" 228 "Failure228" 229 "Failure229" 230 "Failure230" 231 "Failure231" 232 "Failure232" 233 "Failure233" 234 "Failure234" 235 "Failure235" 236 "Failure236" 237 "Failure237" 238 "Failure238" 239 "Failure239" 240 "Failure240" 241 "Failure241" 242 "Failure242" 243 "Failure243" 244 "Failure244" 245 "Failure245" 246 "Failure246" 247 "Failure247" 248 "Failure248" 249 "Failure249" 250 "Failure250" 251 "Failure251" 252 "Failure252" 253 "Failure253" 254 "Failure254" 255 "SNA";
VAL_ 1579 ACCurrent_MaxCal 511 "SNA";
VAL_ 478 LVDC_VoltageSetpoint 255 "SNA";
VAL_ 478 LVDC_SystemVoltageAct 511 "SNA";
VAL_ 478 LVDC_CurrentSetpoint 511 "SNA";
VAL_ 478 HVInverterVoltage_Rational 511 "SNA";
VAL_ 478 HVDC_VoltageSetpoint 511 "SNA";
VAL_ 478 HVDC_CurrentSetpoint 255 "SNA";
VAL_ 478 EchargeSOCRange_ePT 127 "SNA";
VAL_ 1374 HVBatPackVoltage_MaxAllowedV 0 "Valid" 1 "Not_Valid";
VAL_ 1374 HVBatCellVoltage_MinAllowedV 0 "Valid" 1 "Not_Valid";
VAL_ 1374 HVBatCellVoltage_MinAllowed 4095 "SNA";
VAL_ 1374 HVBatCellVoltage_MaxAllowedV 0 "Valid" 1 "Not_Valid";
VAL_ 1374 HVBatCellVoltage_MaxAllowed 4095 "SNA";
VAL_ 1374 HVBatCellVoltage_LowThreshold 8191 "SNA";
VAL_ 1374 HVBatCellVoltage_HighThreshold 8191 "SNA";
VAL_ 1374 HVBatCapacity_AmpHrV 0 "Valid" 1 "Not_Valid";
VAL_ 1374 HVBatCapacity_AmpHr 2047 "SNA";
VAL_ 1578 OBC_IdleTimeSec 65535 "SNA";
VAL_ 1578 OBC_IdleTimeMin 65535 "SNA";
VAL_ 1578 OBC_ChargeTimeSec 65535 "SNA";
VAL_ 1578 OBC_ChargeTimeMin 65535 "SNA";
VAL_ 1578 Charging_WHr 65535 "SNA";
VAL_ 1372 OBC_Temp4 255 "SNA";
VAL_ 1372 OBC_Temp3 255 "SNA";
VAL_ 1372 OBC_Temp2 255 "SNA";
VAL_ 1372 OBC_Temp1 255 "SNA";
VAL_ 1460 FOTA_Status 0 "No FOTA Event" 1 "Downloading Package from Backend" 2 "Passing Images to Big Target ECUs" 3 "Waiting for HMI Acceptance" 4 "Installing FOTA Updated" 5 "Successful FOTA Update" 6 "FOTA Failure Rollback Successful" 7 "FOTA Failure Complete" 8 "Build Vehicle Library" 9 "Check Campaign Availability" 10 "Check Download Conditions" 11 "Validate Vehicle Package" 12 "Double Check Manifest" 13 "Initiate Authenticated Diagnostic session" 14 "Ready_State" 15 "Rollback";
VAL_ 276 PropulsionSystemActive_114 0 "Not_Active" 1 "Active";
VAL_ 2654339170 WakeupSource_FD03_HCP 0 "No_Wakeup";
VAL_ 2654339170 PreviousCanNMState_FD03_HCP 0 "Uninitialized State" 1 "Bus-Sleep State" 2 "Prepare-Bus State" 3 "Ready-Sleep State" 4 "Normal Operation State" 5 "Repeat Message State" 6 "Synchronize State" 7 "Offline State";
VAL_ 2654339170 DES_FD03_HCP 0 "Error_Active_state" 1 "Error_passive_warning_state" 2 "Bus_off_state" 3 "Not_used";
VAL_ 2654339170 CurrentCanNMState_FD03_HCP 0 "Uninitialized State" 1 "Bus-Sleep State" 2 "Prepare-Bus State" 3 "Ready-Sleep State" 4 "Normal Operation State" 5 "Repeat Message State" 6 "Synchronize State" 7 "Offline State";
VAL_ 1579 ChargingLevel 0 "Default_NoLevel" 1 "Level_1_AC" 2 "Level_2_AC" 3 "Level_3_AC" 4 "Level_1_DC" 5 "Level_2_DC" 6 "PlugInNotDet" 7 "PPI_1_No_Drive" 8 "PPI_2_OK_Drive" 15 "SNA";
VAL_ 478 OBC_ModeRequest 0 "IDLE" 1 "HEATER" 2 "CHARGE" 3 "AC_PNL" 4 "AC_GRD_Sync" 5 "AC_GRD_Synth" 7 "SNA";
VAL_ 478 OBC_ControlMethod 0 "CURRENT" 1 "VOLTAGE" 2 "POWER" 3 "SNA";
VAL_ 478 MainHV_ContactorCommand 0 "OPN" 1 "CLS" 2 "IMPCT_OPN" 3 "FAST_OPN" 7 "INV";
VAL_ 478 J1772_CloseS2 0 "OPN" 1 "CLS";
VAL_ 478 HVInverterVoltage_RationalV 0 "Valid" 1 "Not_Valid";
VAL_ 478 HVBatCoolantLevelLow 0 "FALSE" 1 "TRUE" 3 "SNA";
VAL_ 478 DCDC_OperationModeEnable 0 "Default" 1 "Buck_CV" 2 "Buck_CC" 3 "Buck_CP" 4 "Buck_Special" 5 "Boost" 6 "Precharge" 7 "Discharge" 8 "Off" 15 "SNA";
VAL_ 478 ClearLegislatedDiagInfo 0 "FALSE" 1 "TRUE";
VAL_ 1374 HVBatRemainingAhCapacity 2047 "SNA";
VAL_ 1374 HVBatDischargeAmpHrs 16777215 "SNA";
VAL_ 1374 HVBatChargeAmpHrs 16777215 "SNA";
VAL_ 1374 BSGPackVoltage_MaxAllowed 127 "SNA";
VAL_ 1038 Precharge_Closed 0 "FALSE" 1 "TRUE";
VAL_ 1038 Positive_Main_Closed 0 "FALSE" 1 "TRUE";
VAL_ 1038 Negative_Main_Closed 0 "FALSE" 1 "TRUE";
VAL_ 1038 HBCO_TempSensorRationality 0 "FALSE" 1 "TRUE";
VAL_ 1038 HBCO_Sensor_Fault 0 "FALSE" 1 "TRUE";
VAL_ 1038 HBCO_PackUndertemp 0 "FALSE" 1 "TRUE";
VAL_ 1038 HBCO_PackOvertemp 0 "FALSE" 1 "TRUE";
VAL_ 1038 HBCO_OverCurrent 0 "FALSE" 1 "TRUE";
VAL_ 1038 HBCO_Micro_Failure 0 "FALSE" 1 "TRUE";
VAL_ 1038 HBCO_Main_Fuse_Failure 0 "FALSE" 1 "TRUE";
VAL_ 1038 HBCO_Isolation_Fault 0 "FALSE" 1 "TRUE";
VAL_ 1038 HBCO_Internal_CommFault 0 "FALSE" 1 "TRUE";
VAL_ 1038 HBCO_Impact_Detected 0 "FALSE" 1 "TRUE";
VAL_ 1038 HBCO_HVIL_Failure 0 "FALSE" 1 "TRUE";
VAL_ 1038 HBCO_External_CommFault 0 "FALSE" 1 "TRUE";
VAL_ 1038 HBCO_CellUndervoltage 0 "FALSE" 1 "TRUE";
VAL_ 1038 HBCO_CellOvervoltage 0 "FALSE" 1 "TRUE";
VAL_ 1038 HBCO_12V_Low 0 "FALSE" 1 "TRUE";
VAL_ 1038 HBCO_12V_High 0 "FALSE" 1 "TRUE";
VAL_ 1038 HBCNC_TempSensorRationality 0 "FALSE" 1 "TRUE";
VAL_ 1038 HBCNC_SOH_Failure 0 "FALSE" 1 "TRUE";
VAL_ 1038 HBCNC_Sensor_Failure 0 "FALSE" 1 "TRUE";
VAL_ 1038 HBCNC_Precharge_Failure 0 "FALSE" 1 "TRUE";
VAL_ 1038 HBCNC_PackUndervoltage 0 "FALSE" 1 "TRUE";
VAL_ 1038 HBCNC_PackUndertemp 0 "FALSE" 1 "TRUE";
VAL_ 1038 HBCNC_PackOvervoltage 0 "FALSE" 1 "TRUE";
VAL_ 1038 HBCNC_PackOvertemp 0 "FALSE" 1 "TRUE";
VAL_ 1038 HBCNC_Micro_Failure 0 "FALSE" 1 "TRUE";
VAL_ 1038 HBCNC_Main_Fuse_Failure 0 "FALSE" 1 "TRUE";
VAL_ 1038 HBCNC_Isolation_Fault 0 "FALSE" 1 "TRUE";
VAL_ 1038 HBCNC_Internal_CommFault 0 "FALSE" 1 "TRUE";
VAL_ 1038 HBCNC_Impact_Detected 0 "FALSE" 1 "TRUE";
VAL_ 1038 HBCNC_External_CommFault 0 "FALSE" 1 "TRUE";
VAL_ 1038 HBCNC_EEPROM_Fault 0 "FALSE" 1 "TRUE";
VAL_ 1038 HBCNC_Contactors_Welded 0 "FALSE" 1 "TRUE";
VAL_ 1038 HBCNC_CellUndervoltage 0 "FALSE" 1 "TRUE";
VAL_ 1038 HBCNC_CellOvervoltage 0 "FALSE" 1 "TRUE";
VAL_ 1038 HBCNC_12V_Low 0 "FALSE" 1 "TRUE";
VAL_ 1038 HBCNC_12V_High 0 "FALSE" 1 "TRUE";
VAL_ 1038 BPCM_DTC_Status6 0 "Not_Supported" 1 "Critically_Disabled" 2 "No_Status" 3 "Diag_Passed" 4 "Diag_Failed" 5 "Reset_DTC" 6 "Unused" 7 "SNA";
VAL_ 1038 BPCM_DTC_Status5 0 "Not_Supported" 1 "Critically_Disabled" 2 "No_Status" 3 "Diag_Passed" 4 "Diag_Failed" 5 "Reset_DTC" 6 "Unused" 7 "SNA";
VAL_ 1038 BPCM_DTC_Status4 0 "Not_Supported" 1 "Critically_Disabled" 2 "No_Status" 3 "Diag_Passed" 4 "Diag_Failed" 5 "Reset_DTC" 6 "Unused" 7 "SNA";
VAL_ 1038 BPCM_DTC_Status3 0 "Not_Supported" 1 "Critically_Disabled" 2 "No_Status" 3 "Diag_Passed" 4 "Diag_Failed" 5 "Reset_DTC" 6 "Unused" 7 "SNA";
VAL_ 1038 BPCM_DTC_Status2 0 "Not_Supported" 1 "Critically_Disabled" 2 "No_Status" 3 "Diag_Passed" 4 "Diag_Failed" 5 "Reset_DTC" 6 "Unused" 7 "SNA";
VAL_ 1038 BPCM_DTC_Status1 0 "Not_Supported" 1 "Critically_Disabled" 2 "No_Status" 3 "Diag_Passed" 4 "Diag_Failed" 5 "Reset_DTC" 6 "Unused" 7 "SNA";
VAL_ 1038 BPCM_CalibrationID 63 "SNA";
VAL_ 2654339223 WakeupSource_FD11_APM2 0 "No_Wakeup" 1 "IGN_ON" 129 "FD1_Psv_WU" 130 "FD2_Psv_WU" 131 "FD3_Psv_WU" 132 "FD4_Psv_WU" 133 "FD5_Psv_WU" 134 "FD6_Psv_WU" 135 "FD7_Psv_WU" 136 "FD8_Psv_WU" 137 "FD9_Psv_WU" 138 "FD10_Psv_WU" 139 "FD11_Psv_WU" 140 "FD12_Psv_WU" 141 "FD13_Psv_WU" 142 "FD14_Psv_WU" 143 "FD15_Psv_WU" 144 "FD16_Psv_WU" 145 "FD17_Psv_WU" 146 "FD18_Psv_WU" 147 "FD19_Psv_WU" 148 "FD20_Psv_WU" 149 "FD21_Psv_WU" 150 "FD22_Psv_WU" 151 "FD23_Psv_WU" 152 "FD24_Psv_WU" 153 "FD25_Psv_WU" 154 "FD26_Psv_WU" 155 "FD27_Psv_WU" 156 "FD28_Psv_WU" 157 "FD29_Psv_WU" 158 "BHCAN_Psv_WU" 159 "CCAN_Psv_WU" 254 "WUSource_Not_Listed";
VAL_ 2654339223 PreviousCanNMState_FD11_APM2 0 "Uninitialized State" 1 "Bus-Sleep State" 2 "Prepare-Bus State" 3 "Ready-Sleep State" 4 "Normal Operation State" 5 "Repeat Message State" 6 "Synchronize State" 7 "Offline State";
VAL_ 2654339223 GenericFailSts_FD11_APM2 0 "No_Fail_Present" 1 "Fail_Present";
VAL_ 2654339223 EOL_FD11_APM2 0 "No_EOL_Programming" 1 "EOL_Programming";
VAL_ 2654339223 DES_FD11_APM2 0 "Error_Active_state" 1 "Error_passive_warning_state" 2 "Bus_off_state" 3 "Not_used";
VAL_ 2654339223 CurrentFailSts_FD11_APM2 0 "No_Fail_Present" 1 "Fail_Present";
VAL_ 2654339223 CurrentCanNMState_FD11_APM2 0 "Uninitialized State" 1 "Bus-Sleep State" 2 "Prepare-Bus State" 3 "Ready-Sleep State" 4 "Normal Operation State" 5 "Repeat Message State" 6 "Synchronize State" 7 "Offline State";
VAL_ 1579 OBCM_PLUG_STS 0 "NOT_PLUG_IN" 1 "PLUG_IN";
VAL_ 478 OBC_OperativeModeReq 0 "IDLE" 1 "HEATER" 2 "CHARGE" 3 "Discharge" 4 "AC_GRD_Sync" 5 "AC_GRD_Synth" 6 "CHARGE_INTERRUPTED" 7 "NOT_CHARGING" 15 "SNA";
VAL_ 478 HV_Volt_Min_Thrsh 2047 "SNA";
VAL_ 478 HV_Volt_Max_Thrsh 2047 "SNA";
VAL_ 478 DC_Curr_Max_Thrsh 1023 "SNA";
VAL_ 478 ChargeEnable 0 "Charge_Not_Enabled" 1 "Charge_Enabled" 3 "SNA";
VAL_ 478 AC_Curr_Min_Thrsh 1023 "SNA";
VAL_ 478 AC_Curr_Max_Thrsh 1023 "SNA";
VAL_ 1578 OnboardChargerReady 0 "WU_FLT" 1 "OFF" 2 "ON" 3 "SNA";
VAL_ 1578 OnboardChargerMode 0 "IDLE" 1 "HEATER" 2 "CHARGE" 3 "Discharge" 4 "AC_GRD" 5 "UTC" 6 "STOP" 7 "FORCED_SHUTDOWN" 8 "CHARGE_INTERRUPTED" 9 "NOT_CHARGING";
VAL_ 1578 OBC_WakeReason 0 "NOT_DETECTED" 1 "Master_WU" 2 "EVSE_PlugIn" 3 "Pilot_PWM" 4 "Prox_in" 5 "EVSE_UnPlug" 6 "s3_open" 7 "BPCM_WU";
VAL_ 1578 OBC_GenericFailSts 0 "Fail_Not_Present" 1 "Fail_Present";
VAL_ 1578 OBC_FaultReason 0 "No_Fault" 1 "COMM_FAULT" 2 "EVSE_InputCirFault" 3 "Batt_12vFault" 4 "OBCM_LV_Fault" 5 "OBCM_HV_Fault" 6 "Extern_Dev_Fault" 7 "WakeupCircuitFault" 8 "Impact" 9 "DischargeFault" 127 "SNA";
VAL_ 1578 OBC_ChargingFaultSts 0 "No_Performed" 1 "No_Fault" 2 "OBCM_ECU_HW_Error" 3 "OBCM_Modules_Error" 4 "Gnd_Fault" 5 "Temperature_Error" 6 "OverCurrent_Error" 7 "OverVoltage_Error";
VAL_ 1578 ACplug_PwrMax 65535 "SNA";
VAL_ 1038 BPCM_Odometer 16777215 "SNA";
VAL_ 1579 VDCM_UDCChrgr 65535 "SNA";
VAL_ 1579 VDCM_IDCChrgr 65535 "SNA";
VAL_ 1579 ChargeSystemSts 0 "NotCharging" 1 "Charging" 2 "ChargeInterrupted" 3 "ChargeComplete" 4 "ChargeError" 7 "SNA";
VAL_ 1579 ChargeSystemFault 0 "No_Fail" 1 "Fail";
VAL_ 478 VDCM_StsWldgReq 0 "No_WeldingCheck_Req" 1 "WeldingCheck_Req";
VAL_ 478 VDCM_SessnStopReq 0 "No_SessStop_Req" 1 "SessStop_Req";
VAL_ 2654486640 CBV_bit0_RepeatMessageRequestBit_1E384070 0 "Repeat_Message_State_not_requested" 1 "Repeat_Message_State_requested";
VAL_ 2654486640 CBV_bit3_NMCoordinatorBit_1E384070 0 "Start_of_synchronized_shutdown_is_not_requested_by_main_coordinator" 1 "Start_of_synchronized_shutdown_is_requested_by_main_coordinator";
VAL_ 2654486640 CBV_bit4_ActiveWakeupBit_1E384070 0 "PassiveWakeup" 1 "ActiveWakeup";
VAL_ 2654486640 CBV_bit6_PartialNtwInfBit_1E384070 0 "NM_PDU_contains_no_Partial_Network_request_information" 1 "NM_PDU_contains_Partial_Network_request_information";
VAL_ 2654486653 CBV_bit0_RepeatMessageRequestBit_1E38407D 0 "Repeat Message State not requested" 1 "Repeat Message State requested";
VAL_ 2654486653 CBV_bit3_NMCoordinatorBit_1E38407D 0 "Start of synchronized shutdown is not requested by main coordinator" 1 "Start of synchronized shutdown is requested by main coordinator";
VAL_ 2654486653 CBV_bit4_ActiveWakeupBit_1E38407D 0 "PassiveWakeup" 1 "ActiveWakeup";
VAL_ 2654486653 CBV_bit6_PartialNtwInfBit_1E38407D 0 "NM PDU contains no Partial Network request information" 1 "NM PDU contains Partial Network request information";
VAL_ 2654486626 CBV_bit0_RepeatMessageRequestBit_1E384062 0 "Repeat Message State not requested" 1 "Repeat Message State requested";
VAL_ 2654486626 CBV_bit3_NMCoordinatorBit_1E384062 0 "Start of synchronized shutdown is not requested by main coordinator" 1 "Start of synchronized shutdown is requested by main coordinator";
VAL_ 2654486626 CBV_bit4_ActiveWakeupBit_1E384062 0 "PassiveWakeup" 1 "ActiveWakeup";
VAL_ 2654486626 CBV_bit6_PartialNtwInfBit_1E384062 0 "NM PDU contains no Partial Network request information" 1 "NM PDU contains Partial Network request information";
VAL_ 2654486598 CBV_bit0_RepeatMessageRequestBit_1E384046 0 "Repeat Message State not requested" 1 "Repeat Message State requested";
VAL_ 2654486598 CBV_bit3_NMCoordinatorBit_1E384046 0 "Start of synchronized shutdown is not requested by main coordinator" 1 "Start of synchronized shutdown is requested by main coordinator";
VAL_ 2654486598 CBV_bit4_ActiveWakeupBit_1E384046 0 "PassiveWakeup" 1 "ActiveWakeup";
VAL_ 2654486598 CBV_bit6_PartialNtwInfBit_1E384046 0 "NM PDU contains no Partial Network request information" 1 "NM PDU contains Partial Network request information";
VAL_ 478 VDCM_StsSWWldgReq 0 "No_SWWeldingCheck_Req" 1 "SWWeldingCheck_Req";
VAL_ 1578 OBCM_PrechargeSts 0 "Not_Requested" 1 "Ongoing" 2 "Completed" 3 "Fail";
VAL_ 1578 ChrgFailSts 0 "No_Fault" 1 "Flt_charging_allowed" 2 "Flt_charging_inhibited" 3 "Flt_charging_terminated" 4 "Flt_AC_failure_DC_chg_allwd" 7 "SNA";
VAL_ 2654339223 StayActiveSource_FD11_APM2 0 "CANNM_Ready_Sleep" 1 "IGN_ON" 2 "NonDefault_Diag" 4 "ING_OFF_NormSt_RptSt" 1073741824 "SASource_Not_Listed";
SIG_GROUP_ 1578 HV_CHARGER2_Pkt 1 : OBC_IdleTimeSec OBC_IdleTimeMin OBC_ChargeTimeSec OBC_ChargeTimeMin Charging_WHr OnboardChargerReady OnboardChargerMode OBC_WakeReason OBC_GenericFailSts OBC_FaultReason OBC_EVServiceLampOn OBC_EVServiceLampFlash OBC_CurrentFailureSts OBC_ChargingFaultSts OBC_ChargeFailure OBC_CaptureEnvironmentData ACplug_PwrMax OBC_Pilot OBC_Prox OBCM_PrechargeSts ChrgFailSts MessageCounter_HV_CHARGER2 CRC_HV_CHARGER2;
SIG_GROUP_ 276 HYBRID_POWERTRAIN1_Pkt 1 : HEV_ESS_Mode PropulsionSystemActive_114;
SIG_GROUP_ 1579 HYBRID_CHARGING_STATUS_Pkt 1 : HVBatteryVoltage_MinCal HVBatteryVoltage_MaxCal HVBatteryCurrent_MaxCal ChargeSystemFaultReason ACCurrent_MaxCal ChargingLevel OBCM_PLUG_STS VDCM_UDCChrgr VDCM_IDCChrgr ChargeSystemSts ChargeSystemFault CRC_HYBRID_CHARGING_STATUS MessageCounter_HYBRID_CHARGING__62B;
SIG_GROUP_ 478 HYBRID_CHARGING_COMMAND_Pkt 1 : LVDC_VoltageSetpoint LVDC_SystemVoltageAct LVDC_CurrentSetpoint HVInverterVoltage_Rational HVDC_VoltageSetpoint HVDC_CurrentSetpoint EchargeSOCRange_ePT CRC_HYBRID_CHARGING_COMMAND VoltageRequest OBC_ModeRequest OBC_ControlMethod MainHV_ContactorCommand J1772_CloseS2 HVInverterVoltage_RationalV HVBatCoolantLevelLow DCDC_OperationModeEnable ClearLegislatedDiagInfo OBC_OperativeModeReq HV_Volt_Min_Thrsh HV_Volt_Max_Thrsh DC_Curr_Max_Thrsh ChargeEnable AC_Curr_Min_Thrsh AC_Curr_Max_Thrsh CurrentRequest VDCM_StsWldgReq VDCM_SessnStopReq VDCM_StsSWWldgReq MessageCounter_HYBRID_CHARGING__1DE MaxCurrentAllwd;
